VERSION "HNNBNNNYNNNNNNNNNNNNNNNNNNNNNNNNNNNNNNNNNN/4/%%%/4/'%**4NNN///"

NS_ :

BS_:

BU_: AAG BCM1 BCM2 ELV Gateway HDSG IEZS MFG MSBBR SAD SAD2 Schwerpanzer_Zusatz SitzMem_BFS SitzMem_FS SitzMem_HBFS SitzMem_HFS SitzMem_SR3 SpoilerSG TSG_BFS TSG_FS VSG VTS DK_Dummy

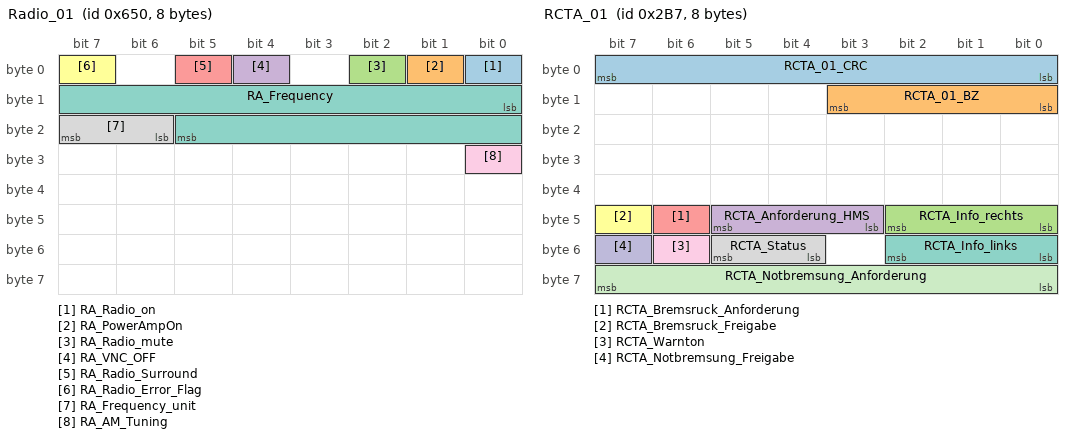
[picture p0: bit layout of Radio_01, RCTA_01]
BO_ 1616 Radio_01: 8 Gateway
 SG_ RA_Radio_on : 0|1@1+ (1,0) [0|1] ""  TSG_BFS,TSG_FS
 SG_ RA_PowerAmpOn : 1|1@1+ (1,0) [0|1] "" Vector__XXX
 SG_ RA_Radio_mute : 2|1@1+ (1,0) [0|1] "" Vector__XXX
 SG_ RA_VNC_OFF : 4|1@1+ (1,0) [0|1] "" Vector__XXX
 SG_ RA_Radio_Surround : 5|1@1+ (1,0) [0|1] "" Vector__XXX
 SG_ RA_Radio_Error_Flag : 7|1@1+ (1,0) [0|1] "" Vector__XXX
 SG_ RA_Frequency : 8|14@1+ (1,0) [0|16383] ""  HDSG,SAD,SAD2,SitzMem_BFS,SitzMem_FS,SitzMem_HBFS,SitzMem_HFS,TSG_BFS,TSG_FS
 SG_ RA_Frequency_unit : 22|2@1+ (1,0) [0|3] ""  HDSG,SAD,SAD2,SitzMem_BFS,SitzMem_FS,SitzMem_HBFS,SitzMem_HFS,TSG_BFS,TSG_FS
 SG_ RA_AM_Tuning : 24|1@1+ (1,0) [0|1] ""  HDSG,SAD,SAD2,SitzMem_BFS,SitzMem_FS,SitzMem_HBFS,SitzMem_HFS,TSG_BFS,TSG_FS

BO_ 695 RCTA_01: 8 Gateway
 SG_ RCTA_01_CRC : 0|8@1+ (1,0) [0|255] "" Vector__XXX
 SG_ RCTA_01_BZ : 8|4@1+ (1,0) [0|15] "" Vector__XXX
 SG_ RCTA_Info_rechts : 40|3@1+ (1,0) [0|7] ""  BCM1
 SG_ RCTA_Anforderung_HMS : 43|3@1+ (1,0) [0|7] "" Vector__XXX
 SG_ RCTA_Bremsruck_Anforderung : 46|1@1+ (1,0) [0|1] "" Vector__XXX
 SG_ RCTA_Bremsruck_Freigabe : 47|1@1+ (1,0) [0|1] "" Vector__XXX
 SG_ RCTA_Info_links : 48|3@1+ (1,0) [0|7] ""  BCM1
 SG_ RCTA_Status : 52|2@1+ (1,0) [0|3] ""  BCM1
 SG_ RCTA_Warnton : 54|1@1+ (1,0) [0|1] ""  BCM1
 SG_ RCTA_Notbremsung_Freigabe : 55|1@1+ (1,0) [0|1] "" Vector__XXX
 SG_ RCTA_Notbremsung_Anforderung : 56|8@1+ (0.078,-19.812) [-19.734|0] "Unit_MeterPerSeconSquar" Vector__XXX

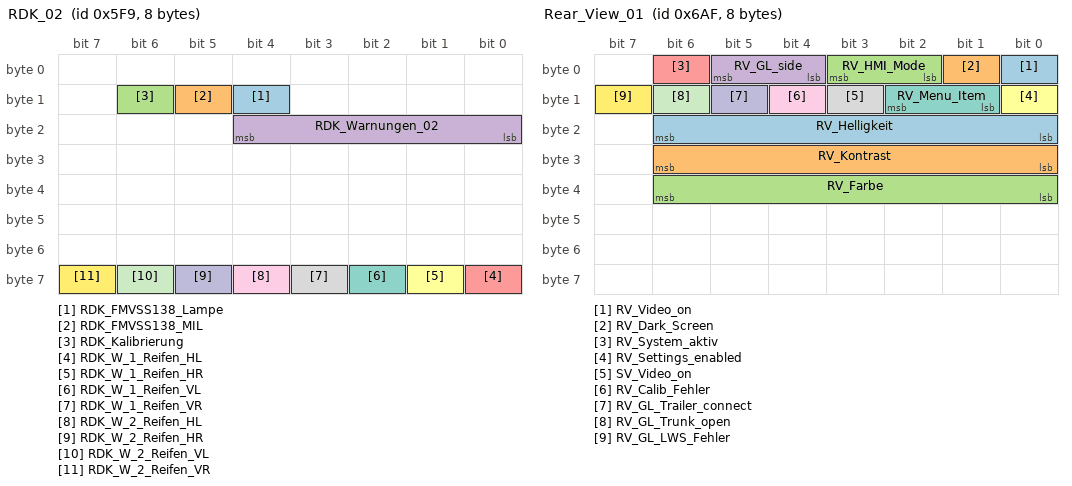
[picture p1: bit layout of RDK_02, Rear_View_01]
BO_ 1529 RDK_02: 8 Gateway
 SG_ RDK_FMVSS138_Lampe : 12|1@1+ (1,0) [0|1] "" Vector__XXX
 SG_ RDK_FMVSS138_MIL : 13|1@1+ (1,0) [0|1] "" Vector__XXX
 SG_ RDK_Kalibrierung : 14|1@1+ (1,0) [0|1] "" Vector__XXX
 SG_ RDK_Warnungen_02 : 16|5@1+ (1,0) [0|31] ""  VTS
 SG_ RDK_W_1_Reifen_HL : 56|1@1+ (1,0) [0|1] "" Vector__XXX
 SG_ RDK_W_1_Reifen_HR : 57|1@1+ (1,0) [0|1] "" Vector__XXX
 SG_ RDK_W_1_Reifen_VL : 58|1@1+ (1,0) [0|1] "" Vector__XXX
 SG_ RDK_W_1_Reifen_VR : 59|1@1+ (1,0) [0|1] "" Vector__XXX
 SG_ RDK_W_2_Reifen_HL : 60|1@1+ (1,0) [0|1] "" Vector__XXX
 SG_ RDK_W_2_Reifen_HR : 61|1@1+ (1,0) [0|1] "" Vector__XXX
 SG_ RDK_W_2_Reifen_VL : 62|1@1+ (1,0) [0|1] "" Vector__XXX
 SG_ RDK_W_2_Reifen_VR : 63|1@1+ (1,0) [0|1] "" Vector__XXX

BO_ 1711 Rear_View_01: 8 Gateway
 SG_ RV_Video_on : 0|1@1+ (1,0) [0|1] ""  BCM1
 SG_ RV_Dark_Screen : 1|1@1+ (1,0) [0|1] "" Vector__XXX
 SG_ RV_HMI_Mode : 2|2@1+ (1,0) [0|3] "" Vector__XXX
 SG_ RV_GL_side : 4|2@1+ (1,0) [0|3] "" Vector__XXX
 SG_ RV_System_aktiv : 6|1@1+ (1,0) [0|1] ""  BCM1
 SG_ RV_Settings_enabled : 8|1@1+ (1,0) [0|1] "" Vector__XXX
 SG_ RV_Menu_Item : 9|2@1+ (1,0) [0|3] "" Vector__XXX
 SG_ SV_Video_on : 11|1@1+ (1,0) [0|1] "" Vector__XXX
 SG_ RV_Calib_Fehler : 12|1@1+ (1,0) [0|1] "" Vector__XXX
 SG_ RV_GL_Trailer_connect : 13|1@1+ (1,0) [0|1] "" Vector__XXX
 SG_ RV_GL_Trunk_open : 14|1@1+ (1,0) [0|1] ""  BCM1
 SG_ RV_GL_LWS_Fehler : 15|1@1+ (1,0) [0|1] "" Vector__XXX
 SG_ RV_Helligkeit : 16|7@1+ (1,0) [0|100] "Unit_PerCent" Vector__XXX
 SG_ RV_Kontrast : 24|7@1+ (1,0) [0|100] "Unit_PerCent" Vector__XXX
 SG_ RV_Farbe : 32|7@1+ (1,0) [0|100] "Unit_PerCent" Vector__XXX

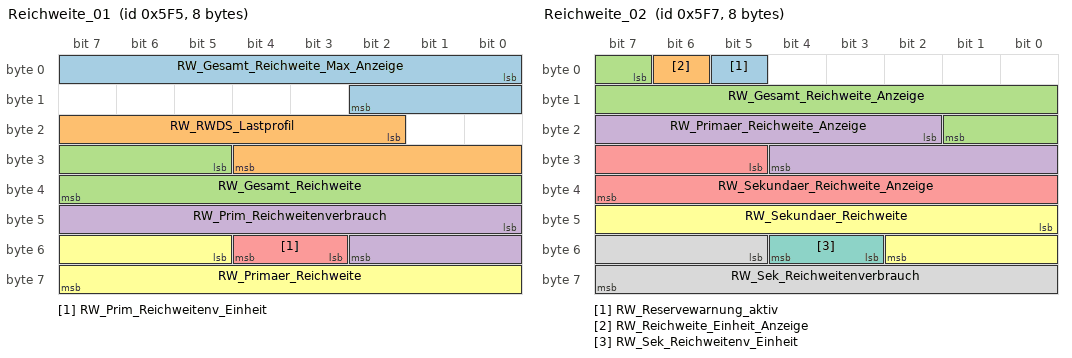
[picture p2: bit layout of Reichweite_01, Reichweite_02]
BO_ 1525 Reichweite_01: 8 Gateway
 SG_ RW_Gesamt_Reichweite_Max_Anzeige : 0|11@1+ (1,0) [0|2047] "" Vector__XXX
 SG_ RW_RWDS_Lastprofil : 18|11@1+ (1,0) [0|2045] "Unit_Amper" Vector__XXX
 SG_ RW_Gesamt_Reichweite : 29|11@1+ (1,0) [0|2044] "Unit_KiloMeter"  VTS
 SG_ RW_Prim_Reichweitenverbrauch : 40|11@1+ (0.1,0) [0|204.4] "Unit_None"  VTS
 SG_ RW_Prim_Reichweitenv_Einheit : 51|2@1+ (1,0) [0|3] ""  VTS
 SG_ RW_Primaer_Reichweite : 53|11@1+ (1,0) [0|2044] "Unit_KiloMeter"  VTS

BO_ 1527 Reichweite_02: 8 Gateway
 SG_ RW_Reservewarnung_aktiv : 5|1@1+ (1,0) [0|1] "" Vector__XXX
 SG_ RW_Reichweite_Einheit_Anzeige : 6|1@1+ (1,0) [0|1] ""  VTS
 SG_ RW_Gesamt_Reichweite_Anzeige : 7|11@1+ (1,0) [0|2044] ""  VTS
 SG_ RW_Primaer_Reichweite_Anzeige : 18|11@1+ (1,0) [0|2044] ""  VTS
 SG_ RW_Sekundaer_Reichweite_Anzeige : 29|11@1+ (1,0) [0|2044] ""  VTS
 SG_ RW_Sekundaer_Reichweite : 40|11@1+ (1,0) [0|2044] "Unit_KiloMeter"  VTS
 SG_ RW_Sek_Reichweitenv_Einheit : 51|2@1+ (1,0) [0|3] ""  VTS
 SG_ RW_Sek_Reichweitenverbrauch : 53|11@1+ (0.1,0) [0|204.4] "Unit_None"  VTS

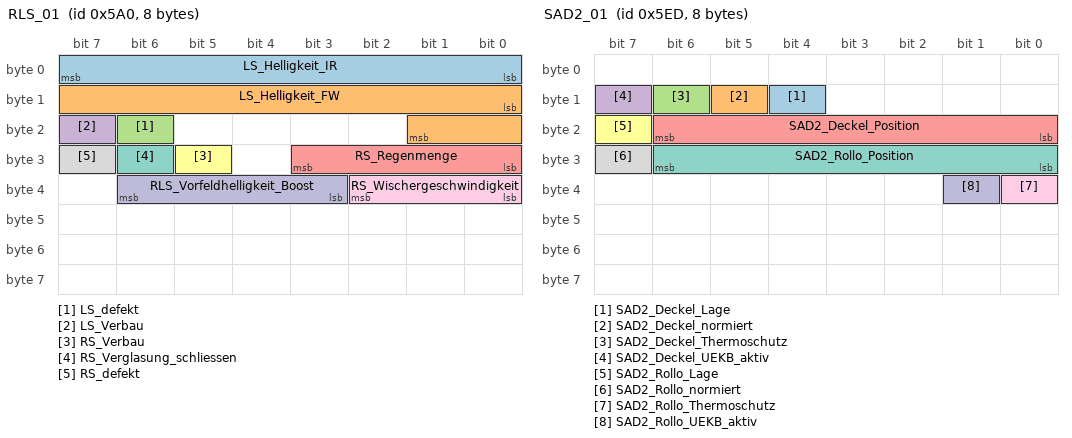
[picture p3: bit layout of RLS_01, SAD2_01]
BO_ 1440 RLS_01: 8 BCM1
 SG_ LS_Helligkeit_IR : 0|8@1+ (400,0) [0|101200] "Unit_Lux"  Gateway,MSBBR
 SG_ LS_Helligkeit_FW : 8|10@1+ (6,0) [0|6126] "Unit_Lux"  Gateway,MSBBR
 SG_ LS_defekt : 22|1@1+ (1,0) [0|1] ""  Gateway,MSBBR
 SG_ LS_Verbau : 23|1@1+ (1,0) [0|1] ""  Gateway
 SG_ RS_Regenmenge : 24|4@1+ (10,0) [0|100] "Unit_PerCent"  Gateway,MSBBR
 SG_ RS_Verbau : 29|1@1+ (1,0) [0|1] ""  Gateway
 SG_ RS_Verglasung_schliessen : 30|1@1+ (1,0) [0|1] ""  Gateway,SAD,SAD2,TSG_BFS,TSG_FS
 SG_ RS_defekt : 31|1@1+ (1,0) [0|1] ""  Gateway,MSBBR,SAD,SAD2,TSG_BFS,TSG_FS
 SG_ RS_Wischergeschwindigkeit : 32|3@1+ (1,0) [0|7] ""  Gateway,MSBBR
 SG_ RLS_Vorfeldhelligkeit_Boost : 35|4@1+ (1,0) [0|15] ""  Gateway,MSBBR

BO_ 1517 SAD2_01: 8 SAD2
 SG_ SAD2_Deckel_Lage : 12|1@1+ (1,0) [0|1] ""  Gateway,SAD
 SG_ SAD2_Deckel_normiert : 13|1@1+ (1,0) [0|1] ""  BCM2,Gateway,SAD
 SG_ SAD2_Deckel_Thermoschutz : 14|1@1+ (1,0) [0|1] ""  BCM2,Gateway,SAD
 SG_ SAD2_Deckel_UEKB_aktiv : 15|1@1+ (1,0) [0|1] ""  BCM2,Gateway,SAD
 SG_ SAD2_Deckel_Position : 16|7@1+ (1,0) [0|100] "Unit_PerCent"  BCM2,Gateway,SAD
 SG_ SAD2_Rollo_Lage : 23|1@1+ (1,0) [0|1] ""  Gateway,SAD
 SG_ SAD2_Rollo_Position : 24|7@1+ (1,0) [0|100] "Unit_PerCent"  Gateway,SAD
 SG_ SAD2_Rollo_normiert : 31|1@1+ (1,0) [0|1] ""  BCM2,Gateway,SAD
 SG_ SAD2_Rollo_Thermoschutz : 32|1@1+ (1,0) [0|1] ""  BCM2,Gateway,SAD
 SG_ SAD2_Rollo_UEKB_aktiv : 33|1@1+ (1,0) [0|1] ""  BCM2,Gateway,SAD

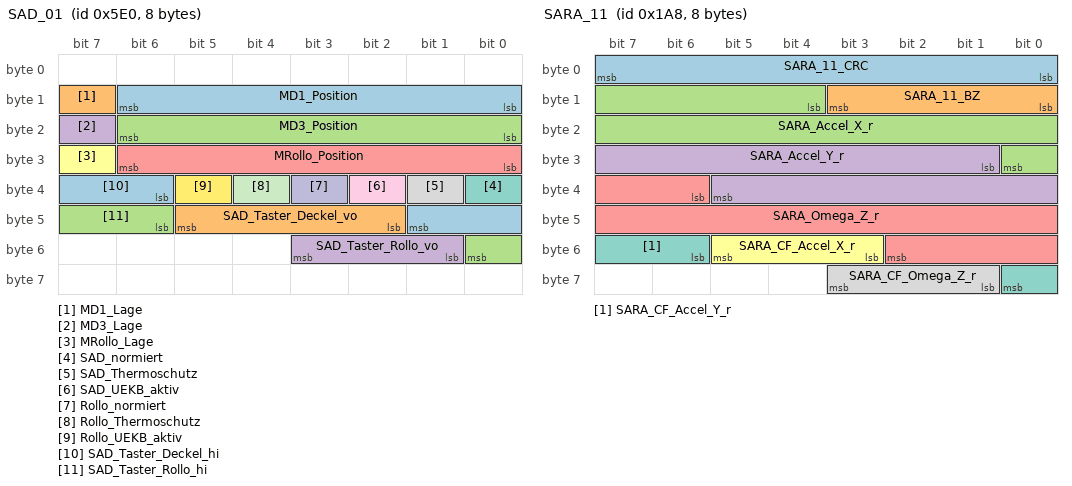
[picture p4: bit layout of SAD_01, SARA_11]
BO_ 1504 SAD_01: 8 SAD
 SG_ MD1_Position : 8|7@1+ (1,0) [0|100] "Unit_PerCent"  BCM2,Gateway,SAD2,SpoilerSG,VTS
 SG_ MD1_Lage : 15|1@1+ (1,0) [0|1] ""  BCM1,Gateway,SAD2,SpoilerSG,VTS
 SG_ MD3_Position : 16|7@1+ (1,0) [0|100] "Unit_PerCent"  BCM2,Gateway,SAD2,SpoilerSG,VTS
 SG_ MD3_Lage : 23|1@1+ (1,0) [0|1] ""  Gateway,SAD2,SpoilerSG,VTS
 SG_ MRollo_Position : 24|7@1+ (1,0) [0|100] "Unit_PerCent"  Gateway,SAD2,VTS
 SG_ MRollo_Lage : 31|1@1+ (1,0) [0|1] ""  Gateway,SAD2,VTS
 SG_ SAD_normiert : 32|1@1+ (1,0) [0|1] ""  BCM2,Gateway,SAD2,VTS
 SG_ SAD_Thermoschutz : 33|1@1+ (1,0) [0|1] ""  BCM2,Gateway,SAD2
 SG_ SAD_UEKB_aktiv : 34|1@1+ (1,0) [0|1] ""  BCM2,Gateway,SAD2
 SG_ Rollo_normiert : 35|1@1+ (1,0) [0|1] ""  BCM2,Gateway,SAD2,VTS
 SG_ Rollo_Thermoschutz : 36|1@1+ (1,0) [0|1] ""  BCM2,Gateway,SAD2
 SG_ Rollo_UEKB_aktiv : 37|1@1+ (1,0) [0|1] ""  BCM2,Gateway,SAD2
 SG_ SAD_Taster_Deckel_hi : 38|4@1+ (1,0) [0|15] ""  Gateway,SAD2
 SG_ SAD_Taster_Deckel_vo : 42|4@1+ (1,0) [0|15] ""  Gateway,SAD2
 SG_ SAD_Taster_Rollo_hi : 46|3@1+ (1,0) [0|7] ""  Gateway,SAD2
 SG_ SAD_Taster_Rollo_vo : 49|3@1+ (1,0) [0|7] ""  Gateway,SAD2

BO_ 424 SARA_11: 8 Gateway
 SG_ SARA_11_CRC : 0|8@1+ (1,0) [0|255] ""  BCM1
 SG_ SARA_11_BZ : 8|4@1+ (1,0) [0|15] ""  BCM1
 SG_ SARA_Accel_X_r : 12|13@1+ (0.16,-655.36) [-655.2|655.04] "Unit_MeterPerSeconSquar"  BCM1,HDSG,MFG,MSBBR,SitzMem_BFS,SitzMem_FS,SitzMem_HBFS,SitzMem_HFS
 SG_ SARA_Accel_Y_r : 25|13@1+ (0.16,-655.36) [-655.2|655.04] "Unit_MeterPerSeconSquar"  BCM1,HDSG,SitzMem_BFS,SitzMem_FS,SitzMem_HBFS,SitzMem_HFS
 SG_ SARA_Omega_Z_r : 38|13@1+ (0.08,-327.68) [-327.6|327.52] "Unit_DegreOfArcPerSecon"  BCM1
 SG_ SARA_CF_Accel_X_r : 51|3@1+ (1,0) [0|7] ""  BCM1,HDSG,MFG,MSBBR
 SG_ SARA_CF_Accel_Y_r : 54|3@1+ (1,0) [0|7] ""  BCM1,HDSG
 SG_ SARA_CF_Omega_Z_r : 57|3@1+ (1,0) [0|7] ""  BCM1

BO_ 1522 Sensorik_Dimmung_01: 2 Gateway
 SG_ KBI_Phototransistor : 0|8@1+ (1,0) [0|253] ""  BCM1
 SG_ KBI_Dimmpoti : 8|7@1+ (1,0) [0|100] "Unit_PerCent"  BCM1

BO_ 1363 Sitzmemo_SR3_01: 8 SitzMem_SR3
 SG_ SR3_Status_Lehne_Links : 12|1@1+ (1,0) [0|1] ""  Gateway
 SG_ SR3_Status_Lehne_Rechts : 13|1@1+ (1,0) [0|1] ""  Gateway

BO_ 980 SMLS_01: 8 Gateway
 SG_ SMLS_01_CRC : 0|8@1+ (1,0) [0|255] ""  BCM1,BCM2
 SG_ SMLS_01_BZ : 8|4@1+ (1,0) [0|15] ""  BCM1,BCM2
 SG_ BH_Blinker_li : 12|1@1+ (1,0) [0|1] ""  BCM1,BCM2
 SG_ BH_Blinker_re : 13|1@1+ (1,0) [0|1] ""  BCM1,BCM2
 SG_ BH_Lichthupe : 14|1@1+ (1,0) [0|1] ""  BCM1
 SG_ BH_Fernlicht : 15|1@1+ (1,0) [0|1] ""  BCM1
 SG_ WH_Tipwischen : 16|1@1+ (1,0) [0|1] ""  BCM1
 SG_ WH_Intervall : 17|1@1+ (1,0) [0|1] ""  BCM1
 SG_ WH_WischerStufe1 : 18|1@1+ (1,0) [0|1] ""  BCM1
 SG_ WH_WischerStufe2 : 19|1@1+ (1,0) [0|1] ""  BCM1
 SG_ WH_Frontwaschen : 20|1@1+ (1,0) [0|1] ""  BCM1
 SG_ WH_Heckintervall : 21|1@1+ (1,0) [0|1] ""  BCM1
 SG_ WH_Heckwaschen : 22|1@1+ (1,0) [0|1] ""  BCM1
 SG_ WH_Intervallstufen : 23|4@1+ (1,0) [0|15] ""  BCM1
 SG_ FAS_Taster : 27|1@1+ (1,0) [0|1] "" Vector__XXX
 SG_ FAS_Taster_Fehler : 28|1@1+ (1,0) [0|1] "" Vector__XXX
 SG_ SMLS_Hupe : 29|1@1+ (1,0) [0|1] ""  BCM1,MFG
 SG_ LRH_on_off : 30|2@1+ (1,0) [0|3] "" Vector__XXX
 SG_ LRH_aktiv : 40|1@1+ (1,0) [0|1] "" Vector__XXX
 SG_ SMLS_P_verriegelt_plausibel : 43|1@1+ (1,0) [0|1] "" Vector__XXX
 SG_ WH_SRA : 44|1@1+ (1,0) [0|1] ""  BCM1
 SG_ WH_Wischer_Fehler : 45|1@1+ (1,0) [0|1] ""  BCM1
 SG_ BH_Blinker_Fehler : 46|1@1+ (1,0) [0|1] ""  BCM2

BO_ 1467 SoSe_01: 8 BCM1
 SG_ SoSe_SunInt_2D_Li : 0|8@1+ (5,0) [0|1200] "Unit_WattPerMeterSquar"  Gateway
 SG_ SoSe_SunInt_2D_Re : 8|8@1+ (5,0) [0|1200] "Unit_WattPerMeterSquar"  Gateway

BO_ 1710 Spiegel_01: 8 TSG_FS
 SG_ SP_FT_oben : 0|1@1+ (1,0) [0|1] ""  Gateway,MFG,TSG_BFS
 SG_ SP_FT_unten : 1|1@1+ (1,0) [0|1] ""  Gateway,MFG,TSG_BFS
 SG_ SP_FT_links : 2|1@1+ (1,0) [0|1] ""  Gateway,MFG,TSG_BFS
 SG_ SP_FT_rechts : 3|1@1+ (1,0) [0|1] ""  Gateway,MFG,TSG_BFS
 SG_ SP_BT_oben : 4|1@1+ (1,0) [0|1] ""  Gateway,MFG,TSG_BFS
 SG_ SP_BT_unten : 5|1@1+ (1,0) [0|1] ""  Gateway,MFG,TSG_BFS
 SG_ SP_BT_links : 6|1@1+ (1,0) [0|1] ""  Gateway,MFG,TSG_BFS
 SG_ SP_BT_rechts : 7|1@1+ (1,0) [0|1] ""  Gateway,MFG,TSG_BFS
 SG_ SP_abklappen : 8|1@1+ (1,0) [0|1] ""  Gateway,MFG,TSG_BFS
 SG_ SP_anklappen : 9|1@1+ (1,0) [0|1] ""  Gateway,MFG,TSG_BFS
 SG_ SP_normieren : 10|1@1+ (1,0) [0|1] ""  Gateway,MFG,TSG_BFS
 SG_ SP_Hzg_Taster : 12|1@1+ (1,0) [0|1] ""  Gateway,MFG,TSG_BFS
 SG_ SP_S_oben : 16|1@1+ (1,0) [0|1] ""  Gateway,TSG_BFS
 SG_ SP_S_unten : 17|1@1+ (1,0) [0|1] ""  Gateway,TSG_BFS
 SG_ SP_S_links : 18|1@1+ (1,0) [0|1] ""  Gateway,TSG_BFS
 SG_ SP_S_rechts : 19|1@1+ (1,0) [0|1] ""  Gateway,TSG_BFS
 SG_ SP_Auswahl_li : 20|1@1+ (1,0) [0|1] ""  Gateway,MFG,TSG_BFS
 SG_ SP_Auswahl_re : 21|1@1+ (1,0) [0|1] ""  Gateway,MFG,TSG_BFS
 SG_ SP_ARA_Status : 22|1@1+ (1,0) [0|1] ""  Gateway
 SG_ SP_S_Klappen : 23|1@1+ (1,0) [0|1] ""  Gateway,MFG,TSG_BFS
 SG_ SP_Verstellschalter_Fehler : 24|1@1+ (1,0) [0|1] ""  BCM1,Gateway

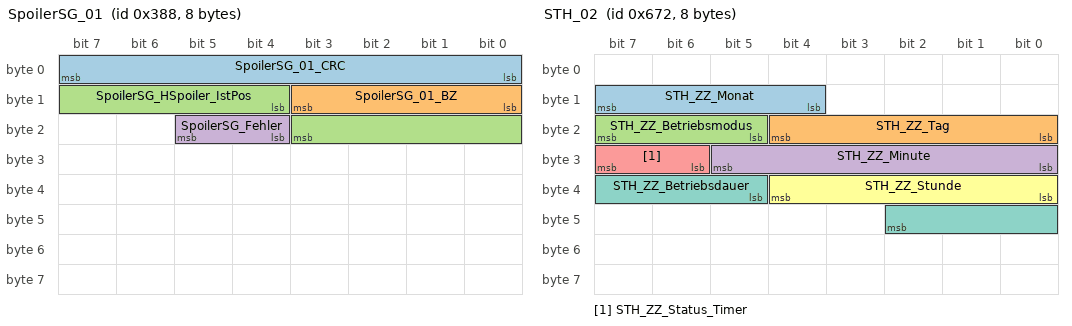
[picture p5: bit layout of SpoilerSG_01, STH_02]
BO_ 904 SpoilerSG_01: 8 SpoilerSG
 SG_ SpoilerSG_01_CRC : 0|8@1+ (1,0) [0|255] ""  Gateway
 SG_ SpoilerSG_01_BZ : 8|4@1+ (1,0) [0|15] ""  Gateway
 SG_ SpoilerSG_HSpoiler_IstPos : 12|8@1+ (4,0) [0|1012] ""  BCM2,Gateway
 SG_ SpoilerSG_Fehler : 20|2@1+ (1,0) [0|3] ""  Gateway

BO_ 1313 STH_01: 8 Gateway
 SG_ STH_Funk_ein : 0|1@1+ (1,0) [0|1] "" Vector__XXX
 SG_ STH_Funk_aus : 1|1@1+ (1,0) [0|1] "" Vector__XXX
 SG_ STH_Zusatzheizung : 2|1@1+ (1,0) [0|1] "" Vector__XXX
 SG_ STH_LED : 3|1@1+ (1,0) [0|1] ""  VTS
 SG_ STH_Pumpe_ein : 4|1@1+ (1,0) [0|1] "" Vector__XXX
 SG_ STH_Geblaese : 5|1@1+ (1,0) [0|1] "" Vector__XXX
 SG_ STH_EKP_Anst : 6|1@1+ (1,0) [0|1] "" Vector__XXX
 SG_ STH_Start_folgt : 7|1@1+ (1,0) [0|1] "" Vector__XXX
 SG_ STH_Ventiloeffnungszeit : 8|6@1+ (1,0) [0|63] "Unit_Minut" Vector__XXX
 SG_ STH_Ventil_Status : 14|1@1+ (1,0) [0|1] "" Vector__XXX
 SG_ STH_Fehler_ElWaPu : 15|1@1+ (1,0) [0|1] "" Vector__XXX
 SG_ STH_Waermeeintrag : 16|6@1+ (1,0) [0|63] "" Vector__XXX
 SG_ STH_Pumpen_Anf_extern : 22|1@1+ (1,0) [0|1] "" Vector__XXX
 SG_ STH_KVS : 24|13@1+ (1,0) [0|8191] "Unit_MilliLiter" Vector__XXX
 SG_ STH_Fehlerstatus : 37|3@1+ (1,0) [0|7] ""  VTS
 SG_ STH_Heizleistung : 40|8@1+ (1,0) [0|255] "" Vector__XXX
 SG_ STH_Wassertemp : 48|8@1+ (0.75,-40) [-40|142.25] "Unit_DegreCelsi" Vector__XXX
 SG_ STH_Texte : 56|3@1+ (1,0) [0|7] "" Vector__XXX
 SG_ STH_Motorvorwaermung : 59|1@1+ (1,0) [0|1] "" Vector__XXX
 SG_ STH_Servicemode : 60|1@1+ (1,0) [0|1] "" Vector__XXX
 SG_ STH_war_aktiv : 61|1@1+ (1,0) [0|1] "" Vector__XXX
 SG_ STH_KVS_Ueberlauf : 62|1@1+ (1,0) [0|1] "" Vector__XXX

BO_ 1650 STH_02: 8 Gateway
 SG_ STH_ZZ_Monat : 12|4@1+ (1,0) [1|12] ""  VTS
 SG_ STH_ZZ_Tag : 16|5@1+ (1,0) [1|31] "Unit_Day"  VTS
 SG_ STH_ZZ_Betriebsmodus : 21|3@1+ (1,0) [0|7] ""  VTS
 SG_ STH_ZZ_Minute : 24|6@1+ (1,0) [0|59] ""  VTS
 SG_ STH_ZZ_Status_Timer : 30|2@1+ (1,0) [0|3] ""  VTS
 SG_ STH_ZZ_Stunde : 32|5@1+ (1,0) [0|23] ""  VTS
 SG_ STH_ZZ_Betriebsdauer : 37|6@1+ (1,0) [0|63] "Unit_Minut"  VTS

BO_ 1172 STS_01: 8 VTS
 SG_ STS_01_CRC : 0|8@1+ (1,0) [0|255] ""  BCM2,Gateway
 SG_ STS_01_BZ : 8|4@1+ (1,0) [0|15] ""  BCM2,Gateway
 SG_ STS_Car_not_under_theft : 12|1@1+ (1,0) [0|1] ""  Gateway
 SG_ STS_Car_under_theft : 13|1@1+ (1,0) [0|1] ""  Gateway
 SG_ STS_Anlassersperre : 15|1@1+ (1,0) [0|1] ""  BCM2,Gateway
 SG_ STS_Typencodierung : 16|5@1+ (1,0) [0|31] ""  Gateway
 SG_ STS_LIN_aktiv : 23|1@1+ (1,0) [0|1] ""  Gateway
 SG_ STS_Standlicht : 24|1@1+ (1,0) [0|1] ""  BCM1,Gateway
 SG_ STS_Fahrlicht : 25|1@1+ (1,0) [0|1] ""  BCM1,Gateway
 SG_ STS_Alarm_still : 26|1@1+ (1,0) [0|1] ""  Gateway
 SG_ STS_Texte : 27|4@1+ (1,0) [0|15] ""  Gateway
 SG_ STS_Laderelais : 38|1@1+ (1,0) [0|1] ""  Gateway
 SG_ STS_Summer : 48|1@1+ (1,0) [0|1] ""  Gateway
 SG_ STS_Alarm_Blinker : 50|1@1+ (1,0) [0|1] ""  BCM2,Gateway
 SG_ STS_Notstart : 51|1@1+ (1,0) [0|1] ""  Gateway
 SG_ STS_Signalhorn : 55|1@1+ (1,0) [0|1] ""  BCM1,Gateway
 SG_ STS_Leerlaufschaltung : 56|1@1+ (1,0) [0|1] ""  Gateway

BO_ 783 SWA_01: 8 Gateway
 SG_ SWA_01_CRC : 0|8@1+ (1,0) [0|255] "" Vector__XXX
 SG_ SWA_01_BZ : 8|4@1+ (1,0) [0|15] "" Vector__XXX
 SG_ SWA_Anzeigen : 12|4@1+ (1,0) [0|15] "" Vector__XXX
 SG_ SWA_Blindheit_erkannt : 16|1@1+ (1,0) [0|1] "" Vector__XXX
 SG_ SWA_rel_Nichtverf : 17|1@1+ (1,0) [0|1] "" Vector__XXX
 SG_ SWA_rel_Fehler : 18|1@1+ (1,0) [0|1] "" Vector__XXX
 SG_ SWA_Sta_aktiv : 19|1@1+ (1,0) [0|1] "" Vector__XXX
 SG_ SWA_Sta_passiv : 20|1@1+ (1,0) [0|1] "" Vector__XXX
 SG_ SWA_FT_RueckLED : 21|1@1+ (1,0) [0|1] ""  BCM1,TSG_FS
 SG_ ASW_Status : 22|2@1+ (1,0) [0|3] ""  TSG_BFS,TSG_FS
 SG_ SWA_Standziele_li : 24|1@1+ (1,0) [0|1] "" Vector__XXX
 SG_ SWA_Kolonne_li : 25|1@1+ (1,0) [0|1] "" Vector__XXX
 SG_ SWA_Infostufe_SWA_li : 26|1@1+ (1,0) [0|1] "" Vector__XXX
 SG_ SWA_Warnung_SWA_li : 27|1@1+ (1,0) [0|1] "" Vector__XXX
 SG_ ASW_Warnung_FS : 28|1@1+ (1,0) [0|1] ""  TSG_BFS,TSG_FS
 SG_ ASW_Warnung_BFS : 29|1@1+ (1,0) [0|1] ""  TSG_BFS,TSG_FS
 SG_ ASW_Kombitexte : 30|3@1+ (1,0) [0|7] "" Vector__XXX
 SG_ SWA_Kolonne_mi : 33|1@1+ (1,0) [0|1] "" Vector__XXX
 SG_ SWA_Standziele_re : 40|1@1+ (1,0) [0|1] "" Vector__XXX
 SG_ SWA_Kolonne_re : 41|1@1+ (1,0) [0|1] "" Vector__XXX
 SG_ SWA_Infostufe_SWA_re : 42|1@1+ (1,0) [0|1] "" Vector__XXX
 SG_ SWA_Warnung_SWA_re : 43|1@1+ (1,0) [0|1] "" Vector__XXX
 SG_ HRE_Anzeigetexte : 44|4@1+ (1,0) [0|15] "" Vector__XXX
 SG_ SWA_Gischtzaehler : 48|7@1+ (1,0) [0|100] "Unit_PerCent"  MSBBR
 SG_ Heckradar_Kombitexte : 56|5@1+ (1,0) [0|31] "" Vector__XXX
 SG_ RCTA_Kombitexte : 61|3@1+ (1,0) [0|7] "" Vector__XXX

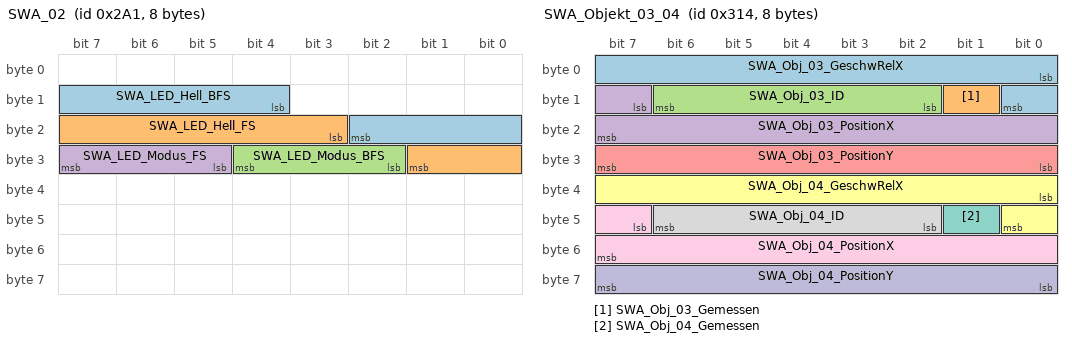
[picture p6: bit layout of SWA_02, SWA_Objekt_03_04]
BO_ 673 SWA_02: 8 Gateway
 SG_ SWA_LED_Hell_BFS : 12|7@1+ (1,0) [0|100] "Unit_PerCent"  TSG_BFS
 SG_ SWA_LED_Hell_FS : 19|7@1+ (1,0) [0|100] "Unit_PerCent"  TSG_FS
 SG_ SWA_LED_Modus_BFS : 26|3@1+ (1,0) [0|7] ""  TSG_BFS
 SG_ SWA_LED_Modus_FS : 29|3@1+ (1,0) [0|7] ""  TSG_FS

BO_ 788 SWA_Objekt_03_04: 8 Gateway
 SG_ SWA_Obj_03_GeschwRelX : 0|9@1+ (0.25,-37.5) [-37.5|90] "Unit_MeterPerSecon" Vector__XXX
 SG_ SWA_Obj_03_Gemessen : 9|1@1+ (1,0) [0|1] "" Vector__XXX
 SG_ SWA_Obj_03_ID : 10|5@1+ (1,0) [1|30] "" Vector__XXX
 SG_ SWA_Obj_03_PositionX : 15|9@1+ (0.25,-102.5) [-102.5|25] "Unit_Meter"  MSBBR
 SG_ SWA_Obj_03_PositionY : 24|8@1+ (0.125,-16) [-16|15.75] "Unit_Meter" Vector__XXX
 SG_ SWA_Obj_04_GeschwRelX : 32|9@1+ (0.25,-37.5) [-37.5|90] "Unit_MeterPerSecon" Vector__XXX
 SG_ SWA_Obj_04_Gemessen : 41|1@1+ (1,0) [0|1] "" Vector__XXX
 SG_ SWA_Obj_04_ID : 42|5@1+ (1,0) [1|30] "" Vector__XXX
 SG_ SWA_Obj_04_PositionX : 47|9@1+ (0.25,-102.5) [-102.5|25] "Unit_Meter"  MSBBR
 SG_ SWA_Obj_04_PositionY : 56|8@1+ (0.125,-16) [-16|15.75] "Unit_Meter" Vector__XXX

BO_ 1413 Systeminfo_01: 8 Gateway
 SG_ SI_Sammel_SG_Fehler : 0|6@1+ (1,0) [0|60] ""  BCM2
 SG_ SI_Diagnose_Aktiv : 7|1@1+ (1,0) [0|1] ""  BCM2
 SG_ SI_QRS_Mode : 8|1@1+ (1,0) [0|1] ""  AAG,BCM1,BCM2,HDSG,IEZS,SAD,SAD2,SitzMem_BFS,SitzMem_FS,SitzMem_HBFS,SitzMem_HFS,SitzMem_SR3,TSG_BFS,TSG_FS
 SG_ SI_T_Mode : 9|1@1+ (1,0) [0|1] ""  BCM1,BCM2,HDSG,IEZS,SAD,SAD2,SitzMem_BFS,SitzMem_FS,SitzMem_HBFS,SitzMem_HFS,SitzMem_SR3,SpoilerSG,TSG_BFS,TSG_FS
 SG_ SI_NWDF : 10|1@1+ (1,0) [0|1] ""  AAG,BCM1,BCM2,ELV,HDSG,IEZS,MFG,SAD,SAD2,SitzMem_BFS,SitzMem_FS,SitzMem_HBFS,SitzMem_HFS,SitzMem_SR3,TSG_BFS,TSG_FS,VSG,VTS
 SG_ SI_NWDF_gueltig : 11|1@1+ (1,0) [0|1] ""  AAG,BCM1,BCM2,ELV,HDSG,IEZS,MFG,SAD,SAD2,SitzMem_BFS,SitzMem_FS,SitzMem_HBFS,SitzMem_HFS,SitzMem_SR3,TSG_BFS,TSG_FS,VSG,VTS
 SG_ SI_Sammelfehler : 12|1@1+ (1,0) [0|1] "" Vector__XXX
 SG_ GW_KD_Fehler : 13|1@1+ (1,0) [0|1] "" Vector__XXX
 SG_ SI_T_Schutz : 14|1@1+ (1,0) [0|1] ""  BCM1,BCM2,SAD,SAD2,TSG_BFS,TSG_FS
 SG_ SI_BUS_01 : 16|1@1+ (1,0) [0|1] ""  BCM2
 SG_ SI_BUS_02 : 17|1@1+ (1,0) [0|1] ""  VTS
 SG_ SI_BUS_03 : 18|1@1+ (1,0) [0|1] "" Vector__XXX
 SG_ SI_BUS_04 : 19|1@1+ (1,0) [0|1] ""  BCM2,HDSG
 SG_ SI_BUS_05 : 20|1@1+ (1,0) [0|1] "" Vector__XXX
 SG_ SI_BUS_06 : 21|1@1+ (1,0) [0|1] ""  BCM2
 SG_ SI_BUS_07 : 22|1@1+ (1,0) [0|1] "" Vector__XXX
 SG_ SI_BUS_08 : 23|1@1+ (1,0) [0|1] "" Vector__XXX
 SG_ SI_BUS_09 : 24|1@1+ (1,0) [0|1] "" Vector__XXX
 SG_ SI_BUS_10 : 25|1@1+ (1,0) [0|1] ""  AAG,BCM2,HDSG
 SG_ SI_BUS_11 : 26|1@1+ (1,0) [0|1] "" Vector__XXX
 SG_ SI_BUS_12 : 27|1@1+ (1,0) [0|1] "" Vector__XXX
 SG_ SI_BUS_13 : 28|1@1+ (1,0) [0|1] "" Vector__XXX
 SG_ SI_BUS_14 : 29|1@1+ (1,0) [0|1] "" Vector__XXX
 SG_ SI_BUS_15 : 30|1@1+ (1,0) [0|1] "" Vector__XXX
 SG_ SI_Bus_Identifikation : 32|8@1+ (1,0) [0|255] "" Vector__XXX
 SG_ SI_CAB : 40|24@1+ (1,0) [0|16777215] "" Vector__XXX

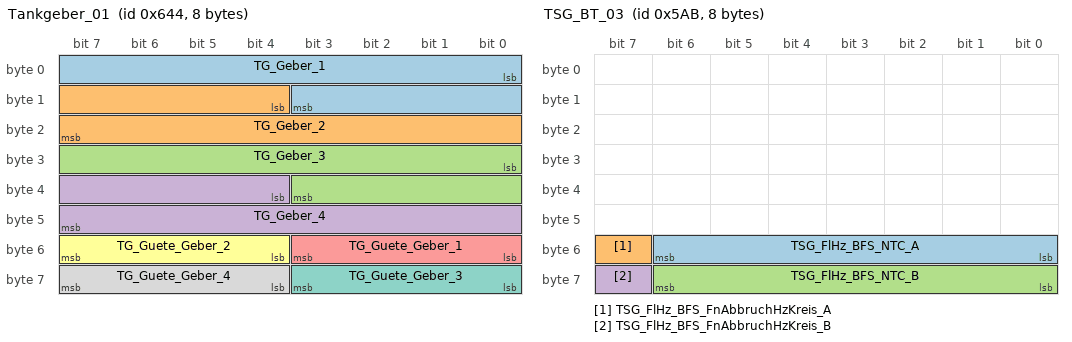
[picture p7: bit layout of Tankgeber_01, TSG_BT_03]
BO_ 1604 Tankgeber_01: 8 BCM2
 SG_ TG_Geber_1 : 0|12@1+ (1,0) [1|4094] "Unit_Ohm"  Gateway
 SG_ TG_Geber_2 : 12|12@1+ (1,0) [1|4094] "Unit_Ohm"  Gateway
 SG_ TG_Geber_3 : 24|12@1+ (1,0) [1|4094] "Unit_Ohm"  Gateway
 SG_ TG_Geber_4 : 36|12@1+ (1,0) [1|4094] "Unit_Ohm"  Gateway
 SG_ TG_Guete_Geber_1 : 48|4@1+ (1,0) [0|15] ""  Gateway
 SG_ TG_Guete_Geber_2 : 52|4@1+ (1,0) [0|15] ""  Gateway
 SG_ TG_Guete_Geber_3 : 56|4@1+ (1,0) [0|15] ""  Gateway
 SG_ TG_Guete_Geber_4 : 60|4@1+ (1,0) [0|15] ""  Gateway

BO_ 977 TSG_BT_01: 8 TSG_BFS
 SG_ BT_Tuer_geoeffnet : 0|1@1+ (1,0) [0|1] ""  BCM2,Gateway,IEZS,MFG,SitzMem_BFS,VTS
 SG_ BT_verriegelt : 1|1@1+ (1,0) [0|1] ""  BCM2,Gateway,MFG,VTS
 SG_ BT_gesafet : 2|1@1+ (1,0) [0|1] ""  BCM2,Gateway,MFG,VTS
 SG_ BT_Schluesselschalter_auf : 3|1@1+ (1,0) [0|1] ""  BCM2,Gateway,MFG
 SG_ BT_Schluesselschalter_zu : 4|1@1+ (1,0) [0|1] ""  BCM2,Gateway,MFG
 SG_ BT_Unlock_Taster : 5|1@1+ (1,0) [0|1] ""  BCM2,Gateway,MFG,TSG_FS
 SG_ BT_Lock_Taster : 6|1@1+ (1,0) [0|1] ""  BCM2,Gateway,MFG,TSG_FS
 SG_ BT_Sperrklinke : 7|1@1+ (1,0) [0|1] ""  BCM2,Gateway,MFG
 SG_ BT_TAG_betaetigt : 8|1@1+ (1,0) [0|1] ""  Gateway,MFG,TSG_FS,VTS
 SG_ BT_TIG_betaetigt : 9|1@1+ (1,0) [0|1] ""  BCM1,BCM2,Gateway,MFG,TSG_FS
 SG_ BT_EC_Spiegel_Helligkeit : 10|5@1+ (3.125,0) [0|96.875] "Unit_PerCent"  Gateway,MFG,TSG_FS
 SG_ BT_Sp_Heizung_Anf : 15|1@1+ (100,0) [0|100] "Unit_PerCent"  Gateway
 SG_ BT_Tuer_Status : 16|2@1+ (1,0) [0|3] ""  Gateway,TSG_FS
 SG_ BT_TSG_hinten_verbaut : 18|1@1+ (1,0) [0|1] ""  Gateway
 SG_ BT_Sp_Blk_def : 19|1@1+ (1,0) [0|1] ""  BCM1,Gateway,MFG
 SG_ BT_FH_S_ManHoch : 20|1@1+ (1,0) [0|1] ""  BCM2,Gateway,MFG
 SG_ BT_FH_S_AutoHoch : 21|1@1+ (1,0) [0|1] ""  BCM2,Gateway,MFG
 SG_ BT_FH_S_ManTief : 22|1@1+ (1,0) [0|1] ""  BCM2,Gateway,MFG
 SG_ BT_FH_S_AutoTief : 23|1@1+ (1,0) [0|1] ""  BCM2,Gateway,MFG
 SG_ BT_FH_Oeffnung : 24|8@1+ (0.5,0) [0|100] "Unit_PerCent"  BCM1,BCM2,Gateway,MFG,SAD,SAD2,VSG,VTS
 SG_ BT_FH_Bew_hoch : 32|1@1+ (1,0) [0|1] ""  Gateway,MFG,TSG_FS,VSG
 SG_ BT_FH_Bew_tief : 33|1@1+ (1,0) [0|1] ""  Gateway,MFG,TSG_FS
 SG_ BT_FH_Fang : 34|1@1+ (1,0) [0|1] ""  Gateway,MFG
 SG_ BT_FH_Block : 35|1@1+ (1,0) [0|1] ""  Gateway,MFG
 SG_ BT_FH_Thermo : 36|1@1+ (1,0) [0|1] ""  BCM2,Gateway,MFG
 SG_ BT_UEKB_aktiviert : 37|1@1+ (1,0) [0|1] ""  BCM2,Gateway,MFG
 SG_ BT_Kisi_Fehler : 38|1@1+ (1,0) [0|1] ""  Gateway,TSG_FS
 SG_ BT_FH_normiert : 39|1@1+ (1,0) [0|1] ""  BCM2,Gateway,MFG,TSG_FS,VSG,VTS
 SG_ BT_Schliesstaster : 40|1@1+ (1,0) [0|1] ""  Gateway
 SG_ BT_Zuziehhilfe_aktiv : 41|1@1+ (1,0) [0|1] ""  Gateway
 SG_ BT_SP_ausgerastet : 42|1@1+ (1,0) [0|1] ""  Gateway,MFG,TSG_FS,VTS
 SG_ BT_SP_lr_aktiv : 43|1@1+ (1,0) [0|1] ""  Gateway,MFG,TSG_FS
 SG_ BT_SP_ht_aktiv : 44|1@1+ (1,0) [0|1] ""  Gateway,MFG,TSG_FS
 SG_ BT_SP_Heizung_aktiv : 45|1@1+ (1,0) [0|1] ""  Gateway
 SG_ BT_Oben_Block_erw : 46|1@1+ (1,0) [0|1] ""  Gateway,MFG,TSG_FS
 SG_ BT_Unten_Block_erw : 47|1@1+ (1,0) [0|1] ""  Gateway,MFG,TSG_FS
 SG_ BT_SP_Heizung_Status : 55|1@1+ (1,0) [0|1] ""  BCM1,Gateway,MFG
 SG_ ASW_Warnung_aktiv_BFS : 56|1@1+ (1,0) [0|1] ""  BCM1,Gateway
 SG_ BT_FH_Pos_oben : 57|1@1+ (1,0) [0|1] ""  Gateway,MFG,VSG
 SG_ BT_Tuerschloss_defekt : 58|1@1+ (1,0) [0|1] ""  BCM2,Gateway
 SG_ BT_Tuerschloss_verrieg_nicht : 59|1@1+ (1,0) [0|1] ""  Gateway
 SG_ BT_Lock_Taster_inv : 60|1@1+ (1,0) [0|1] ""  BCM2,Gateway
 SG_ BT_Schluesselschalter_zu_inv : 61|1@1+ (1,0) [0|1] ""  BCM2,Gateway

BO_ 1451 TSG_BT_03: 8 TSG_BFS
 SG_ TSG_FlHz_BFS_NTC_A : 48|7@1+ (1,-40) [-40|80] "Unit_DegreCelsi"  BCM1
 SG_ TSG_FlHz_BFS_FnAbbruchHzKreis_A : 55|1@1+ (1,0) [0|1] ""  BCM1
 SG_ TSG_FlHz_BFS_NTC_B : 56|7@1+ (1,-40) [-40|80] "Unit_DegreCelsi"  BCM1
 SG_ TSG_FlHz_BFS_FnAbbruchHzKreis_B : 63|1@1+ (1,0) [0|1] ""  BCM1

BO_ 976 TSG_FT_01: 8 TSG_FS
 SG_ FT_Tuer_geoeffnet : 0|1@1+ (1,0) [0|1] ""  BCM1,BCM2,ELV,Gateway,IEZS,MFG,SitzMem_FS,TSG_BFS,VTS
 SG_ FT_verriegelt : 1|1@1+ (1,0) [0|1] ""  BCM2,Gateway,MFG,SitzMem_FS,TSG_BFS,VTS
 SG_ FT_gesafet : 2|1@1+ (1,0) [0|1] ""  BCM2,Gateway,MFG,TSG_BFS,VTS
 SG_ FT_Schluesselschalter_auf : 3|1@1+ (1,0) [0|1] ""  BCM2,Gateway,MFG,TSG_BFS
 SG_ FT_Schluesselschalter_zu : 4|1@1+ (1,0) [0|1] ""  BCM2,Gateway,MFG,TSG_BFS
 SG_ FT_Unlock_Taster : 5|1@1+ (1,0) [0|1] ""  BCM2,Gateway,MFG,TSG_BFS
 SG_ FT_Lock_Taster : 6|1@1+ (1,0) [0|1] ""  BCM2,Gateway,MFG,TSG_BFS
 SG_ FT_Sperrklinke : 7|1@1+ (1,0) [0|1] ""  BCM2,Gateway,MFG
 SG_ FT_TAG_betaetigt : 8|1@1+ (1,0) [0|1] ""  Gateway,MFG
 SG_ FT_TIG_betaetigt : 9|1@1+ (1,0) [0|1] ""  BCM1,BCM2,Gateway,MFG
 SG_ FT_IRUE_Taste : 10|1@1+ (1,0) [0|1] ""  BCM2,Gateway,MFG
 SG_ FT_HD_Taste : 11|1@1+ (1,0) [0|1] ""  AAG,BCM2,Gateway,HDSG,MFG
 SG_ FT_TD_Taste_Fehler : 12|1@1+ (1,0) [0|1] ""  Gateway
 SG_ FT_TD_Taste : 13|1@1+ (1,0) [0|1] ""  BCM2,Gateway,MFG
 SG_ SSR_Temp_Freigabe : 14|1@1+ (1,0) [0|1] ""  Gateway,TSG_BFS
 SG_ FT_Sp_Heizung_Anf : 15|1@1+ (100,0) [0|100] "Unit_PerCent"  Gateway
 SG_ FT_HD_Taste_2 : 16|1@1+ (1,0) [0|1] ""  Gateway,HDSG
 SG_ FT_TSG_hinten_verbaut : 18|1@1+ (1,0) [0|1] ""  Gateway,MFG
 SG_ FT_Sp_Blk_def : 19|1@1+ (1,0) [0|1] ""  BCM1,Gateway,MFG
 SG_ FT_FH_S_ManHoch : 20|1@1+ (1,0) [0|1] ""  BCM2,Gateway,MFG
 SG_ FT_FH_S_AutoHoch : 21|1@1+ (1,0) [0|1] ""  BCM2,Gateway,MFG
 SG_ FT_FH_S_ManTief : 22|1@1+ (1,0) [0|1] ""  BCM2,Gateway,MFG
 SG_ FT_FH_S_AutoTief : 23|1@1+ (1,0) [0|1] ""  BCM2,Gateway,MFG
 SG_ FT_FH_Oeffnung : 24|8@1+ (0.5,0) [0|100] "Unit_PerCent"  BCM1,BCM2,Gateway,MFG,SAD,SAD2,VSG,VTS
 SG_ FT_FH_Bew_hoch : 32|1@1+ (1,0) [0|1] ""  Gateway,MFG,TSG_BFS,VSG
 SG_ FT_FH_Bew_tief : 33|1@1+ (1,0) [0|1] ""  Gateway,MFG,TSG_BFS
 SG_ FT_FH_Fang : 34|1@1+ (1,0) [0|1] ""  Gateway,MFG
 SG_ FT_FH_Block : 35|1@1+ (1,0) [0|1] ""  Gateway,MFG
 SG_ FT_FH_Thermo : 36|1@1+ (1,0) [0|1] ""  BCM2,Gateway,MFG
 SG_ FT_UEKB_aktiviert : 37|1@1+ (1,0) [0|1] ""  BCM2,Gateway,MFG
 SG_ ASW_HMI_defekt : 38|1@1+ (1,0) [0|1] ""  Gateway
 SG_ FT_FH_normiert : 39|1@1+ (1,0) [0|1] ""  BCM2,Gateway,MFG,VSG,VTS
 SG_ FT_Schliesstaster : 40|1@1+ (1,0) [0|1] ""  Gateway,MFG
 SG_ FT_Zuziehhilfe_aktiv : 41|1@1+ (1,0) [0|1] ""  Gateway,MFG
 SG_ FT_SP_ausgerastet : 42|1@1+ (1,0) [0|1] ""  Gateway,MFG,VTS
 SG_ FT_SP_lr_aktiv : 43|1@1+ (1,0) [0|1] ""  Gateway,MFG
 SG_ FT_SP_ht_aktiv : 44|1@1+ (1,0) [0|1] ""  Gateway,MFG
 SG_ ASW_wakeup : 45|1@1+ (1,0) [0|1] ""  AAG,Gateway
 SG_ FT_Oben_Block_erw : 46|1@1+ (1,0) [0|1] ""  Gateway,MFG,TSG_BFS
 SG_ FT_Unten_Block_erw : 47|1@1+ (1,0) [0|1] ""  Gateway,MFG,TSG_BFS
 SG_ FT_Kisi_li_aktiv : 48|1@1+ (1,0) [0|1] ""  BCM1,BCM2,Gateway,MFG,SAD,SAD2,SitzMem_HBFS,SitzMem_HFS,TSG_BFS
 SG_ FT_Kisi_re_aktiv : 49|1@1+ (1,0) [0|1] ""  BCM1,BCM2,Gateway,MFG,SAD,SAD2,SitzMem_HBFS,SitzMem_HFS,TSG_BFS
 SG_ FT_Kisi_Taster_li : 50|1@1+ (1,0) [0|1] ""  Gateway,MFG,TSG_BFS
 SG_ FT_Kisi_Taster_re : 51|1@1+ (1,0) [0|1] ""  Gateway,MFG,TSG_BFS
 SG_ FT_BFS_Fond_Freigabe : 52|1@1+ (1,0) [0|1] ""  Gateway,MFG,SitzMem_BFS,SitzMem_FS,TSG_BFS
 SG_ FT_Kisi_Fehler : 53|1@1+ (1,0) [0|1] ""  Gateway,MFG
 SG_ FT_Daemmglas : 54|1@1+ (1,0) [0|1] ""  Gateway,MFG
 SG_ FT_SP_Heizung_Status : 55|1@1+ (1,0) [0|1] ""  BCM1,Gateway,MFG,TSG_BFS
 SG_ ASW_Warnung_aktiv_FS : 56|1@1+ (1,0) [0|1] ""  BCM1,Gateway
 SG_ FT_FH_Pos_oben : 57|1@1+ (1,0) [0|1] ""  Gateway,MFG,VSG
 SG_ FT_Tuerschloss_defekt : 58|1@1+ (1,0) [0|1] ""  BCM2,Gateway
 SG_ FT_SWA_Taster : 59|1@1+ (1,0) [0|1] ""  AAG,Gateway
 SG_ SWA_HMI_Diagnose : 60|2@1+ (1,0) [0|3] ""  Gateway

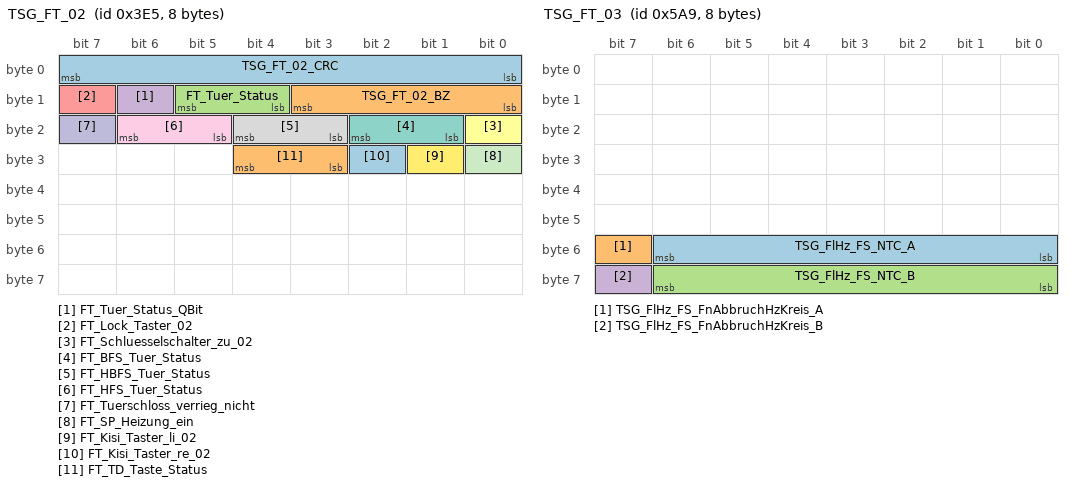
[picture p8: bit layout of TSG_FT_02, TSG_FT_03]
BO_ 997 TSG_FT_02: 8 TSG_FS
 SG_ TSG_FT_02_CRC : 0|8@1+ (1,0) [0|255] ""  BCM2,Gateway
 SG_ TSG_FT_02_BZ : 8|4@1+ (1,0) [0|15] ""  BCM2,Gateway
 SG_ FT_Tuer_Status : 12|2@1+ (1,0) [0|3] ""  BCM2,Gateway
 SG_ FT_Tuer_Status_QBit : 14|1@1+ (1,0) [0|1] ""  BCM2,Gateway
 SG_ FT_Lock_Taster_02 : 15|1@1+ (1,0) [0|1] ""  BCM2,Gateway
 SG_ FT_Schluesselschalter_zu_02 : 16|1@1+ (1,0) [0|1] ""  BCM2,Gateway
 SG_ FT_BFS_Tuer_Status : 17|2@1+ (1,0) [0|3] ""  Gateway
 SG_ FT_HBFS_Tuer_Status : 19|2@1+ (1,0) [0|3] ""  Gateway
 SG_ FT_HFS_Tuer_Status : 21|2@1+ (1,0) [0|3] ""  Gateway
 SG_ FT_Tuerschloss_verrieg_nicht : 23|1@1+ (1,0) [0|1] ""  Gateway
 SG_ FT_SP_Heizung_ein : 24|1@1+ (1,0) [0|1] ""  Gateway,TSG_BFS
 SG_ FT_Kisi_Taster_li_02 : 25|1@1+ (1,0) [0|1] ""  Gateway,MFG,TSG_BFS
 SG_ FT_Kisi_Taster_re_02 : 26|1@1+ (1,0) [0|1] ""  Gateway,MFG,TSG_BFS
 SG_ FT_TD_Taste_Status : 27|2@1+ (1,0) [0|3] ""  Gateway

BO_ 1449 TSG_FT_03: 8 TSG_FS
 SG_ TSG_FlHz_FS_NTC_A : 48|7@1+ (1,-40) [-40|80] "Unit_DegreCelsi"  BCM1
 SG_ TSG_FlHz_FS_FnAbbruchHzKreis_A : 55|1@1+ (1,0) [0|1] ""  BCM1
 SG_ TSG_FlHz_FS_NTC_B : 56|7@1+ (1,-40) [-40|80] "Unit_DegreCelsi"  BCM1
 SG_ TSG_FlHz_FS_FnAbbruchHzKreis_B : 63|1@1+ (1,0) [0|1] ""  BCM1

CM_ SG_ 1616 RA_Radio_on "1 = user perceived On";
CM_ SG_ 1616 RA_PowerAmpOn "1 = Request for Amplifier; 0 = Amplifier mute/off";
CM_ SG_ 1616 RA_Radio_mute "1=Radio is muted for telephone";
CM_ SG_ 1616 RA_VNC_OFF "VNC = Vehicle Noice Cancellation;
1 = VNC OFF; 0 = VNC ON
requests the Amp to switch VNC off";
CM_ SG_ 1616 RA_Radio_Surround "1 = Surround ON; 0 = Surround OFF
requests the Amp to switch Surroundmode";
CM_ SG_ 1616 RA_Radio_Error_Flag "1 = mindestens ein Kundendienstfehlerspeicher Eintrag vorhanden";
CM_ SG_ 1616 RA_Frequency "Übermittlung der gehörten Audiofrequenz (AM)
wird mit RA_Frequency_unit multipliziert.
Auf dem Bus werden nur eingerastete Frequenzen übertragen. Bei aktivem Tuning (RA_AM_Tuning = 1) wird 0 übertragen.";
CM_ SG_ 1616 RA_Frequency_unit "Faktor für RA_Frequency
bei AM: Faktor 0 = 1kHz
sonst   Faktor 1 = 100kHz

";
CM_ SG_ 1616 RA_AM_Tuning "Das Signal kennzeichnet einen aktiven AM Suchlauf. Während des Suchlaufes wird die Frequenz = 0 übertragen.
0 = frequency locked => Störquelle vermeidet die aktuelle Frequenz
1 = AM tuning in progress => Störquelle abschalten";
CM_ SG_ 695 RCTA_01_CRC "Für MLB:
'Berechnung siehe Lastenheft 'Kommunikationsabsicherung für FlexRay und CAN''

Ab MQB und MLBevo:
'Berechnung siehe Lastenheft 'End-to-End Kommunikationsabsicherung''

Endwerte siehe Begleitdokument 'S-PDU Kennungsfolgen'";
CM_ SG_ 695 RCTA_01_BZ "4bit-Botschaftszaehler, wird in jeder Sendebotschaft inkrementiert";
CM_ SG_ 695 RCTA_Info_rechts "Das alte RCTA_Info wird aufgeteilt in RCTA_Info_links und RCTA_Info_rechts. Damit sollen Richtungsblinken oder ähnliches aufgrund der RCTA-Funtkion möglich gemacht werden.

Dieser Parameter ist eine zusätzliche Information zu RCTA. Andere Systeme können";
CM_ SG_ 695 RCTA_Anforderung_HMS "Nach einer Notbremsung durch RCTA muss das Fahrzeug halten. Deshalb ist eine HMS-Anforderung mit der Notbremsung erforderlich.";
CM_ SG_ 695 RCTA_Bremsruck_Anforderung "RCTA_Bremsruck_Anforderung  ist die Anforderung an das Bremssystem einen kurzen Bremsruck auszuführen. Mit dem Signal 'RCTA_Bremsruck_Freigabe' zusammen wird der Ruck ausgeführt. Dadurch soll der Fahrer auf eine mögliche Kollision hingewiesen und zum Brem";
CM_ SG_ 695 RCTA_Bremsruck_Freigabe "RCTA_Bremsruck_Freigabe ist die eigentliche Auforderung (mit dem Signal 'RCTA_Bremsruck_Anforderung') an das Bremssystem einen kurzen Bremsruck auszuführen. Dadurch soll der Fahrer auf eine mögliche Kollision hingewiesen und zum Bremsen animiert werden.";
CM_ SG_ 695 RCTA_Info_links "Das alte RCTA_Info wird aufgeteilt in RCTA_Info_links und RCTA_Info_rechts. Damit sollen Richtungsblinken oder ähnliches aufgrund der RCTA-Funtkion möglich gemacht werden.

Dieser Parameter ist eine zusätzliche Information zu RCTA. Andere Systeme können";
CM_ SG_ 695 RCTA_Status "RCTA_Status ist die Rückmeldung, ob das System überhaupt aktiv ist. Mögliche Zustände sind: Das System ist aus; Das System ist nur passiv (läuft, ist aber ohne Funktionalität); Das System ist aktiv; Das System ist fehlerhaft";
CM_ SG_ 695 RCTA_Warnton "Ansteuerung APS Tongeber für  Warnton von RCTA. (Dauerton)";
CM_ SG_ 695 RCTA_Notbremsung_Freigabe "RCTA_Notbremsung_Freigabe ist die eigentliche Auforderung (mit dem Signal 'Notbremsung_Anforderung_Wert') an das Bremssystem eine Notfallbremsung einzuleiten. Dadurch sollen größere Schäden am Fahrzeug vermieden werden.";
CM_ SG_ 695 RCTA_Notbremsung_Anforderung "RCTA_Notbremsung_Anforderung  ist die Anforderung der Funktion RCTA an das Bremssystem. Mit dem Signal 'Notbremsung_Freigabe' zusammen wird die Bremsung eingeleitet. Dadurch sollen größere Schäden am Fahrzeug verhindert werden.";
CM_ BO_ 1529 "MQB";
CM_ SG_ 1529 RDK_FMVSS138_Lampe "Ansteuerung der RDK-Lampe im Kombi bei Druckwarnung";
CM_ SG_ 1529 RDK_FMVSS138_MIL "Ansteuerung der RDK-Lampe im Kombi bei Systemstörung.
RDK-Lampe muss für 65 Sekunden blinken und anschliessend dauerhaft leuchten bis RDK dieses Bit wieder auf '0' setzt (Wiedergutprüfung).
Hinweis:  Im AU48x blinken für 60 Sekunden";
CM_ SG_ 1529 RDK_Kalibrierung "Art der Vorgabe der Solldrücke
0x0 Vorgabe der Solldrücke erfolgt durch eine Reifenauswahl in der Headunit
0x1 Vorgabe der Solldrücke erfolgt durch Betätigung des SET-Tasters des Kombiinstruments";
CM_ SG_ 1529 RDK_Warnungen_02 "Ausgabe von Texten/Akustik im Kombiinstrument";
CM_ SG_ 1529 RDK_W_1_Reifen_HL "Harte Warnung fuer Reifen hinten links";
CM_ SG_ 1529 RDK_W_1_Reifen_HR "Harte Warnung fuer Reifen hinten rechts";
CM_ SG_ 1529 RDK_W_1_Reifen_VL "Harte Warnung fuer Reifen vorne links";
CM_ SG_ 1529 RDK_W_1_Reifen_VR "Harte Warnung fuer Reifen vorne rechts
";
CM_ SG_ 1529 RDK_W_2_Reifen_HL "Weiche Warnung fuer Reifen hinten links";
CM_ SG_ 1529 RDK_W_2_Reifen_HR "Weiche Warnung fuer Reifen hinten rechts";
CM_ SG_ 1529 RDK_W_2_Reifen_VL "Weiche Warnung fuer Reifen vorne links";
CM_ SG_ 1529 RDK_W_2_Reifen_VR "Weiche Warnung fuer Reifen vorne rechts";
CM_ SG_ 1711 RV_Video_on "Anzeige Kamerabild
";
CM_ SG_ 1711 RV_Dark_Screen "Verdunkelungsanforderung Kamerabild";
CM_ SG_ 1711 RV_HMI_Mode "Aktueller Wert für den HMI-Modus

";
CM_ SG_ 1711 RV_System_aktiv "Systemstatus (Initialisierungsphase)
";
CM_ SG_ 1711 RV_Settings_enabled "Menü 'Einstellungen'
";
CM_ SG_ 1711 RV_Menu_Item "Ausgewähltes Menü-Item
";
CM_ SG_ 1711 SV_Video_on "Aufschaltaufforderung SideView";
CM_ SG_ 1711 RV_Helligkeit "Istwert fuer Helligkeit (in Prozent)";
CM_ SG_ 1711 RV_Kontrast "Istwert fuer Kontrast (in Prozent)";
CM_ SG_ 1711 RV_Farbe "Istwert fuer Farbe (in Prozent)";
CM_ SG_ 1525 RW_Gesamt_Reichweite_Max_Anzeige "Angabe der Maximalen Anzeige der gesamten Reichweite.
Ergänzt das Signal RW_Gesamt_Reichweite_Anzeige";
CM_ SG_ 1525 RW_RWDS_Lastprofil "Lastprofil zur Bestimmung der notwendigen Nachladeenergie (Reichweitendurchschnittstrom)";
CM_ SG_ 1525 RW_Gesamt_Reichweite "Reichweite für primär und sekundär Reichweite (eventuell Gewichtet)";
CM_ SG_ 1525 RW_Prim_Reichweitenverbrauch "Für primäre Reichweitenberechnung zugrunde gelegter Verbrauch";
CM_ SG_ 1525 RW_Prim_Reichweitenv_Einheit "Für primäre  Reichweitenberechnung (KBI_Prim_Reichweitenverbrauch) zugrunde gelegte Einheit";
CM_ SG_ 1525 RW_Primaer_Reichweite "Reichweite der primären Antriebsart";
CM_ SG_ 1527 RW_Reservewarnung_aktiv "Ansteuerung der Reservewarnung im Kombiinstrument (Leuchte und MFA-Warnhinweis). Wird gesetzt bei Erreichen / Unterschreiten eines unteren Reichweitenschwellwerts und zurückgenommen bei Erreichen / Überschreiten eines oberen Reichweitenschwellwerts.";
CM_ SG_ 1527 RW_Reichweite_Einheit_Anzeige "Einheit für Primaer-/Sekundaer-/Gesamt- Reichweite zur Anzeige im Kombi";
CM_ SG_ 1527 RW_Gesamt_Reichweite_Anzeige "Reichweite für primär und sekundär Reichweite (eventuell Gewichtet) zur Anzeige im Kombi";
CM_ SG_ 1527 RW_Primaer_Reichweite_Anzeige "Reichweite der primären Antriebsart zur Anzeige im Kombi";
CM_ SG_ 1527 RW_Sekundaer_Reichweite_Anzeige "Reichweite der sekundaeren Antriebsart zur Anzeige im Kombi";
CM_ SG_ 1527 RW_Sekundaer_Reichweite "Reichweite der sekundaeren Antriebsart";
CM_ SG_ 1527 RW_Sek_Reichweitenv_Einheit "Für sekundäre Reichweitenberechnung (KBI_Sek_Reichweitenverbrauch) zugrunde gelegte Einheit";
CM_ SG_ 1527 RW_Sek_Reichweitenverbrauch "Für sekundäre Reichweitenberechnung zugrunde gelegter Verbrauch";
CM_ BO_ 1440 "8Byte ab MLBevo
LIN-CAN (1:1) Botschaften werden geroutet
-  wenn entsprechender Slave codiert ist
-  wenn fehlerfreie Kommunikation zum Slave besteht
-  bei fehlerhafter Kommunikation zum Slave wird die Botschaft für 4s mit den letzten gültigen Werte";
CM_ SG_ 1440 LS_defekt "Fehlererkennung Lichtsensor
";
CM_ SG_ 1440 LS_Verbau "Verbauinfo Lichtsensor
";
CM_ SG_ 1440 RS_Regenmenge "Regenmenge für intel. Heckleuchte ";
CM_ SG_ 1440 RS_Verbau "Verbauinfo Regensensor";
CM_ SG_ 1440 RS_Verglasung_schliessen "Anforderung: Verglasung schliessen
";
CM_ SG_ 1440 RS_defekt "Fehlererkennung Regensensor";
CM_ SG_ 1440 RS_Wischergeschwindigkeit "Wischergeschwindigkeit (Hübe/min)";
CM_ SG_ 1440 RLS_Vorfeldhelligkeit_Boost "erweiterte Helligkeitssensierung für HUD";
CM_ BO_ 1517 "


";
CM_ SG_ 1517 SAD2_Deckel_Lage "Lage Schiebeausstelldach";
CM_ SG_ 1517 SAD2_Deckel_normiert "Anzeige Normierung des Schiebeausstelldaches 2";
CM_ SG_ 1517 SAD2_Deckel_Thermoschutz "Anzeige aktivierter Thermoschutz des Schiebeausstelldaches 2";
CM_ SG_ 1517 SAD2_Deckel_UEKB_aktiv "Anzeige aktivierter Überschusskraftbegrenzung des Schiebeausstelldaches 2";
CM_ SG_ 1517 SAD2_Deckel_Position "Aktuelle Postion des Schiebeausstelldaches 2";
CM_ SG_ 1517 SAD2_Rollo_Lage "Lage des Rollo 2";
CM_ SG_ 1517 SAD2_Rollo_Position "Aktuelle Postion des Rollo 2";
CM_ SG_ 1517 SAD2_Rollo_normiert "Signal für die Anzeige, dass das Rollo2 korrekt normiert wurde.";
CM_ SG_ 1517 SAD2_Rollo_Thermoschutz "Anzeigen aktivierter Thermoschutz des Dachrollo 2";
CM_ SG_ 1517 SAD2_Rollo_UEKB_aktiv "Anzeigen aktivierter Überschusskraftbegrenzung des Dachrollos 2";
CM_ BO_ 1504 "MLBevo 8Byte
LIN-CAN (1:1) Botschaft wird geroutet:
- wenn entsprechender Slave codiert ist
- wenn fehlerfreie Kommunikation zum Slave besteht
- bei fehlerhafter Kommunikation zum Slave wird die Botschaft für 4s mit den letzten gültigen Werten versend";
CM_ SG_ 1504 MD1_Position "Schiebedachstellung 1 (Signal wird 1:1 vom BCM2 geroutet; ursprünglicher Sender: SAD = LIN-Slave vom BCM2)";
CM_ SG_ 1504 MD1_Lage "Lage Schiebedachstellung 1 (Signal wird 1:1 vom BCM2 geroutet; ursprünglicher Sender: SAD = LIN-Slave vom BCM2)";
CM_ SG_ 1504 MD3_Position "Schiebedachstellung 3 
(Signal wird 1:1 vom BCM2 geroutet; ursprünglicher Sender: SAD = LIN-Slave vom BCM2)
";
CM_ SG_ 1504 MD3_Lage "Lage Schiebedachstellung 3 
(Signal wird 1:1 vom BCM2 geroutet; ursprünglicher Sender: SAD = LIN-Slave vom BCM2) 
";
CM_ SG_ 1504 MRollo_Position "Schiebedachstellung Rollo
(Signal wird 1:1 vom BCM2 geroutet; ursprünglicher Sender: Rollo = LIN-Slave vom BCM2)";
CM_ SG_ 1504 MRollo_Lage "Lage Rollo
(Signal wird 1:1 vom BCM2 geroutet; ursprünglicher Sender: Rollo = LIN-Slave vom BCM2)";
CM_ SG_ 1504 SAD_normiert "Anzeige Normierung des Schiebeausstelldaches";
CM_ SG_ 1504 SAD_Thermoschutz "Anzeige aktivierter Thermoschutz des Schiebeausstelldaches";
CM_ SG_ 1504 SAD_UEKB_aktiv "Anzeige aktivierter Überschusskraftbegrenzung des Schiebeausstelldaches";
CM_ SG_ 1504 Rollo_normiert "Anzeigen Normierung des Dachrollos";
CM_ SG_ 1504 Rollo_Thermoschutz "Anzeigen aktivierter Thermoschutz des Dachrollo";
CM_ SG_ 1504 Rollo_UEKB_aktiv "Anzeigen aktivierter Überschusskraftbegrenzung des Dachrollos";
CM_ SG_ 1504 SAD_Taster_Deckel_hi "Taster für SAD Deckel hinten";
CM_ SG_ 1504 SAD_Taster_Deckel_vo "Taster für SAD Deckel vorne";
CM_ SG_ 1504 SAD_Taster_Rollo_hi "Taster für SAD Rollo hinten";
CM_ SG_ 1504 SAD_Taster_Rollo_vo "Taster für SAD Rollo vorne";
CM_ BO_ 424 "CAN-Botschaft";
CM_ SG_ 424 SARA_11_CRC "Für MLB:
'Berechnung siehe Lastenheft 'Kommunikationsabsicherung für Flexray und CAN''

Ab MQB und MLBevo:
'Berechnung siehe Lastenheft 'End-to-End Kommunikationsabsicherung'

Endwerte siehe Begleitdokument 'S-PDU Kennungsfolge'";
CM_ SG_ 424 SARA_Accel_X_r "Beschleunigung Acceleration-X routable:
- 0x0000= Sensor nicht verbaut, Signal wird nicht berechnet
- genutzter Wertebereich ± 640 m/s²

Filterung: 60 Hz Sensorfilter + 15 Hz uC-Filter (Cheby-II 3.Ordnung)";
CM_ SG_ 424 SARA_Accel_Y_r "Beschleunigung Acceleration-Y routable:
- 0x0000= Sensor nicht verbaut, Signal wird nicht berechnet
- genutzter Wertebereich ± 640 m/s²

Filterung: 60 Hz Sensorfilter + 15 Hz uC-Filter (Cheby-II 3.Ordnung)";
CM_ SG_ 424 SARA_Omega_Z_r "Winkelgeschwindigkeit Omega-Z routable:
- 0x0000 = Sensor nicht verbaut, Signal wird nicht berechnet
- genutzter Wertebereich ± 320 Deg/s

Filterung: 60 Hz Sensorfilter + 15 Hz uC-Filter (Cheby-II 3.Ordnung)";
CM_ SG_ 424 SARA_CF_Accel_X_r "Confidence Faktor Beschleunigung Acceleration-X routable:

0=gültiger Wert
1=nicht belegt
2=nicht belegt
3=Temporärer Fehler {solange möglich werden aktuelle Sensorwerte gesendet, ansonsten 0xFFFF}
4=Init {0x8000 wird gesendet}
5=Sensor nicht verba";
CM_ SG_ 424 SARA_CF_Accel_Y_r "Confidence Faktor Beschleunigung Acceleration-Y routable:

0=gültiger Wert
1=nicht belegt
2=nicht belegt
3=Temporärer Fehler {solange möglich werden aktuelle Sensorwerte gesendet, ansonsten 0xFFFF}
4=Init {0x8000 wird gesendet}
5=Sensor nicht verba";
CM_ SG_ 424 SARA_CF_Omega_Z_r "Confidence Faktor Winkelgeschwindigkeit Omega-Z routable:

0=gültiger Wert
1=nicht belegt
2=nicht belegt
3=Temporärer Fehler {solange möglich werden aktuelle Sensorwerte gesendet, ansonsten 0xFFFF}
4=Init {0x8000 wird gesendet}
5=Sensor nicht verba";
CM_ BO_ 1522 "MQB";
CM_ SG_ 1522 KBI_Phototransistor "Signal wird benötigt für die Dimmung von Such- Funktions- und Displaybeleuchtungen. Der Signalfluss erfolgt vom Steuergerät mit Fotosensor an die jeweiligen Dimmmaster-Steuergeräte.

Für Audi B8/Q5 und D4/C7/VW526 vor PA: 
0xFE Phototransistor nicht ve";
CM_ SG_ 1522 KBI_Dimmpoti "Signal wird benötigt für Dimmung im Audi B8. Der Signalfluss erfolgt vom Kombi an das BCM1.";
CM_ BO_ 1363 "Botschaft vom Steuergerät der dritten Sitzreihe";
CM_ SG_ 1363 SR3_Status_Lehne_Links "Status der Lehnenverriegelung  Links von der 3ten Sitzreihe ";
CM_ SG_ 1363 SR3_Status_Lehne_Rechts "Status der Lehnenverriegelung  Rechts von der 3ten Sitzreihe ";
CM_ BO_ 980 "Ab MQB 7.2";
CM_ SG_ 980 SMLS_01_CRC "Für MLB:
'Berechnung siehe Lastenheft 'Kommunikationsabsicherung für FlexRay und CAN''

Ab MQB und MLBevo:
'Berechnung siehe Lastenheft 'End-to-End Kommunikationsabsicherung''

Endwerte siehe Begleitdokument 'S-PDU Kennungsfolgen'";
CM_ SG_ 980 SMLS_01_BZ "4bit Botschaftszaehler, wird mit jeder Sendebotschaft inkrementiert";
CM_ SG_ 980 BH_Blinker_li "Blinkerhebel Richtung links
";
CM_ SG_ 980 BH_Blinker_re "Blinkerhebel Richtung rechts
";
CM_ SG_ 980 BH_Lichthupe "Betaetigung Lichthupe
";
CM_ SG_ 980 BH_Fernlicht "Betaetigung Fernlicht
";
CM_ SG_ 980 WH_Tipwischen "Wischerhebel: Tippwischen
";
CM_ SG_ 980 WH_Intervall "Wischerhebel: Stellung Intervall
";
CM_ SG_ 980 WH_WischerStufe1 "Wischerhebel: Stufe Wischen 1
";
CM_ SG_ 980 WH_WischerStufe2 "Wischerhebel: Stufe Wischen 2
";
CM_ SG_ 980 WH_Frontwaschen "Wischerhebel: Stellung Wisch Wasch vorne
";
CM_ SG_ 980 WH_Heckintervall "Wischerhebel: Stellung Heckintervall
";
CM_ SG_ 980 WH_Heckwaschen "Wischerhebel: Stellung Wisch Wasch hinten
";
CM_ SG_ 980 WH_Intervallstufen "Wischerhebel: Stellung Intervallstufen";
CM_ SG_ 980 FAS_Taster "Betaetigung FAS Taster
";
CM_ SG_ 980 FAS_Taster_Fehler "Fehlerstatus FAS Taster
";
CM_ SG_ 980 SMLS_Hupe "Betaetigung Hupe
";
CM_ SG_ 980 LRH_on_off "Status Lenkradheizung";
CM_ SG_ 980 LRH_aktiv "Signal gibt an, ob ein Heizstrom durch die Lenkradheizung fließt. Es dient der Auswertung durch das Energiemanagement.";
CM_ SG_ 980 SMLS_P_verriegelt_plausibel "Signal stellt den Plausibilisierungstatus des Signals p_verriegelt auf den Fahrzeugbus zur Verfügung. Eine Plausibilität muss explizit erkannt werden. Initial wird 'unplausibel' gesendet. Ein plausibles Signal wird erkannt, wenn p_verriegelt plausibel geg";
CM_ SG_ 980 WH_SRA "Scheinwerferreinigungsanlage

derzeit nur bei PAG umgesetzt";
CM_ SG_ 980 WH_Wischer_Fehler "Anzeige, ob am Lenkstockschalter ein Fehler anliegt.
Notwendig aufgrund ASIL-Einstufung";
CM_ SG_ 980 BH_Blinker_Fehler "Anzeige, ob am Lenkstockschalter ein Fehler anliegt.
Notwendig aufgrund ASIL-Einstufung";
CM_ SG_ 1467 SoSe_SunInt_2D_Li "Sonnenintensität links (2D Sensor)";
CM_ SG_ 1467 SoSe_SunInt_2D_Re "Sonnenintensität rechts (2D Sensor)";
CM_ BO_ 1710 "MLBevo 8Byte";
CM_ SG_ 1710 SP_FT_oben "Spiegel Fahrertür nach oben";
CM_ SG_ 1710 SP_FT_unten "Spiegel Fahrertür nach unten";
CM_ SG_ 1710 SP_FT_links "Spiegel Fahrertür nach links";
CM_ SG_ 1710 SP_FT_rechts "Spiegel Fahrertür nach rechts";
CM_ SG_ 1710 SP_BT_oben "Spiegel Beifahrertür nach oben";
CM_ SG_ 1710 SP_BT_unten "Spiegel Beifahrertür nach unten";
CM_ SG_ 1710 SP_BT_links "Spiegel Beifahrertür nach links";
CM_ SG_ 1710 SP_BT_rechts "Spiegel Beifahrertür nach rechts";
CM_ SG_ 1710 SP_abklappen "Spiegel abklappen";
CM_ SG_ 1710 SP_anklappen "Spiegel anklappen";
CM_ SG_ 1710 SP_normieren "Spiegel normieren";
CM_ SG_ 1710 SP_Hzg_Taster "Heizungstaster/schalter aktiv";
CM_ SG_ 1710 SP_S_oben "Spiegelschalter in Stellung oben";
CM_ SG_ 1710 SP_S_unten "Spiegelschalter in Stellung unten";
CM_ SG_ 1710 SP_S_links "Spiegelschalter in Stellung links";
CM_ SG_ 1710 SP_S_rechts "Spiegelschalter in Stellung rechts";
CM_ SG_ 1710 SP_Auswahl_li "Spiegelschalter in Stellung Auswahl links";
CM_ SG_ 1710 SP_Auswahl_re "Spiegelschalter in Stellung Auswahl rechts";
CM_ SG_ 1710 SP_ARA_Status "Rückkanal TSG im ARA-Modus";
CM_ SG_ 1710 SP_S_Klappen "Spiegelschalter in Stellung Klappen";
CM_ SG_ 1710 SP_Verstellschalter_Fehler "Erkennung eines hängenden Spiegelverstellschalters";
CM_ SG_ 904 SpoilerSG_01_CRC "Checksumme
End-to-End Kommunikationsabsicherung aufgrund FuSi-relevanter Signale";
CM_ SG_ 904 SpoilerSG_01_BZ "Botschaftszähler";
CM_ SG_ 904 SpoilerSG_HSpoiler_IstPos "Aktuelle Istposition des Heckspoilers.";
CM_ SG_ 904 SpoilerSG_Fehler "Anzeige einer Warnung oder Fehlers.";
CM_ SG_ 1313 STH_LED "Funktionslampe";
CM_ SG_ 1313 STH_EKP_Anst "STH sendet die Anforderung zur Ansteuerung der EKP an den Motor, um Kraftstoffbehälter der STH zu befüllen.";
CM_ SG_ 1313 STH_Start_folgt "Thema Start/Stop: Im Stop-Modus muß das KBT einen Wiederstart anfordern, da ein STH-Start notwendig ist.";
CM_ SG_ 1313 STH_Ventiloeffnungszeit "Die Standheizung sendet an den Motor die Information darüber wie lange das Magnetventil die Wasserkreisläufe von 'klein' aus 'gross' geschaltet hat. ";
CM_ SG_ 1313 STH_Ventil_Status "Statusrückmeldung Ansteuerung 3/2 Wege-Ventil";
CM_ SG_ 1313 STH_Fehler_ElWaPu "Fehler der el. Zusatzwasserpumpe der zur Deaktivierung der Wasserpumpe führt ";
CM_ SG_ 1313 STH_Waermeeintrag "Signal enthält die Brenndauer in 1min-Schritten, über welche die Standheizung gelaufen ist";
CM_ SG_ 1313 STH_Pumpen_Anf_extern "Anforderung der motorseitigen elektr. (externen) Wasserpumpe zur Kreislaufunterstützung im Standheizbetrieb";
CM_ SG_ 1313 STH_KVS "Kraftstoffverbrauch";
CM_ SG_ 1313 STH_Fehlerstatus "Übermittlung der unterschiedlichen Fehlerzustände der Standheizung";
CM_ SG_ 1313 STH_Heizleistung "Heizleistung in %";
CM_ SG_ 1313 STH_Texte "Anforderung der untersch. Anzeigetexte im Mitteldisplay d. Kombi.

0: Keine Anzeige
1: Kein Standheizungs/-llüftungsbetrieb wegen Batteriemanagementeinschränkung
2: Kein Standheizungs-/lüftungsbetrieb wegen Kraftstoffmangels
3: Kein Standheizungs-/lü";
CM_ SG_ 1313 STH_Motorvorwaermung "Info an der Motor, dass der Aufheizvorgang mit Motorvorwärmung erfolgt ist";
CM_ SG_ 1313 STH_war_aktiv "Bit beeinhaltet die Info, dass die Standheizung während der letzten halbe Stunde aktiv war.";
CM_ BO_ 1650 "Zielzeittimeranzeige im Display des MMI";
CM_ SG_ 1650 STH_ZZ_Monat "Zielzeittimeranzeige im Display des MMI (Datum, Monat); Initwert ist der zuletzt gültige Wert";
CM_ SG_ 1650 STH_ZZ_Tag "Zielzeittimeranzeige im Display des MMI (Datum, Tag); Initwert ist der zuletzt gültige Wert";
CM_ SG_ 1650 STH_ZZ_Betriebsmodus "Betriebsdauerberechnung anhand Aussentemperaturauswertung mit Faktor 'ZZ_Betriebsmodus'";
CM_ SG_ 1650 STH_ZZ_Minute "Zielzeittimeranzeige im Display des MMI (Minute); Initwert ist der zuletzt gültige Wert";
CM_ SG_ 1650 STH_ZZ_Status_Timer "Zielzeittimeranzeige im Display des MMI (Timer aktiv/n.aktiv)";
CM_ SG_ 1650 STH_ZZ_Stunde "Zielzeittimeranzeige im Display des MMI (Stunde); Initwert ist der zuletzt gültige Wert";
CM_ SG_ 1650 STH_ZZ_Betriebsdauer "Betriebsdauer der Standheizung, die über die Funkfernbedienung verändert wurde";
CM_ SG_ 1172 STS_01_CRC "Für MLB:
'Berechnung siehe Lastenheft 'Kommunikationsabsicherung für FlexRay und CAN''

Ab MQB und MLBevo:
'Berechnung siehe Lastenheft 'End-to-End Kommunikationsabsicherung''

Endwerte siehe Begleitdokument 'S-PDU Kennungsfolgen'";
CM_ SG_ 1172 STS_01_BZ "4bit Botschaftszähler, wird in jeder Sendebotschaft inkrementiert
";
CM_ SG_ 1172 STS_Anlassersperre "Wiederstartverhinderung (Anlassersperre)";
CM_ SG_ 1172 STS_Typencodierung "Typcodierung Schnittstelle für Tracking Systeme
";
CM_ SG_ 1172 STS_LIN_aktiv "Tracking System über LIN";
CM_ SG_ 1172 STS_Standlicht "statisch oder auch mit Blink_modi für Taxialarm";
CM_ SG_ 1172 STS_Fahrlicht "statisch oder auch mit Blink_modi für interm. Fahrlicht";
CM_ SG_ 1172 STS_Alarm_still "VTS hat einen Alarm erkannt. Alarm ist aber noch nicht bestätigt.";
CM_ SG_ 1172 STS_Texte "Nummer des Textes die im Kombi angezeigt werden soll.

Signalwert ---- Meldungstext Audi ---- Meldungstext PAG:
0x0, kein_Text ---- kein Text ---- kein Text
0x1, Text_01 ---- kein Text ---- Driver Card nicht erkannt
0x2, Text_02 ---- Ortungsassistent";
CM_ SG_ 1172 STS_Laderelais "Signal für die Auswertung zur Anzeige der Batterie-Schwach-Anzeige im Kombi ";
CM_ SG_ 1172 STS_Summer "Warnsummer für Funkhauptschalter und Fahrschulpedal";
CM_ SG_ 1172 STS_Alarm_Blinker "Taxialarmblinken, wie DWA ohne Fanfare";
CM_ SG_ 1172 STS_Notstart "Signal zeigt an, dass ein Notstart erfolgte.";
CM_ SG_ 1172 STS_Signalhorn "Versehrte, Fahrschule oder Taxi (bei Alarm)";
CM_ SG_ 1172 STS_Leerlaufschaltung "Versetzt das Fahrzeug in einen Zustand in dem es nicht mehr auf EGas-Anforderungen reagiert";
CM_ BO_ 783 "ab MQB mit CRC-8";
CM_ SG_ 783 SWA_01_CRC "Für MLB:
'Berechnung siehe Lastenheft 'Kommunikationsabsicherung für FlexRay und CAN''

Ab MQB und MLBevo:
'Berechnung siehe Lastenheft 'End-to-End Kommunikationsabsicherung''

Endwerte siehe Begleitdokument 'S-PDU Kennungsfolgen'";
CM_ SG_ 783 SWA_01_BZ "Fehlende Beschreibung (Import)";
CM_ SG_ 783 SWA_Anzeigen "SWA- Texte und -Akustik zur Anzeige im Kombiinstrument
0x5-0xF = reserviert
";
CM_ SG_ 783 SWA_Blindheit_erkannt "SWA erkennt selbständig eigene Blindheit durch äußere Einflüsse.";
CM_ SG_ 783 SWA_rel_Nichtverf "SWA erkennt eine Nichtverfuegbarkeit, die Objektdetektion betreffend, ohne FSP-Eintrag";
CM_ SG_ 783 SWA_rel_Fehler "SWA erkennt einen Fehler, die Objektdetektion betreffend, mit FSP-Eintrag.";
CM_ SG_ 783 SWA_Sta_aktiv "SWA Status aktiv; Lampenansteuerung im Kombi";
CM_ SG_ 783 SWA_Sta_passiv "SWA Status passiv; Lampenansteuerung im Kombi";
CM_ SG_ 783 SWA_FT_RueckLED "SWA/ASW Rückmelde-LED. Zeigt den Aktivierungszustand der Funktionen SWA/ASW";
CM_ SG_ 783 ASW_Status "Funktionsstatus Ausstiegswarnung (ASW)";
CM_ SG_ 783 SWA_Standziele_li "Abstand zwischen Fahrzeug und Standziele links geringer als ein applizierbarer Wert.";
CM_ SG_ 783 SWA_Kolonne_li "Info, dass auf der entspr. Spur mehr als zwei Fahrzeuge zu finden sind. ";
CM_ SG_ 783 SWA_Infostufe_SWA_li "Aktion der SWA-Funktion auf der entsprechenden Fahrzeugseite";
CM_ SG_ 783 SWA_Warnung_SWA_li "Aktion der SWA-Funktion auf der entsprechenden Fahrzeugseite";
CM_ SG_ 783 ASW_Warnung_FS "Modus Beifahrerseite der Funktion Ausstiegswarnung (ASW)";
CM_ SG_ 783 ASW_Warnung_BFS "Modus Beifahrerseite der Funktion Ausstiegswarnung (ASW)";
CM_ SG_ 783 ASW_Kombitexte "ASW_Kombitexte bestimmt welcher Text im Kombi angezeigt wird. Darüber hinaus werden auch Kombi-Akkustik durch dieses Signal ausgelöst.

Dieses Signal ersetzt SWA_Anzeigen für den ASW-Anteil. Der SWA-Anteil des alten Signals findet sich in SWA-Kombitexte";
CM_ SG_ 783 SWA_Kolonne_mi "Info, dass auf der entspr. Spur mehr als zwei Fahrzeuge zu finden sind. ";
CM_ SG_ 783 SWA_Standziele_re "Abstand zwischen Fahrzeug und Standziele links geringer als ein applizierbarer Wert.";
CM_ SG_ 783 SWA_Kolonne_re "Info, dass auf der entspr. Spur mehr als zwei Fahrzeuge zu finden sind. ";
CM_ SG_ 783 SWA_Infostufe_SWA_re "Aktion der SWA-Funktion auf der entsprechenden Fahrzeugseite";
CM_ SG_ 783 SWA_Warnung_SWA_re "Aktion der SWA-Funktion auf der entsprechenden Fahrzeugseite";
CM_ SG_ 783 HRE_Anzeigetexte "HRE-Texte und -Akustik zur Anzeige im Kombiinstrument

0x9  - 0xF = reserviert";
CM_ SG_ 783 SWA_Gischtzaehler "Zähler, der die eigene Gischt bei nasser Fahrbahn misst (Kennwert)";
CM_ SG_ 783 Heckradar_Kombitexte "Heckradar_Kombitexte bestimmt welcher Text im Kombi angezeigt wird. Darüber hinaus werden auch Kombi-Akkustik durch dieses Signal ausgelöst.

Dieses Signal ersetzt SWA_Anzeigen und deckt alle Kombinationsmöglichkeiten der Heckradarfunktionen ab. Die Fun";
CM_ SG_ 783 RCTA_Kombitexte "RCTA_Kombitexte bestimmt welcher Text im Kombi angezeigt wird. Darüber hinaus werden auch Kombi-Akkustik durch dieses Signal ausgelöst.

0x7 =  reserviert";
CM_ SG_ 673 SWA_LED_Hell_BFS "Helligkeitswert SWA LED Beifahrerseite";
CM_ SG_ 673 SWA_LED_Hell_FS "Helligkeitswert SWA LED Fahrerseite";
CM_ SG_ 673 SWA_LED_Modus_BFS "Ansteuerung SWA LED Beifahrerseite";
CM_ SG_ 673 SWA_LED_Modus_FS "Ansteuerung SWA LED Fahrerseite";
CM_ SG_ 788 SWA_Obj_03_GeschwRelX "Relative Geschwindigkeit in x (m/s)
Geschwindigkeiten beziehen sich immer auf den Objektmittelpunkt
Messung in Radialrichtung";
CM_ SG_ 788 SWA_Obj_03_Gemessen "Status Objekt gemessen/getrackt";
CM_ SG_ 788 SWA_Obj_03_ID "ID des Objektes";
CM_ SG_ 788 SWA_Obj_03_PositionX "Position des Objektes in x-Richtung (Referenzpunkt der 3D-Objektbox)";
CM_ SG_ 788 SWA_Obj_03_PositionY "Position des Objektes in y-Richtung (Referenzpunkt der 3D-Objektbox)";
CM_ SG_ 788 SWA_Obj_04_GeschwRelX "Relative Geschwindigkeit in x (m/s)
Geschwindigkeiten beziehen sich immer auf den Objektmittelpunkt
Messung in Radialrichtung";
CM_ SG_ 788 SWA_Obj_04_Gemessen "Status Objekt gemessen/getrackt";
CM_ SG_ 788 SWA_Obj_04_ID "ID des Objektes";
CM_ SG_ 788 SWA_Obj_04_PositionX "Position des Objektes in x-Richtung (Referenzpunkt der 3D-Objektbox)";
CM_ SG_ 788 SWA_Obj_04_PositionY "Position des Objektes in y-Richtung (Referenzpunkt der 3D-Objektbox)";
CM_ BO_ 1413 "MQB, MLBevo";
CM_ SG_ 1413 SI_Sammel_SG_Fehler "Anzahl der gesetzten KD-Fehler direkt angeschlossener Steuergeräte der DK3 und DK4 gemäß 80127.
Hinweis: Ein Subbusmaster stellt nur die gesammelte Information der an ihn angeschlossenen Steuergeräte der DK3 und DK4 zur Verfügung.

Für ServiceKey Auswe";
CM_ SG_ 1413 SI_Diagnose_Aktiv "Gibt an ob Diagnose-Botschaften empfangen werden und somit eine Diagnose aktiv ist";
CM_ SG_ 1413 SI_T_Mode "0x0: Transportmodus nicht aktiv
0x1: Transportmodus aktiv";
CM_ SG_ 1413 SI_NWDF "Netzwerk-Diagnose Freigebe zur zentralen Aktivierung der Netzwerkdiagnose";
CM_ SG_ 1413 SI_NWDF_gueltig "Gültigkeitsbit zu SI_NWDF gemäß Lastenheft: Zentrale Aktivierung Netzwerkdiagnose";
CM_ SG_ 1413 SI_Sammelfehler "Sammelfehlermeldung zur Anzeige im Kombi - siehe Spez. Sammelfehlermeldung
Hinweis: Einzelne Steuergeräte können zur Anpassung an den Produktionsprozess im Gateway auskodiert werden!";
CM_ SG_ 1413 GW_KD_Fehler "Kundendienstfehlerbit Gateway zur Anzeige eines im Gateway abgelegten Fehlerspeichereintrages.";
CM_ SG_ 1413 SI_T_Schutz "Transportschutz-Signal, das bei Transportmodus und Motorlauf aktiv bleibt
0x0: Transportschutz nicht aktiv
0x1: Transportschutz aktiv";
CM_ SG_ 1413 SI_BUS_01 "MQB/PQ26: ACAN
MLBevo: HCAN";
CM_ SG_ 1413 SI_BUS_02 "MQB: FCAN
MLBevo: Frei";
CM_ SG_ 1413 SI_BUS_03 "MQB/PQ26: KCAN
MLBevo: KCAN";
CM_ SG_ 1413 SI_BUS_04 "MQB: ICAN
MLBevo: ICAN";
CM_ SG_ 1413 SI_BUS_05 "MQB/PQ26: DiagCAN
MLBevo: DiagCAN";
CM_ SG_ 1413 SI_BUS_06 "MQB/PQ26: ECAN
MLBevo: ECAN";
CM_ SG_ 1413 SI_BUS_07 "MQB: LIN1 (Energie)
MLBevo: LIN1 (Energie)";
CM_ SG_ 1413 SI_BUS_08 "MQB: LIN2 (MFL)
MLBevo: LIN2 (MFL)";
CM_ SG_ 1413 SI_BUS_09 "MQB: LIN3 (unbelegt)
MLBevo: LIN3 (Energie2)";
CM_ SG_ 1413 SI_BUS_10 "MLBevo: Flexray";
CM_ SG_ 1413 SI_BUS_11 "MLBevo: Ethernet";
CM_ SG_ 1413 SI_Bus_Identifikation "Das Signal identifiziert den Bus eindeutig. Das Signal ist konstant auf jedem Bus.
Der Signalwert entspricht dem Wert 'Busnummer' aus der VW80127 Gateway_component_list_databus_identification (0x2A2D) 'Bus-Identifier'.";
CM_ SG_ 1413 SI_CAB "CAB = Clusteraktivbits 
(Verwendung nur für Empfänger die nicht den AutoSar-SSW Stack implementiert haben)";
CM_ BO_ 1604 "Tankgeberwerte für Algorithmus im Kombi";
CM_ SG_ 1604 TG_Geber_1 "Rohwert der Tankgeber";
CM_ SG_ 1604 TG_Geber_2 "Rohwert der Tankgeber";
CM_ SG_ 1604 TG_Geber_3 "Rohwert der Tankgeber";
CM_ SG_ 1604 TG_Geber_4 "Rohwert der Tankgeber";
CM_ SG_ 1604 TG_Guete_Geber_1 "Güte-Information der Rohwerte der Tankgeber";
CM_ SG_ 1604 TG_Guete_Geber_2 "Güte-Information der Rohwerte der Tankgeber";
CM_ SG_ 1604 TG_Guete_Geber_3 "Güte-Information der Rohwerte der Tankgeber";
CM_ SG_ 1604 TG_Guete_Geber_4 "Güte-Information der Rohwerte der Tankgeber";
CM_ BO_ 977 "ab MQB 7.05";
CM_ SG_ 977 BT_Tuer_geoeffnet "
";
CM_ SG_ 977 BT_gesafet "Im Zustand Safe wird auch das Signal BT_verriegelt = 1 gesendet";
CM_ SG_ 977 BT_Sperrklinke "Vorraste für Schloß

zwischen Vor- und Hauptraste Signal kurz auf 1, danach wieder auf 0 wenn Tür in Hauptraste (Tür ist sicher zu wenn Sperrklinke und Türkontakt auf 0 sind)";
CM_ SG_ 977 BT_TAG_betaetigt "Türaussengriff";
CM_ SG_ 977 BT_TIG_betaetigt "Türinnengriff";
CM_ SG_ 977 BT_EC_Spiegel_Helligkeit "Dimmung für den Aussenspiegel in %";
CM_ SG_ 977 BT_Sp_Heizung_Anf "Kundenanforderung der Außenspiegelheizung Beifahrertür";
CM_ SG_ 977 BT_Tuer_Status "Türstatus mit Fehler und Initwert";
CM_ SG_ 977 BT_FH_Oeffnung "Gibt den Fensteröffnungswert in % an.";
CM_ SG_ 977 BT_FH_Fang "Fangbereich ist 4mm von oberer Lippendichtung";
CM_ SG_ 977 BT_FH_Block "Fensterscheibe befindet sich im mechanischen Block (oben oder unten)";
CM_ SG_ 977 BT_FH_Thermo "gibt an ob Fensterheber im Thermoschutz ist";
CM_ SG_ 977 BT_UEKB_aktiviert "Überschutzbegrenzungskraft bei Reversieren";
CM_ SG_ 977 BT_Kisi_Fehler "Fehlerstatus Kindersicherungsfunktion";
CM_ SG_ 977 BT_SP_Heizung_Status "Status der Spiegelheizung
";
CM_ SG_ 977 ASW_Warnung_aktiv_BFS "Abschaltung der Ambientefunktion Beifahrertür bei aktiver ASW Warnung an der Fahrertür";
CM_ SG_ 977 BT_Tuerschloss_defekt "Das Beifahrertürschloss ist nicht mehr funktionsfähig.";
CM_ SG_ 977 BT_Tuerschloss_verrieg_nicht "Das Türschloss kann nicht verriegelt werden";
CM_ SG_ 977 BT_Lock_Taster_inv "Lock Taster nicht betätigt";
CM_ SG_ 977 BT_Schluesselschalter_zu_inv "Schluesselschalter zu nicht betaetigt";
CM_ SG_ 1451 TSG_FlHz_BFS_NTC_A "Flächenheizung: Temperatur und Fehlerwert des Heizaktors";
CM_ SG_ 1451 TSG_FlHz_BFS_FnAbbruchHzKreis_A "Flächenheizung: Status";
CM_ SG_ 1451 TSG_FlHz_BFS_NTC_B "Flächenheizung: Temperatur und Fehlerwert des Heizaktors";
CM_ SG_ 1451 TSG_FlHz_BFS_FnAbbruchHzKreis_B "Flächenheizung: Status";
CM_ BO_ 976 "ab MQB 7.05";
CM_ SG_ 976 FT_gesafet "Im Zustand Safe wird auch das Signal FT_verriegelt = 1 gesendet";
CM_ SG_ 976 FT_Sperrklinke "Vorraste für Schloß

zwischen Vor- und Hauptraste Signal kurz auf 1, danach wieder auf 0 wenn Tür in Hauptraste (Tür ist sicher zu wenn Sperrklinke und Türkontakt auf 0 sind)";
CM_ SG_ 976 FT_TAG_betaetigt "Türaussengriff

wird nicht im MLB-B8 verwendet";
CM_ SG_ 976 FT_TIG_betaetigt "Türinnengriff

wird nicht im MLB-B8 verwendet";
CM_ SG_ 976 FT_IRUE_Taste "Betätigung IRUE-Taster (Innenraumüberwachung)
MQB: Bei Verbau eines einzelnen Taster zur Deaktivierung von IRUE und NGS wird dieses Signal als Deaktivierungsanforderung beider DWA-Alarmquellen gesendet.";
CM_ SG_ 976 FT_TD_Taste_Fehler "Fehlerstatus des Tankdeckelentriegelungstasters. Wird bei Drucktankkonzepten vom MSG zusammen mit dem Signal FT_TD_Taste ausgewertet, um Tankbereitschaft herzustellen.
Der Fehler beschreibt einen hängenden TD_Taster. Ein Kurzschluss oder Leitungsunterbre";
CM_ SG_ 976 SSR_Temp_Freigabe "Freigabe des Seitenscheibenrollos. Bit wird  für die Deaktivierung des SSR bei Innenraumtemperaturen kleiner -10 Grad verwendet.";
CM_ SG_ 976 FT_Sp_Heizung_Anf "Kundenanforderung der Außenspiegelheizung Fahrertür";
CM_ SG_ 976 FT_HD_Taste_2 "2. HD-Taste im Bedienfeld 
Funktion: Heckdeckel schließen";
CM_ SG_ 976 FT_FH_Oeffnung "Gibt den Fensteröffnungswert in % an.";
CM_ SG_ 976 FT_FH_Fang "Fangbereich ist 4mm von oberer Lippendichtung";
CM_ SG_ 976 FT_FH_Block "Fensterscheibe befindet sich im mechanischen Block (oben oder unten)";
CM_ SG_ 976 FT_FH_Thermo "gibt an ob Fensterheber im Thermoschutz ist";
CM_ SG_ 976 FT_UEKB_aktiviert "Überschutzbegrenzungskraft bei Reversieren";
CM_ SG_ 976 ASW_HMI_defekt "HMI Status der Funktion AusstiegsWarnung (ASW). HMI wird durch das TSG angesteuert.";
CM_ SG_ 976 FT_Schliesstaster "Vorhalt";
CM_ SG_ 976 ASW_wakeup "Trigger Start Nachlaufzeit t_1 für die Funktion Ausstieswarnung (ASW)";
CM_ SG_ 976 FT_Kisi_li_aktiv "Aktivierungsstatus der Kindersicherung links";
CM_ SG_ 976 FT_Kisi_re_aktiv "Aktivierungsstatus der Kindersicherung rechts";
CM_ SG_ 976 FT_Kisi_Taster_li "Linker Kisi Taster betaetigt";
CM_ SG_ 976 FT_Kisi_Taster_re "Rechter Kisi Taster betaetigt";
CM_ SG_ 976 FT_Kisi_Fehler "Fehlerstatus Kindersicherungsfunktion";
CM_ SG_ 976 FT_SP_Heizung_Status "Status der Spiegelheizung";
CM_ SG_ 976 ASW_Warnung_aktiv_FS "Abschaltung der Ambientefunktion Fahrertür bei aktiver ASW Warnung an der Fahrertür";
CM_ SG_ 976 FT_Tuerschloss_defekt "Das Fahrertürschloss ist nicht mehr funktionsfähig.";
CM_ SG_ 976 FT_SWA_Taster "SWA/ASW Taster Fahrertür";
CM_ SG_ 976 SWA_HMI_Diagnose "SWA HMI Diagnose beim TSG";
CM_ SG_ 997 TSG_FT_02_CRC "Für MLB:
'Berechnung siehe Lastenheft 'Kommunikationsabsicherung für FlexRay und CAN''

Ab MQB und MLBevo:
'Berechnung siehe Lastenheft 'End-to-End Kommunikationsabsicherung''

Endwerte siehe Begleitdokument 'S-PDU Kennungsfolgen'";
CM_ SG_ 997 TSG_FT_02_BZ "4bit Botschaftszaehler, wird mit jeder Sendebotschaft inkrementiert";
CM_ SG_ 997 FT_Tuer_Status "Tür geöffnet oder Tür geschlossen";
CM_ SG_ 997 FT_Tuer_Status_QBit "Dieses Bit gibt die Zuverlässigkeit des Türkontakts an.";
CM_ SG_ 997 FT_Lock_Taster_02 "Lock-Taster betätigt";
CM_ SG_ 997 FT_Schluesselschalter_zu_02 "Schlüsselschalter für Schließen betätigt";
CM_ SG_ 997 FT_BFS_Tuer_Status "Gesammelte Türstatusbotschaft";
CM_ SG_ 997 FT_HBFS_Tuer_Status "Türstatus mit Fehler und Initwert";
CM_ SG_ 997 FT_HFS_Tuer_Status "Türstatus mit Fehler und Initwert";
CM_ SG_ 997 FT_Tuerschloss_verrieg_nicht "Die Fahrertür kann nicht verriegelt werden.";
CM_ SG_ 997 FT_SP_Heizung_ein "Dieses Signal zeigt die tatsächliche Ansteuerung der  Spiegelheizung incl. PWM an. 
Zudem wird aufgrund des Teilnetzbetriebs das Signal zur Ansteuerung der Beifahrer-Spiegelheizung benutzt.

";
CM_ SG_ 997 FT_Kisi_Taster_li_02 "Der Kindersicherungstaster hinten links aktiv.";
CM_ SG_ 997 FT_Kisi_Taster_re_02 "Der Kindersicherungstaster hinten rechts aktiv.";
CM_ SG_ 997 FT_TD_Taste_Status "Status Taste für Tankdeckel";
CM_ SG_ 1449 TSG_FlHz_FS_NTC_A "Flächenheizung: Temperatur und Fehlerwert des Heizaktors";
CM_ SG_ 1449 TSG_FlHz_FS_FnAbbruchHzKreis_A "Flächenheizung: Status";
CM_ SG_ 1449 TSG_FlHz_FS_NTC_B "Flächenheizung: Temperatur und Fehlerwert des Heizaktors";
CM_ SG_ 1449 TSG_FlHz_FS_FnAbbruchHzKreis_B "Flächenheizung: Status";
BA_DEF_ BO_  "DiagRequest" ENUM  "No","Yes";
BA_DEF_ BO_  "DiagResponse" ENUM  "No","Yes";
BA_DEF_ BO_  "DiagState" ENUM  "No","Yes";
BA_DEF_ BO_  "GenMsgChkConstant" HEX 0 4095;
BA_DEF_ BO_  "GenMsgCycleTime" INT 0 65535;
BA_DEF_ BO_  "GenMsgCycleTimeFast" INT 0 65535;
BA_DEF_ BO_  "GenMsgDelayTime" INT 0 100000;
BA_DEF_ BO_  "GenMsgILSupport" ENUM  "No","Yes";
BA_DEF_ BO_  "GenMsgNrOfRepetition" INT 0 100;
BA_DEF_ BO_  "GenMsgPDUConstants" STRING ;
BA_DEF_ BO_  "GenMsgSendType" ENUM  "Cyclic","not_used","not_used","not_used","not_used","not_used","not_used","IfActive","NoMsgSendType";
BA_DEF_ BO_  "GenMsgStartDelayTime" INT 0 100000;
BA_DEF_ BO_  "NmMessage" ENUM  "No","Yes";
BA_DEF_ BO_  "NmhMessage" ENUM  "No","Yes";
BA_DEF_ BO_  "MsgType" ENUM  "Application","NM ","NMH","TP2.0","ISO-TP ","BAP","EID";
BA_DEF_ BO_  "VAGTP20_API" HEX 0 255;
BA_DEF_ BO_  "VAGTP20_DynConnection" ENUM  "No","Yes";
BA_DEF_ BO_  "VAGTP20_DynSetup" ENUM  "No","Yes";
BA_DEF_ BO_  "VAGTP20_StatConnection" ENUM  "No","Yes";
BA_DEF_ SG_  "GenSigActiveRepetitions" INT -2147483648 2147483647;
BA_DEF_ SG_  "GenSigInactiveValue" INT -2147483648 2147483647;
BA_DEF_ SG_  "GenSigSendType" ENUM  "Cyclic","OnWrite","OnWriteWithRepetition","OnChange","OnChangeWithRepetition","IfActive","IfActiveWithRepetition","NoSigSendType","OnChangeAndIfActive","OnChangeAndIfActiveWithRepetition";
BA_DEF_ SG_  "GenSigStartValue" INT -2147483648 2147483647;
BA_DEF_ SG_  "NWM-WakeupAllowed" ENUM  "No","Yes";
BA_DEF_ SG_  "GenSigFuncType" ENUM  "NoFunction","MsgCounter","CRC-8","XOR","XOR-2","DatedBit","SW-Kl15","CHK","Constant","Protocol","CRC-8-SAE_J1850";
BA_DEF_ SG_  "GenSigSwitchedByIgnition" ENUM  "No","Yes";
BA_DEF_ SG_  "Fehlerwert" HEX 0 2147483647;
BA_DEF_ SG_  "GenSigMissingSourceValue" HEX 0 2147483647;
BA_DEF_REL_ BU_SG_REL_  "GenSigTimeoutTime" INT 0 65535;
BA_DEF_DEF_  "DiagRequest" "No";
BA_DEF_DEF_  "DiagResponse" "No";
BA_DEF_DEF_  "DiagState" "No";
BA_DEF_DEF_  "GenMsgChkConstant" 0;
BA_DEF_DEF_  "GenMsgCycleTime" 0;
BA_DEF_DEF_  "GenMsgCycleTimeFast" 0;
BA_DEF_DEF_  "GenMsgDelayTime" 0;
BA_DEF_DEF_  "GenMsgILSupport" "No";
BA_DEF_DEF_  "GenMsgNrOfRepetition" 0;
BA_DEF_DEF_  "GenMsgPDUConstants" "";
BA_DEF_DEF_  "GenMsgSendType" "NoMsgSendType";
BA_DEF_DEF_  "GenMsgStartDelayTime" 0;
BA_DEF_DEF_  "NmMessage" "No";
BA_DEF_DEF_  "NmhMessage" "No";
BA_DEF_DEF_  "MsgType" "Application";
BA_DEF_DEF_  "VAGTP20_API" 0;
BA_DEF_DEF_  "VAGTP20_DynConnection" "No";
BA_DEF_DEF_  "VAGTP20_DynSetup" "No";
BA_DEF_DEF_  "VAGTP20_StatConnection" "No";
BA_DEF_DEF_  "GenSigActiveRepetitions" 0;
BA_DEF_DEF_  "GenSigInactiveValue" 0;
BA_DEF_DEF_  "GenSigSendType" "NoSigSendType";
BA_DEF_DEF_  "GenSigStartValue" 0;
BA_DEF_DEF_  "NWM-WakeupAllowed" "No";
BA_DEF_DEF_  "GenSigFuncType" "NoFunction";
BA_DEF_DEF_  "GenSigSwitchedByIgnition" "Yes";
BA_DEF_DEF_  "Fehlerwert" 0;
BA_DEF_DEF_  "GenSigMissingSourceValue" 0;
BA_DEF_DEF_REL_ "GenSigTimeoutTime" 0;
BA_ "GenMsgSendType" BO_ 1616 0;
BA_ "GenMsgILSupport" BO_ 1616 1;
BA_ "GenMsgDelayTime" BO_ 1616 50;
BA_ "GenMsgCycleTime" BO_ 1616 1000;
BA_ "GenMsgSendType" BO_ 695 0;
BA_ "GenMsgPDUConstants" BO_ 695 "0x5e,0xc7,0x04,0x11,0x4d,0x27,0x0d,0x31,0x91,0xb8,0x62,0x76,0x64,0x09,0xeb,0xec";
BA_ "GenMsgILSupport" BO_ 695 1;
BA_ "GenMsgCycleTime" BO_ 695 50;
BA_ "GenMsgSendType" BO_ 1529 0;
BA_ "GenMsgILSupport" BO_ 1529 1;
BA_ "GenMsgCycleTime" BO_ 1529 1000;
BA_ "GenMsgSendType" BO_ 1711 0;
BA_ "GenMsgILSupport" BO_ 1711 1;
BA_ "GenMsgDelayTime" BO_ 1711 100;
BA_ "GenMsgCycleTime" BO_ 1711 1000;
BA_ "GenMsgSendType" BO_ 1525 0;
BA_ "GenMsgILSupport" BO_ 1525 1;
BA_ "GenMsgCycleTime" BO_ 1525 1000;
BA_ "GenMsgSendType" BO_ 1527 0;
BA_ "GenMsgILSupport" BO_ 1527 1;
BA_ "GenMsgCycleTime" BO_ 1527 1000;
BA_ "GenMsgSendType" BO_ 1440 0;
BA_ "GenMsgILSupport" BO_ 1440 1;
BA_ "GenMsgCycleTime" BO_ 1440 200;
BA_ "GenMsgSendType" BO_ 1517 0;
BA_ "GenMsgILSupport" BO_ 1517 1;
BA_ "GenMsgDelayTime" BO_ 1517 100;
BA_ "GenMsgCycleTime" BO_ 1517 500;
BA_ "GenMsgSendType" BO_ 1504 0;
BA_ "GenMsgNrOfRepetition" BO_ 1504 5;
BA_ "GenMsgILSupport" BO_ 1504 1;
BA_ "GenMsgDelayTime" BO_ 1504 50;
BA_ "GenMsgCycleTimeFast" BO_ 1504 100;
BA_ "GenMsgCycleTime" BO_ 1504 500;
BA_ "GenMsgSendType" BO_ 424 0;
BA_ "GenMsgPDUConstants" BO_ 424 "0x11,0x17,0xbb,0xaa,0xd0,0x83,0xe1,0x8e,0xa3,0x4d,0xef,0x50,0x88,0xa5,0x22,0xf6";
BA_ "GenMsgILSupport" BO_ 424 1;
BA_ "GenMsgCycleTime" BO_ 424 20;
BA_ "GenMsgSendType" BO_ 1522 0;
BA_ "GenMsgILSupport" BO_ 1522 1;
BA_ "GenMsgDelayTime" BO_ 1522 50;
BA_ "GenMsgCycleTime" BO_ 1522 200;
BA_ "GenMsgSendType" BO_ 1363 0;
BA_ "GenMsgILSupport" BO_ 1363 1;
BA_ "GenMsgCycleTime" BO_ 1363 100;
BA_ "GenMsgSendType" BO_ 980 0;
BA_ "GenMsgPDUConstants" BO_ 980 "0xc3,0x79,0xbf,0xdb,0xe9,0x11,0x46,0x86,0x69,0xb6,0x9b,0x29,0x15,0x9c,0x45,0x0d";
BA_ "GenMsgNrOfRepetition" BO_ 980 5;
BA_ "GenMsgILSupport" BO_ 980 1;
BA_ "GenMsgDelayTime" BO_ 980 40;
BA_ "GenMsgCycleTimeFast" BO_ 980 80;
BA_ "GenMsgCycleTime" BO_ 980 200;
BA_ "GenMsgSendType" BO_ 1467 0;
BA_ "GenMsgILSupport" BO_ 1467 1;
BA_ "GenMsgCycleTime" BO_ 1467 500;
BA_ "GenMsgSendType" BO_ 1710 0;
BA_ "GenMsgILSupport" BO_ 1710 1;
BA_ "GenMsgDelayTime" BO_ 1710 50;
BA_ "GenMsgCycleTime" BO_ 1710 1000;
BA_ "GenMsgSendType" BO_ 904 0;
BA_ "GenMsgPDUConstants" BO_ 904 "0x1d,0x3c,0xee,0x54,0xe4,0xcf,0xad,0xa3,0x6b,0x81,0xb6,0x93,0xc8,0x0b,0x44,0xc7";
BA_ "GenMsgILSupport" BO_ 904 1;
BA_ "GenMsgCycleTime" BO_ 904 100;
BA_ "GenMsgSendType" BO_ 1313 0;
BA_ "GenMsgILSupport" BO_ 1313 1;
BA_ "GenMsgCycleTime" BO_ 1313 1000;
BA_ "GenMsgSendType" BO_ 1650 0;
BA_ "GenMsgILSupport" BO_ 1650 1;
BA_ "GenMsgCycleTime" BO_ 1650 500;
BA_ "GenMsgSendType" BO_ 1172 0;
BA_ "GenMsgPDUConstants" BO_ 1172 "0x90,0x90,0x90,0x90,0x90,0x90,0x90,0x90,0x90,0x90,0x90,0x90,0x90,0x90,0x90,0x90";
BA_ "GenMsgILSupport" BO_ 1172 1;
BA_ "GenMsgDelayTime" BO_ 1172 20;
BA_ "GenMsgCycleTime" BO_ 1172 200;
BA_ "GenMsgChkConstant" BO_ 1172 144;
BA_ "GenMsgSendType" BO_ 783 0;
BA_ "GenMsgPDUConstants" BO_ 783 "0x0c,0x0c,0x0c,0x0c,0x0c,0x0c,0x0c,0x0c,0x0c,0x0c,0x0c,0x0c,0x0c,0x0c,0x0c,0x0c";
BA_ "GenMsgILSupport" BO_ 783 1;
BA_ "GenMsgDelayTime" BO_ 783 50;
BA_ "GenMsgCycleTime" BO_ 783 200;
BA_ "GenMsgChkConstant" BO_ 783 12;
BA_ "GenMsgSendType" BO_ 673 0;
BA_ "GenMsgILSupport" BO_ 673 1;
BA_ "GenMsgDelayTime" BO_ 673 40;
BA_ "GenMsgCycleTime" BO_ 673 200;
BA_ "GenMsgSendType" BO_ 788 0;
BA_ "GenMsgILSupport" BO_ 788 1;
BA_ "GenMsgCycleTime" BO_ 788 40;
BA_ "GenMsgSendType" BO_ 1413 0;
BA_ "GenMsgILSupport" BO_ 1413 1;
BA_ "GenMsgDelayTime" BO_ 1413 10;
BA_ "GenMsgCycleTime" BO_ 1413 1000;
BA_ "GenMsgSendType" BO_ 1604 0;
BA_ "GenMsgILSupport" BO_ 1604 1;
BA_ "GenMsgCycleTime" BO_ 1604 500;
BA_ "GenMsgSendType" BO_ 977 0;
BA_ "GenMsgILSupport" BO_ 977 1;
BA_ "GenMsgDelayTime" BO_ 977 20;
BA_ "GenMsgCycleTime" BO_ 977 100;
BA_ "GenMsgSendType" BO_ 1451 0;
BA_ "GenMsgILSupport" BO_ 1451 1;
BA_ "GenMsgDelayTime" BO_ 1451 100;
BA_ "GenMsgCycleTime" BO_ 1451 1000;
BA_ "GenMsgSendType" BO_ 976 0;
BA_ "GenMsgILSupport" BO_ 976 1;
BA_ "GenMsgDelayTime" BO_ 976 20;
BA_ "GenMsgCycleTime" BO_ 976 100;
BA_ "GenMsgSendType" BO_ 997 0;
BA_ "GenMsgPDUConstants" BO_ 997 "0xc4,0x6a,0x69,0x30,0xcf,0x61,0x58,0x51,0x1b,0x86,0x99,0xd3,0xf6,0x1d,0x9a,0x37";
BA_ "GenMsgILSupport" BO_ 997 1;
BA_ "GenMsgDelayTime" BO_ 997 20;
BA_ "GenMsgCycleTime" BO_ 997 100;
BA_ "GenMsgSendType" BO_ 1449 0;
BA_ "GenMsgILSupport" BO_ 1449 1;
BA_ "GenMsgDelayTime" BO_ 1449 100;
BA_ "GenMsgCycleTime" BO_ 1449 1000;
BA_ "GenSigSwitchedByIgnition" SG_ 1616 RA_Radio_on 0;
BA_ "GenSigSendType" SG_ 1616 RA_Radio_on 3;
BA_ "GenSigSwitchedByIgnition" SG_ 1616 RA_PowerAmpOn 0;
BA_ "GenSigSendType" SG_ 1616 RA_PowerAmpOn 3;
BA_ "GenSigSwitchedByIgnition" SG_ 1616 RA_Radio_mute 0;
BA_ "GenSigSendType" SG_ 1616 RA_Radio_mute 3;
BA_ "GenSigSwitchedByIgnition" SG_ 1616 RA_VNC_OFF 0;
BA_ "GenSigSendType" SG_ 1616 RA_VNC_OFF 3;
BA_ "GenSigSwitchedByIgnition" SG_ 1616 RA_Radio_Surround 0;
BA_ "GenSigSendType" SG_ 1616 RA_Radio_Surround 3;
BA_ "GenSigSwitchedByIgnition" SG_ 1616 RA_Radio_Error_Flag 0;
BA_ "GenSigSendType" SG_ 1616 RA_Radio_Error_Flag 3;
BA_ "GenSigSwitchedByIgnition" SG_ 1616 RA_Frequency 0;
BA_ "GenSigSendType" SG_ 1616 RA_Frequency 3;
BA_ "GenSigSwitchedByIgnition" SG_ 1616 RA_Frequency_unit 0;
BA_ "GenSigSendType" SG_ 1616 RA_Frequency_unit 3;
BA_ "GenSigSwitchedByIgnition" SG_ 1616 RA_AM_Tuning 0;
BA_ "GenSigSendType" SG_ 1616 RA_AM_Tuning 3;
BA_ "GenSigFuncType" SG_ 695 RCTA_01_CRC 2;
BA_ "GenSigSendType" SG_ 695 RCTA_01_CRC 0;
BA_ "GenSigFuncType" SG_ 695 RCTA_01_BZ 1;
BA_ "GenSigSendType" SG_ 695 RCTA_01_BZ 0;
BA_ "GenSigSendType" SG_ 695 RCTA_Info_rechts 0;
BA_ "GenSigSendType" SG_ 695 RCTA_Anforderung_HMS 0;
BA_ "GenSigSendType" SG_ 695 RCTA_Bremsruck_Anforderung 0;
BA_ "GenSigSendType" SG_ 695 RCTA_Bremsruck_Freigabe 0;
BA_ "GenSigSendType" SG_ 695 RCTA_Info_links 0;
BA_ "Fehlerwert" SG_ 695 RCTA_Status 3;
BA_ "GenSigSendType" SG_ 695 RCTA_Status 0;
BA_ "GenSigSendType" SG_ 695 RCTA_Warnton 0;
BA_ "GenSigSendType" SG_ 695 RCTA_Notbremsung_Freigabe 0;
BA_ "Fehlerwert" SG_ 695 RCTA_Notbremsung_Anforderung 255;
BA_ "GenSigSendType" SG_ 695 RCTA_Notbremsung_Anforderung 0;
BA_ "GenSigSwitchedByIgnition" SG_ 1529 RDK_FMVSS138_Lampe 0;
BA_ "GenSigSendType" SG_ 1529 RDK_FMVSS138_Lampe 0;
BA_ "GenSigSwitchedByIgnition" SG_ 1529 RDK_FMVSS138_MIL 0;
BA_ "GenSigSendType" SG_ 1529 RDK_FMVSS138_MIL 0;
BA_ "GenSigSwitchedByIgnition" SG_ 1529 RDK_Kalibrierung 0;
BA_ "GenSigSendType" SG_ 1529 RDK_Kalibrierung 0;
BA_ "GenSigSwitchedByIgnition" SG_ 1529 RDK_Warnungen_02 0;
BA_ "GenSigSendType" SG_ 1529 RDK_Warnungen_02 0;
BA_ "GenSigSwitchedByIgnition" SG_ 1529 RDK_W_1_Reifen_HL 0;
BA_ "GenSigSendType" SG_ 1529 RDK_W_1_Reifen_HL 0;
BA_ "GenSigSwitchedByIgnition" SG_ 1529 RDK_W_1_Reifen_HR 0;
BA_ "GenSigSendType" SG_ 1529 RDK_W_1_Reifen_HR 0;
BA_ "GenSigSwitchedByIgnition" SG_ 1529 RDK_W_1_Reifen_VL 0;
BA_ "GenSigSendType" SG_ 1529 RDK_W_1_Reifen_VL 0;
BA_ "GenSigSwitchedByIgnition" SG_ 1529 RDK_W_1_Reifen_VR 0;
BA_ "GenSigSendType" SG_ 1529 RDK_W_1_Reifen_VR 0;
BA_ "GenSigSwitchedByIgnition" SG_ 1529 RDK_W_2_Reifen_HL 0;
BA_ "GenSigSendType" SG_ 1529 RDK_W_2_Reifen_HL 0;
BA_ "GenSigSwitchedByIgnition" SG_ 1529 RDK_W_2_Reifen_HR 0;
BA_ "GenSigSendType" SG_ 1529 RDK_W_2_Reifen_HR 0;
BA_ "GenSigSwitchedByIgnition" SG_ 1529 RDK_W_2_Reifen_VL 0;
BA_ "GenSigSendType" SG_ 1529 RDK_W_2_Reifen_VL 0;
BA_ "GenSigSwitchedByIgnition" SG_ 1529 RDK_W_2_Reifen_VR 0;
BA_ "GenSigSendType" SG_ 1529 RDK_W_2_Reifen_VR 0;
BA_ "GenSigSwitchedByIgnition" SG_ 1711 RV_Video_on 0;
BA_ "GenSigSendType" SG_ 1711 RV_Video_on 3;
BA_ "GenSigSwitchedByIgnition" SG_ 1711 RV_Dark_Screen 0;
BA_ "GenSigSendType" SG_ 1711 RV_Dark_Screen 3;
BA_ "GenSigSwitchedByIgnition" SG_ 1711 RV_HMI_Mode 0;
BA_ "GenSigSendType" SG_ 1711 RV_HMI_Mode 3;
BA_ "GenSigSendType" SG_ 1711 RV_GL_side 3;
BA_ "GenSigSwitchedByIgnition" SG_ 1711 RV_System_aktiv 0;
BA_ "GenSigSendType" SG_ 1711 RV_System_aktiv 3;
BA_ "GenSigSwitchedByIgnition" SG_ 1711 RV_Settings_enabled 0;
BA_ "GenSigSendType" SG_ 1711 RV_Settings_enabled 3;
BA_ "GenSigSwitchedByIgnition" SG_ 1711 RV_Menu_Item 0;
BA_ "GenSigSendType" SG_ 1711 RV_Menu_Item 3;
BA_ "GenSigSendType" SG_ 1711 SV_Video_on 3;
BA_ "GenSigSwitchedByIgnition" SG_ 1711 RV_Calib_Fehler 0;
BA_ "GenSigSendType" SG_ 1711 RV_Calib_Fehler 3;
BA_ "GenSigSwitchedByIgnition" SG_ 1711 RV_GL_Trailer_connect 0;
BA_ "GenSigSendType" SG_ 1711 RV_GL_Trailer_connect 3;
BA_ "GenSigSwitchedByIgnition" SG_ 1711 RV_GL_Trunk_open 0;
BA_ "GenSigSendType" SG_ 1711 RV_GL_Trunk_open 3;
BA_ "GenSigSwitchedByIgnition" SG_ 1711 RV_GL_LWS_Fehler 0;
BA_ "GenSigSendType" SG_ 1711 RV_GL_LWS_Fehler 3;
BA_ "GenSigSwitchedByIgnition" SG_ 1711 RV_Helligkeit 0;
BA_ "GenSigSendType" SG_ 1711 RV_Helligkeit 3;
BA_ "GenSigSwitchedByIgnition" SG_ 1711 RV_Kontrast 0;
BA_ "GenSigSendType" SG_ 1711 RV_Kontrast 3;
BA_ "GenSigSwitchedByIgnition" SG_ 1711 RV_Farbe 0;
BA_ "GenSigSendType" SG_ 1711 RV_Farbe 3;
BA_ "Fehlerwert" SG_ 1525 RW_Gesamt_Reichweite_Max_Anzeige 2047;
BA_ "GenSigSwitchedByIgnition" SG_ 1525 RW_Gesamt_Reichweite_Max_Anzeige 0;
BA_ "GenSigStartValue" SG_ 1525 RW_Gesamt_Reichweite_Max_Anzeige 2046;
BA_ "GenSigSendType" SG_ 1525 RW_Gesamt_Reichweite_Max_Anzeige 0;
BA_ "Fehlerwert" SG_ 1525 RW_RWDS_Lastprofil 2047;
BA_ "GenSigSwitchedByIgnition" SG_ 1525 RW_RWDS_Lastprofil 0;
BA_ "GenSigStartValue" SG_ 1525 RW_RWDS_Lastprofil 2046;
BA_ "GenSigSendType" SG_ 1525 RW_RWDS_Lastprofil 0;
BA_ "Fehlerwert" SG_ 1525 RW_Gesamt_Reichweite 2047;
BA_ "GenSigSwitchedByIgnition" SG_ 1525 RW_Gesamt_Reichweite 0;
BA_ "GenSigStartValue" SG_ 1525 RW_Gesamt_Reichweite 2046;
BA_ "GenSigSendType" SG_ 1525 RW_Gesamt_Reichweite 0;
BA_ "GenSigSwitchedByIgnition" SG_ 1525 RW_Prim_Reichweitenverbrauch 0;
BA_ "GenSigStartValue" SG_ 1525 RW_Prim_Reichweitenverbrauch 2047;
BA_ "GenSigSendType" SG_ 1525 RW_Prim_Reichweitenverbrauch 0;
BA_ "GenSigSwitchedByIgnition" SG_ 1525 RW_Prim_Reichweitenv_Einheit 0;
BA_ "GenSigStartValue" SG_ 1525 RW_Prim_Reichweitenv_Einheit 3;
BA_ "GenSigSendType" SG_ 1525 RW_Prim_Reichweitenv_Einheit 0;
BA_ "Fehlerwert" SG_ 1525 RW_Primaer_Reichweite 2047;
BA_ "GenSigSwitchedByIgnition" SG_ 1525 RW_Primaer_Reichweite 0;
BA_ "GenSigStartValue" SG_ 1525 RW_Primaer_Reichweite 2046;
BA_ "GenSigSendType" SG_ 1525 RW_Primaer_Reichweite 0;
BA_ "GenSigSwitchedByIgnition" SG_ 1527 RW_Reservewarnung_aktiv 0;
BA_ "GenSigSendType" SG_ 1527 RW_Reservewarnung_aktiv 0;
BA_ "GenSigSwitchedByIgnition" SG_ 1527 RW_Reichweite_Einheit_Anzeige 0;
BA_ "GenSigSendType" SG_ 1527 RW_Reichweite_Einheit_Anzeige 0;
BA_ "Fehlerwert" SG_ 1527 RW_Gesamt_Reichweite_Anzeige 2047;
BA_ "GenSigSwitchedByIgnition" SG_ 1527 RW_Gesamt_Reichweite_Anzeige 0;
BA_ "GenSigStartValue" SG_ 1527 RW_Gesamt_Reichweite_Anzeige 2046;
BA_ "GenSigSendType" SG_ 1527 RW_Gesamt_Reichweite_Anzeige 0;
BA_ "Fehlerwert" SG_ 1527 RW_Primaer_Reichweite_Anzeige 2047;
BA_ "GenSigSwitchedByIgnition" SG_ 1527 RW_Primaer_Reichweite_Anzeige 0;
BA_ "GenSigStartValue" SG_ 1527 RW_Primaer_Reichweite_Anzeige 2046;
BA_ "GenSigSendType" SG_ 1527 RW_Primaer_Reichweite_Anzeige 0;
BA_ "Fehlerwert" SG_ 1527 RW_Sekundaer_Reichweite_Anzeige 2047;
BA_ "GenSigSwitchedByIgnition" SG_ 1527 RW_Sekundaer_Reichweite_Anzeige 0;
BA_ "GenSigStartValue" SG_ 1527 RW_Sekundaer_Reichweite_Anzeige 2046;
BA_ "GenSigSendType" SG_ 1527 RW_Sekundaer_Reichweite_Anzeige 0;
BA_ "Fehlerwert" SG_ 1527 RW_Sekundaer_Reichweite 2047;
BA_ "GenSigSwitchedByIgnition" SG_ 1527 RW_Sekundaer_Reichweite 0;
BA_ "GenSigStartValue" SG_ 1527 RW_Sekundaer_Reichweite 2046;
BA_ "GenSigSendType" SG_ 1527 RW_Sekundaer_Reichweite 0;
BA_ "GenSigSwitchedByIgnition" SG_ 1527 RW_Sek_Reichweitenv_Einheit 0;
BA_ "GenSigStartValue" SG_ 1527 RW_Sek_Reichweitenv_Einheit 3;
BA_ "GenSigSendType" SG_ 1527 RW_Sek_Reichweitenv_Einheit 0;
BA_ "GenSigSwitchedByIgnition" SG_ 1527 RW_Sek_Reichweitenverbrauch 0;
BA_ "GenSigStartValue" SG_ 1527 RW_Sek_Reichweitenverbrauch 2047;
BA_ "GenSigSendType" SG_ 1527 RW_Sek_Reichweitenverbrauch 0;
BA_ "GenSigMissingSourceValue" SG_ 1440 LS_Helligkeit_IR 255;
BA_ "Fehlerwert" SG_ 1440 LS_Helligkeit_IR 255;
BA_ "GenSigSwitchedByIgnition" SG_ 1440 LS_Helligkeit_IR 0;
BA_ "GenSigStartValue" SG_ 1440 LS_Helligkeit_IR 254;
BA_ "GenSigSendType" SG_ 1440 LS_Helligkeit_IR 0;
BA_ "GenSigMissingSourceValue" SG_ 1440 LS_Helligkeit_FW 1023;
BA_ "Fehlerwert" SG_ 1440 LS_Helligkeit_FW 1023;
BA_ "GenSigSwitchedByIgnition" SG_ 1440 LS_Helligkeit_FW 0;
BA_ "GenSigStartValue" SG_ 1440 LS_Helligkeit_FW 1022;
BA_ "GenSigSendType" SG_ 1440 LS_Helligkeit_FW 0;
BA_ "GenSigSwitchedByIgnition" SG_ 1440 LS_defekt 0;
BA_ "GenSigSendType" SG_ 1440 LS_defekt 0;
BA_ "GenSigSwitchedByIgnition" SG_ 1440 LS_Verbau 0;
BA_ "GenSigSendType" SG_ 1440 LS_Verbau 0;
BA_ "GenSigMissingSourceValue" SG_ 1440 RS_Regenmenge 15;
BA_ "Fehlerwert" SG_ 1440 RS_Regenmenge 15;
BA_ "GenSigSwitchedByIgnition" SG_ 1440 RS_Regenmenge 0;
BA_ "GenSigStartValue" SG_ 1440 RS_Regenmenge 14;
BA_ "GenSigSendType" SG_ 1440 RS_Regenmenge 0;
BA_ "GenSigSwitchedByIgnition" SG_ 1440 RS_Verbau 0;
BA_ "GenSigSendType" SG_ 1440 RS_Verbau 0;
BA_ "GenSigSwitchedByIgnition" SG_ 1440 RS_Verglasung_schliessen 0;
BA_ "GenSigSendType" SG_ 1440 RS_Verglasung_schliessen 0;
BA_ "GenSigSwitchedByIgnition" SG_ 1440 RS_defekt 0;
BA_ "GenSigSendType" SG_ 1440 RS_defekt 0;
BA_ "GenSigSwitchedByIgnition" SG_ 1440 RS_Wischergeschwindigkeit 0;
BA_ "GenSigSendType" SG_ 1440 RS_Wischergeschwindigkeit 0;
BA_ "GenSigStartValue" SG_ 1440 RLS_Vorfeldhelligkeit_Boost 15;
BA_ "GenSigSendType" SG_ 1440 RLS_Vorfeldhelligkeit_Boost 0;
BA_ "GenSigSwitchedByIgnition" SG_ 1517 SAD2_Deckel_Lage 0;
BA_ "GenSigSendType" SG_ 1517 SAD2_Deckel_Lage 0;
BA_ "GenSigSwitchedByIgnition" SG_ 1517 SAD2_Deckel_normiert 0;
BA_ "GenSigSendType" SG_ 1517 SAD2_Deckel_normiert 3;
BA_ "GenSigSwitchedByIgnition" SG_ 1517 SAD2_Deckel_Thermoschutz 0;
BA_ "GenSigSendType" SG_ 1517 SAD2_Deckel_Thermoschutz 3;
BA_ "GenSigSwitchedByIgnition" SG_ 1517 SAD2_Deckel_UEKB_aktiv 0;
BA_ "GenSigSendType" SG_ 1517 SAD2_Deckel_UEKB_aktiv 3;
BA_ "GenSigSwitchedByIgnition" SG_ 1517 SAD2_Deckel_Position 0;
BA_ "GenSigSendType" SG_ 1517 SAD2_Deckel_Position 3;
BA_ "GenSigSwitchedByIgnition" SG_ 1517 SAD2_Rollo_Lage 0;
BA_ "GenSigSendType" SG_ 1517 SAD2_Rollo_Lage 0;
BA_ "GenSigSwitchedByIgnition" SG_ 1517 SAD2_Rollo_Position 0;
BA_ "GenSigSendType" SG_ 1517 SAD2_Rollo_Position 0;
BA_ "GenSigSwitchedByIgnition" SG_ 1517 SAD2_Rollo_normiert 0;
BA_ "GenSigSendType" SG_ 1517 SAD2_Rollo_normiert 3;
BA_ "GenSigSwitchedByIgnition" SG_ 1517 SAD2_Rollo_Thermoschutz 0;
BA_ "GenSigSendType" SG_ 1517 SAD2_Rollo_Thermoschutz 3;
BA_ "GenSigSwitchedByIgnition" SG_ 1517 SAD2_Rollo_UEKB_aktiv 0;
BA_ "GenSigSendType" SG_ 1517 SAD2_Rollo_UEKB_aktiv 3;
BA_ "GenSigSwitchedByIgnition" SG_ 1504 MD1_Position 0;
BA_ "GenSigSendType" SG_ 1504 MD1_Position 3;
BA_ "GenSigSwitchedByIgnition" SG_ 1504 MD1_Lage 0;
BA_ "GenSigSendType" SG_ 1504 MD1_Lage 0;
BA_ "GenSigSwitchedByIgnition" SG_ 1504 MD3_Position 0;
BA_ "GenSigSendType" SG_ 1504 MD3_Position 0;
BA_ "GenSigSwitchedByIgnition" SG_ 1504 MD3_Lage 0;
BA_ "GenSigSendType" SG_ 1504 MD3_Lage 0;
BA_ "GenSigSwitchedByIgnition" SG_ 1504 MRollo_Position 0;
BA_ "GenSigSendType" SG_ 1504 MRollo_Position 0;
BA_ "GenSigSwitchedByIgnition" SG_ 1504 MRollo_Lage 0;
BA_ "GenSigSendType" SG_ 1504 MRollo_Lage 0;
BA_ "GenSigSwitchedByIgnition" SG_ 1504 SAD_normiert 0;
BA_ "GenSigSendType" SG_ 1504 SAD_normiert 3;
BA_ "GenSigSwitchedByIgnition" SG_ 1504 SAD_Thermoschutz 0;
BA_ "GenSigSendType" SG_ 1504 SAD_Thermoschutz 3;
BA_ "GenSigSwitchedByIgnition" SG_ 1504 SAD_UEKB_aktiv 0;
BA_ "GenSigSendType" SG_ 1504 SAD_UEKB_aktiv 3;
BA_ "GenSigSwitchedByIgnition" SG_ 1504 Rollo_normiert 0;
BA_ "GenSigSendType" SG_ 1504 Rollo_normiert 3;
BA_ "GenSigSwitchedByIgnition" SG_ 1504 Rollo_Thermoschutz 0;
BA_ "GenSigSendType" SG_ 1504 Rollo_Thermoschutz 3;
BA_ "GenSigSwitchedByIgnition" SG_ 1504 Rollo_UEKB_aktiv 0;
BA_ "GenSigSendType" SG_ 1504 Rollo_UEKB_aktiv 3;
BA_ "GenSigSwitchedByIgnition" SG_ 1504 SAD_Taster_Deckel_hi 0;
BA_ "GenSigSendType" SG_ 1504 SAD_Taster_Deckel_hi 4;
BA_ "GenSigActiveRepetitions" SG_ 1504 SAD_Taster_Deckel_hi 5;
BA_ "GenSigSwitchedByIgnition" SG_ 1504 SAD_Taster_Deckel_vo 0;
BA_ "GenSigSendType" SG_ 1504 SAD_Taster_Deckel_vo 4;
BA_ "GenSigActiveRepetitions" SG_ 1504 SAD_Taster_Deckel_vo 5;
BA_ "GenSigSwitchedByIgnition" SG_ 1504 SAD_Taster_Rollo_hi 0;
BA_ "GenSigSendType" SG_ 1504 SAD_Taster_Rollo_hi 4;
BA_ "GenSigActiveRepetitions" SG_ 1504 SAD_Taster_Rollo_hi 5;
BA_ "GenSigSwitchedByIgnition" SG_ 1504 SAD_Taster_Rollo_vo 0;
BA_ "GenSigSendType" SG_ 1504 SAD_Taster_Rollo_vo 4;
BA_ "GenSigActiveRepetitions" SG_ 1504 SAD_Taster_Rollo_vo 5;
BA_ "GenSigSwitchedByIgnition" SG_ 424 SARA_11_CRC 0;
BA_ "GenSigFuncType" SG_ 424 SARA_11_CRC 2;
BA_ "GenSigSendType" SG_ 424 SARA_11_CRC 0;
BA_ "GenSigSwitchedByIgnition" SG_ 424 SARA_11_BZ 0;
BA_ "GenSigFuncType" SG_ 424 SARA_11_BZ 1;
BA_ "GenSigSendType" SG_ 424 SARA_11_BZ 0;
BA_ "Fehlerwert" SG_ 424 SARA_Accel_X_r 8191;
BA_ "GenSigSwitchedByIgnition" SG_ 424 SARA_Accel_X_r 0;
BA_ "GenSigStartValue" SG_ 424 SARA_Accel_X_r 4096;
BA_ "GenSigSendType" SG_ 424 SARA_Accel_X_r 0;
BA_ "Fehlerwert" SG_ 424 SARA_Accel_Y_r 8191;
BA_ "GenSigSwitchedByIgnition" SG_ 424 SARA_Accel_Y_r 0;
BA_ "GenSigStartValue" SG_ 424 SARA_Accel_Y_r 4096;
BA_ "GenSigSendType" SG_ 424 SARA_Accel_Y_r 0;
BA_ "Fehlerwert" SG_ 424 SARA_Omega_Z_r 8191;
BA_ "GenSigSwitchedByIgnition" SG_ 424 SARA_Omega_Z_r 0;
BA_ "GenSigStartValue" SG_ 424 SARA_Omega_Z_r 4096;
BA_ "GenSigSendType" SG_ 424 SARA_Omega_Z_r 0;
BA_ "GenSigSwitchedByIgnition" SG_ 424 SARA_CF_Accel_X_r 0;
BA_ "GenSigStartValue" SG_ 424 SARA_CF_Accel_X_r 4;
BA_ "GenSigSendType" SG_ 424 SARA_CF_Accel_X_r 0;
BA_ "GenSigSwitchedByIgnition" SG_ 424 SARA_CF_Accel_Y_r 0;
BA_ "GenSigStartValue" SG_ 424 SARA_CF_Accel_Y_r 4;
BA_ "GenSigSendType" SG_ 424 SARA_CF_Accel_Y_r 0;
BA_ "GenSigSwitchedByIgnition" SG_ 424 SARA_CF_Omega_Z_r 0;
BA_ "GenSigStartValue" SG_ 424 SARA_CF_Omega_Z_r 4;
BA_ "GenSigSendType" SG_ 424 SARA_CF_Omega_Z_r 0;
BA_ "Fehlerwert" SG_ 1522 KBI_Phototransistor 255;
BA_ "GenSigSwitchedByIgnition" SG_ 1522 KBI_Phototransistor 0;
BA_ "GenSigStartValue" SG_ 1522 KBI_Phototransistor 254;
BA_ "GenSigSendType" SG_ 1522 KBI_Phototransistor 3;
BA_ "Fehlerwert" SG_ 1522 KBI_Dimmpoti 127;
BA_ "GenSigSwitchedByIgnition" SG_ 1522 KBI_Dimmpoti 0;
BA_ "GenSigSendType" SG_ 1522 KBI_Dimmpoti 0;
BA_ "GenSigSwitchedByIgnition" SG_ 1363 SR3_Status_Lehne_Links 0;
BA_ "GenSigSendType" SG_ 1363 SR3_Status_Lehne_Links 0;
BA_ "GenSigSwitchedByIgnition" SG_ 1363 SR3_Status_Lehne_Rechts 0;
BA_ "GenSigSendType" SG_ 1363 SR3_Status_Lehne_Rechts 0;
BA_ "GenSigSwitchedByIgnition" SG_ 980 SMLS_01_CRC 0;
BA_ "GenSigFuncType" SG_ 980 SMLS_01_CRC 2;
BA_ "GenSigSendType" SG_ 980 SMLS_01_CRC 0;
BA_ "GenSigSwitchedByIgnition" SG_ 980 SMLS_01_BZ 0;
BA_ "GenSigFuncType" SG_ 980 SMLS_01_BZ 1;
BA_ "GenSigSendType" SG_ 980 SMLS_01_BZ 0;
BA_ "GenSigSwitchedByIgnition" SG_ 980 BH_Blinker_li 0;
BA_ "GenSigSendType" SG_ 980 BH_Blinker_li 4;
BA_ "GenSigActiveRepetitions" SG_ 980 BH_Blinker_li 5;
BA_ "GenSigSwitchedByIgnition" SG_ 980 BH_Blinker_re 0;
BA_ "GenSigSendType" SG_ 980 BH_Blinker_re 4;
BA_ "GenSigActiveRepetitions" SG_ 980 BH_Blinker_re 5;
BA_ "GenSigSwitchedByIgnition" SG_ 980 BH_Lichthupe 0;
BA_ "GenSigSendType" SG_ 980 BH_Lichthupe 4;
BA_ "GenSigActiveRepetitions" SG_ 980 BH_Lichthupe 5;
BA_ "GenSigSwitchedByIgnition" SG_ 980 BH_Fernlicht 0;
BA_ "GenSigSendType" SG_ 980 BH_Fernlicht 3;
BA_ "GenSigSwitchedByIgnition" SG_ 980 WH_Tipwischen 0;
BA_ "GenSigSendType" SG_ 980 WH_Tipwischen 4;
BA_ "GenSigSwitchedByIgnition" SG_ 980 WH_Intervall 0;
BA_ "GenSigSendType" SG_ 980 WH_Intervall 3;
BA_ "GenSigSwitchedByIgnition" SG_ 980 WH_WischerStufe1 0;
BA_ "GenSigSendType" SG_ 980 WH_WischerStufe1 3;
BA_ "GenSigSwitchedByIgnition" SG_ 980 WH_WischerStufe2 0;
BA_ "GenSigSendType" SG_ 980 WH_WischerStufe2 3;
BA_ "GenSigSwitchedByIgnition" SG_ 980 WH_Frontwaschen 0;
BA_ "GenSigSendType" SG_ 980 WH_Frontwaschen 3;
BA_ "GenSigSwitchedByIgnition" SG_ 980 WH_Heckintervall 0;
BA_ "GenSigSendType" SG_ 980 WH_Heckintervall 3;
BA_ "GenSigSwitchedByIgnition" SG_ 980 WH_Heckwaschen 0;
BA_ "GenSigSendType" SG_ 980 WH_Heckwaschen 3;
BA_ "GenSigMissingSourceValue" SG_ 980 WH_Intervallstufen 15;
BA_ "Fehlerwert" SG_ 980 WH_Intervallstufen 15;
BA_ "GenSigSwitchedByIgnition" SG_ 980 WH_Intervallstufen 0;
BA_ "GenSigSendType" SG_ 980 WH_Intervallstufen 3;
BA_ "GenSigSwitchedByIgnition" SG_ 980 FAS_Taster 0;
BA_ "GenSigSendType" SG_ 980 FAS_Taster 3;
BA_ "Fehlerwert" SG_ 980 FAS_Taster_Fehler 1;
BA_ "GenSigSwitchedByIgnition" SG_ 980 FAS_Taster_Fehler 0;
BA_ "GenSigSendType" SG_ 980 FAS_Taster_Fehler 3;
BA_ "GenSigSwitchedByIgnition" SG_ 980 SMLS_Hupe 0;
BA_ "GenSigSendType" SG_ 980 SMLS_Hupe 4;
BA_ "GenSigActiveRepetitions" SG_ 980 SMLS_Hupe 5;
BA_ "Fehlerwert" SG_ 980 LRH_on_off 3;
BA_ "GenSigSwitchedByIgnition" SG_ 980 LRH_on_off 0;
BA_ "GenSigSendType" SG_ 980 LRH_on_off 3;
BA_ "GenSigSwitchedByIgnition" SG_ 980 LRH_aktiv 0;
BA_ "GenSigSendType" SG_ 980 LRH_aktiv 3;
BA_ "GenSigSwitchedByIgnition" SG_ 980 SMLS_P_verriegelt_plausibel 0;
BA_ "GenSigSendType" SG_ 980 SMLS_P_verriegelt_plausibel 3;
BA_ "GenSigSwitchedByIgnition" SG_ 980 WH_SRA 0;
BA_ "GenSigSendType" SG_ 980 WH_SRA 3;
BA_ "Fehlerwert" SG_ 980 WH_Wischer_Fehler 1;
BA_ "GenSigSwitchedByIgnition" SG_ 980 WH_Wischer_Fehler 0;
BA_ "GenSigSendType" SG_ 980 WH_Wischer_Fehler 3;
BA_ "Fehlerwert" SG_ 980 BH_Blinker_Fehler 1;
BA_ "GenSigSwitchedByIgnition" SG_ 980 BH_Blinker_Fehler 0;
BA_ "GenSigSendType" SG_ 980 BH_Blinker_Fehler 3;
BA_ "Fehlerwert" SG_ 1467 SoSe_SunInt_2D_Li 255;
BA_ "GenSigSwitchedByIgnition" SG_ 1467 SoSe_SunInt_2D_Li 0;
BA_ "GenSigStartValue" SG_ 1467 SoSe_SunInt_2D_Li 254;
BA_ "GenSigSendType" SG_ 1467 SoSe_SunInt_2D_Li 0;
BA_ "Fehlerwert" SG_ 1467 SoSe_SunInt_2D_Re 255;
BA_ "GenSigSwitchedByIgnition" SG_ 1467 SoSe_SunInt_2D_Re 0;
BA_ "GenSigStartValue" SG_ 1467 SoSe_SunInt_2D_Re 254;
BA_ "GenSigSendType" SG_ 1467 SoSe_SunInt_2D_Re 0;
BA_ "GenSigSwitchedByIgnition" SG_ 1710 SP_FT_oben 0;
BA_ "GenSigSendType" SG_ 1710 SP_FT_oben 3;
BA_ "GenSigSwitchedByIgnition" SG_ 1710 SP_FT_unten 0;
BA_ "GenSigSendType" SG_ 1710 SP_FT_unten 3;
BA_ "GenSigSwitchedByIgnition" SG_ 1710 SP_FT_links 0;
BA_ "GenSigSendType" SG_ 1710 SP_FT_links 3;
BA_ "GenSigSwitchedByIgnition" SG_ 1710 SP_FT_rechts 0;
BA_ "GenSigSendType" SG_ 1710 SP_FT_rechts 3;
BA_ "GenSigSwitchedByIgnition" SG_ 1710 SP_BT_oben 0;
BA_ "GenSigSendType" SG_ 1710 SP_BT_oben 3;
BA_ "GenSigSwitchedByIgnition" SG_ 1710 SP_BT_unten 0;
BA_ "GenSigSendType" SG_ 1710 SP_BT_unten 3;
BA_ "GenSigSwitchedByIgnition" SG_ 1710 SP_BT_links 0;
BA_ "GenSigSendType" SG_ 1710 SP_BT_links 3;
BA_ "GenSigSwitchedByIgnition" SG_ 1710 SP_BT_rechts 0;
BA_ "GenSigSendType" SG_ 1710 SP_BT_rechts 3;
BA_ "GenSigSwitchedByIgnition" SG_ 1710 SP_abklappen 0;
BA_ "GenSigSendType" SG_ 1710 SP_abklappen 3;
BA_ "GenSigSwitchedByIgnition" SG_ 1710 SP_anklappen 0;
BA_ "GenSigSendType" SG_ 1710 SP_anklappen 3;
BA_ "GenSigSwitchedByIgnition" SG_ 1710 SP_normieren 0;
BA_ "GenSigSendType" SG_ 1710 SP_normieren 3;
BA_ "GenSigSwitchedByIgnition" SG_ 1710 SP_Hzg_Taster 0;
BA_ "GenSigSendType" SG_ 1710 SP_Hzg_Taster 3;
BA_ "GenSigSwitchedByIgnition" SG_ 1710 SP_S_oben 0;
BA_ "GenSigSendType" SG_ 1710 SP_S_oben 3;
BA_ "GenSigSwitchedByIgnition" SG_ 1710 SP_S_unten 0;
BA_ "GenSigSendType" SG_ 1710 SP_S_unten 3;
BA_ "GenSigSwitchedByIgnition" SG_ 1710 SP_S_links 0;
BA_ "GenSigSendType" SG_ 1710 SP_S_links 3;
BA_ "GenSigSwitchedByIgnition" SG_ 1710 SP_S_rechts 0;
BA_ "GenSigSendType" SG_ 1710 SP_S_rechts 3;
BA_ "GenSigSwitchedByIgnition" SG_ 1710 SP_Auswahl_li 0;
BA_ "GenSigSendType" SG_ 1710 SP_Auswahl_li 3;
BA_ "GenSigSwitchedByIgnition" SG_ 1710 SP_Auswahl_re 0;
BA_ "GenSigSendType" SG_ 1710 SP_Auswahl_re 3;
BA_ "GenSigSendType" SG_ 1710 SP_ARA_Status 0;
BA_ "GenSigSwitchedByIgnition" SG_ 1710 SP_S_Klappen 0;
BA_ "GenSigSendType" SG_ 1710 SP_S_Klappen 3;
BA_ "Fehlerwert" SG_ 1710 SP_Verstellschalter_Fehler 1;
BA_ "GenSigSendType" SG_ 1710 SP_Verstellschalter_Fehler 0;
BA_ "GenSigSwitchedByIgnition" SG_ 904 SpoilerSG_01_CRC 0;
BA_ "GenSigFuncType" SG_ 904 SpoilerSG_01_CRC 2;
BA_ "GenSigSendType" SG_ 904 SpoilerSG_01_CRC 0;
BA_ "GenSigSwitchedByIgnition" SG_ 904 SpoilerSG_01_BZ 0;
BA_ "GenSigFuncType" SG_ 904 SpoilerSG_01_BZ 1;
BA_ "GenSigSendType" SG_ 904 SpoilerSG_01_BZ 0;
BA_ "Fehlerwert" SG_ 904 SpoilerSG_HSpoiler_IstPos 255;
BA_ "GenSigSwitchedByIgnition" SG_ 904 SpoilerSG_HSpoiler_IstPos 0;
BA_ "GenSigStartValue" SG_ 904 SpoilerSG_HSpoiler_IstPos 254;
BA_ "GenSigSendType" SG_ 904 SpoilerSG_HSpoiler_IstPos 0;
BA_ "GenSigSwitchedByIgnition" SG_ 904 SpoilerSG_Fehler 0;
BA_ "GenSigSendType" SG_ 904 SpoilerSG_Fehler 0;
BA_ "GenSigSwitchedByIgnition" SG_ 1313 STH_Funk_ein 0;
BA_ "GenSigSendType" SG_ 1313 STH_Funk_ein 0;
BA_ "GenSigSwitchedByIgnition" SG_ 1313 STH_Funk_aus 0;
BA_ "GenSigSendType" SG_ 1313 STH_Funk_aus 0;
BA_ "GenSigSwitchedByIgnition" SG_ 1313 STH_Zusatzheizung 0;
BA_ "GenSigSendType" SG_ 1313 STH_Zusatzheizung 0;
BA_ "GenSigSwitchedByIgnition" SG_ 1313 STH_LED 0;
BA_ "GenSigSendType" SG_ 1313 STH_LED 0;
BA_ "GenSigSwitchedByIgnition" SG_ 1313 STH_Pumpe_ein 0;
BA_ "GenSigSendType" SG_ 1313 STH_Pumpe_ein 0;
BA_ "GenSigSwitchedByIgnition" SG_ 1313 STH_Geblaese 0;
BA_ "GenSigSendType" SG_ 1313 STH_Geblaese 0;
BA_ "GenSigSwitchedByIgnition" SG_ 1313 STH_EKP_Anst 0;
BA_ "GenSigSendType" SG_ 1313 STH_EKP_Anst 0;
BA_ "GenSigSwitchedByIgnition" SG_ 1313 STH_Start_folgt 0;
BA_ "GenSigSendType" SG_ 1313 STH_Start_folgt 0;
BA_ "GenSigSwitchedByIgnition" SG_ 1313 STH_Ventiloeffnungszeit 0;
BA_ "GenSigSendType" SG_ 1313 STH_Ventiloeffnungszeit 0;
BA_ "GenSigSwitchedByIgnition" SG_ 1313 STH_Ventil_Status 0;
BA_ "GenSigSendType" SG_ 1313 STH_Ventil_Status 0;
BA_ "Fehlerwert" SG_ 1313 STH_Fehler_ElWaPu 1;
BA_ "GenSigSwitchedByIgnition" SG_ 1313 STH_Fehler_ElWaPu 0;
BA_ "GenSigSendType" SG_ 1313 STH_Fehler_ElWaPu 0;
BA_ "GenSigSwitchedByIgnition" SG_ 1313 STH_Waermeeintrag 0;
BA_ "GenSigSendType" SG_ 1313 STH_Waermeeintrag 0;
BA_ "GenSigSwitchedByIgnition" SG_ 1313 STH_Pumpen_Anf_extern 0;
BA_ "GenSigSendType" SG_ 1313 STH_Pumpen_Anf_extern 0;
BA_ "GenSigSwitchedByIgnition" SG_ 1313 STH_KVS 0;
BA_ "GenSigSendType" SG_ 1313 STH_KVS 0;
BA_ "GenSigSwitchedByIgnition" SG_ 1313 STH_Fehlerstatus 0;
BA_ "GenSigSendType" SG_ 1313 STH_Fehlerstatus 0;
BA_ "GenSigSwitchedByIgnition" SG_ 1313 STH_Heizleistung 0;
BA_ "GenSigSendType" SG_ 1313 STH_Heizleistung 0;
BA_ "Fehlerwert" SG_ 1313 STH_Wassertemp 255;
BA_ "GenSigSwitchedByIgnition" SG_ 1313 STH_Wassertemp 0;
BA_ "GenSigStartValue" SG_ 1313 STH_Wassertemp 254;
BA_ "GenSigSendType" SG_ 1313 STH_Wassertemp 0;
BA_ "GenSigSwitchedByIgnition" SG_ 1313 STH_Texte 0;
BA_ "GenSigSendType" SG_ 1313 STH_Texte 0;
BA_ "GenSigSwitchedByIgnition" SG_ 1313 STH_Motorvorwaermung 0;
BA_ "GenSigSendType" SG_ 1313 STH_Motorvorwaermung 0;
BA_ "GenSigSwitchedByIgnition" SG_ 1313 STH_Servicemode 0;
BA_ "GenSigSendType" SG_ 1313 STH_Servicemode 0;
BA_ "GenSigSwitchedByIgnition" SG_ 1313 STH_war_aktiv 0;
BA_ "GenSigSendType" SG_ 1313 STH_war_aktiv 0;
BA_ "GenSigSwitchedByIgnition" SG_ 1313 STH_KVS_Ueberlauf 0;
BA_ "GenSigSendType" SG_ 1313 STH_KVS_Ueberlauf 0;
BA_ "GenSigSwitchedByIgnition" SG_ 1650 STH_ZZ_Monat 0;
BA_ "GenSigSendType" SG_ 1650 STH_ZZ_Monat 0;
BA_ "GenSigSwitchedByIgnition" SG_ 1650 STH_ZZ_Tag 0;
BA_ "GenSigSendType" SG_ 1650 STH_ZZ_Tag 0;
BA_ "GenSigSwitchedByIgnition" SG_ 1650 STH_ZZ_Betriebsmodus 0;
BA_ "GenSigSendType" SG_ 1650 STH_ZZ_Betriebsmodus 0;
BA_ "GenSigSwitchedByIgnition" SG_ 1650 STH_ZZ_Minute 0;
BA_ "GenSigSendType" SG_ 1650 STH_ZZ_Minute 0;
BA_ "GenSigSwitchedByIgnition" SG_ 1650 STH_ZZ_Status_Timer 0;
BA_ "GenSigSendType" SG_ 1650 STH_ZZ_Status_Timer 0;
BA_ "GenSigSwitchedByIgnition" SG_ 1650 STH_ZZ_Stunde 0;
BA_ "GenSigSendType" SG_ 1650 STH_ZZ_Stunde 0;
BA_ "GenSigSwitchedByIgnition" SG_ 1650 STH_ZZ_Betriebsdauer 0;
BA_ "GenSigSendType" SG_ 1650 STH_ZZ_Betriebsdauer 0;
BA_ "GenSigSwitchedByIgnition" SG_ 1172 STS_01_CRC 0;
BA_ "GenSigFuncType" SG_ 1172 STS_01_CRC 2;
BA_ "GenSigSendType" SG_ 1172 STS_01_CRC 0;
BA_ "GenSigSwitchedByIgnition" SG_ 1172 STS_01_BZ 0;
BA_ "GenSigFuncType" SG_ 1172 STS_01_BZ 1;
BA_ "GenSigSendType" SG_ 1172 STS_01_BZ 0;
BA_ "GenSigSwitchedByIgnition" SG_ 1172 STS_Car_not_under_theft 0;
BA_ "GenSigStartValue" SG_ 1172 STS_Car_not_under_theft 1;
BA_ "GenSigSendType" SG_ 1172 STS_Car_not_under_theft 0;
BA_ "GenSigSwitchedByIgnition" SG_ 1172 STS_Car_under_theft 0;
BA_ "GenSigSendType" SG_ 1172 STS_Car_under_theft 0;
BA_ "GenSigSwitchedByIgnition" SG_ 1172 STS_Anlassersperre 0;
BA_ "GenSigSendType" SG_ 1172 STS_Anlassersperre 0;
BA_ "GenSigSwitchedByIgnition" SG_ 1172 STS_Typencodierung 0;
BA_ "GenSigSendType" SG_ 1172 STS_Typencodierung 0;
BA_ "GenSigSwitchedByIgnition" SG_ 1172 STS_LIN_aktiv 0;
BA_ "GenSigSendType" SG_ 1172 STS_LIN_aktiv 0;
BA_ "GenSigSwitchedByIgnition" SG_ 1172 STS_Standlicht 0;
BA_ "GenSigSendType" SG_ 1172 STS_Standlicht 3;
BA_ "GenSigSwitchedByIgnition" SG_ 1172 STS_Fahrlicht 0;
BA_ "GenSigSendType" SG_ 1172 STS_Fahrlicht 3;
BA_ "GenSigSwitchedByIgnition" SG_ 1172 STS_Alarm_still 0;
BA_ "GenSigSendType" SG_ 1172 STS_Alarm_still 0;
BA_ "Fehlerwert" SG_ 1172 STS_Texte 15;
BA_ "GenSigSwitchedByIgnition" SG_ 1172 STS_Texte 0;
BA_ "GenSigStartValue" SG_ 1172 STS_Texte 14;
BA_ "GenSigSendType" SG_ 1172 STS_Texte 0;
BA_ "GenSigSwitchedByIgnition" SG_ 1172 STS_Laderelais 0;
BA_ "GenSigSendType" SG_ 1172 STS_Laderelais 3;
BA_ "GenSigSwitchedByIgnition" SG_ 1172 STS_Summer 0;
BA_ "GenSigSendType" SG_ 1172 STS_Summer 3;
BA_ "GenSigSwitchedByIgnition" SG_ 1172 STS_Alarm_Blinker 0;
BA_ "GenSigSendType" SG_ 1172 STS_Alarm_Blinker 3;
BA_ "GenSigSwitchedByIgnition" SG_ 1172 STS_Notstart 0;
BA_ "GenSigSendType" SG_ 1172 STS_Notstart 3;
BA_ "GenSigSwitchedByIgnition" SG_ 1172 STS_Signalhorn 0;
BA_ "GenSigSendType" SG_ 1172 STS_Signalhorn 3;
BA_ "GenSigSwitchedByIgnition" SG_ 1172 STS_Leerlaufschaltung 0;
BA_ "GenSigSendType" SG_ 1172 STS_Leerlaufschaltung 0;
BA_ "GenSigSwitchedByIgnition" SG_ 783 SWA_01_CRC 0;
BA_ "GenSigFuncType" SG_ 783 SWA_01_CRC 2;
BA_ "GenSigSendType" SG_ 783 SWA_01_CRC 0;
BA_ "GenSigSwitchedByIgnition" SG_ 783 SWA_01_BZ 0;
BA_ "GenSigFuncType" SG_ 783 SWA_01_BZ 1;
BA_ "GenSigSendType" SG_ 783 SWA_01_BZ 0;
BA_ "GenSigSwitchedByIgnition" SG_ 783 SWA_Anzeigen 0;
BA_ "GenSigSendType" SG_ 783 SWA_Anzeigen 3;
BA_ "GenSigSendType" SG_ 783 SWA_Blindheit_erkannt 0;
BA_ "GenSigSendType" SG_ 783 SWA_rel_Nichtverf 0;
BA_ "Fehlerwert" SG_ 783 SWA_rel_Fehler 1;
BA_ "GenSigSendType" SG_ 783 SWA_rel_Fehler 0;
BA_ "GenSigSendType" SG_ 783 SWA_Sta_aktiv 0;
BA_ "GenSigSendType" SG_ 783 SWA_Sta_passiv 0;
BA_ "GenSigSwitchedByIgnition" SG_ 783 SWA_FT_RueckLED 0;
BA_ "GenSigSendType" SG_ 783 SWA_FT_RueckLED 3;
BA_ "Fehlerwert" SG_ 783 ASW_Status 2;
BA_ "GenSigSwitchedByIgnition" SG_ 783 ASW_Status 0;
BA_ "GenSigSendType" SG_ 783 ASW_Status 3;
BA_ "GenSigSendType" SG_ 783 SWA_Standziele_li 0;
BA_ "GenSigSendType" SG_ 783 SWA_Kolonne_li 0;
BA_ "GenSigSendType" SG_ 783 SWA_Infostufe_SWA_li 0;
BA_ "GenSigSendType" SG_ 783 SWA_Warnung_SWA_li 0;
BA_ "GenSigSwitchedByIgnition" SG_ 783 ASW_Warnung_FS 0;
BA_ "GenSigSendType" SG_ 783 ASW_Warnung_FS 3;
BA_ "GenSigSwitchedByIgnition" SG_ 783 ASW_Warnung_BFS 0;
BA_ "GenSigSendType" SG_ 783 ASW_Warnung_BFS 3;
BA_ "GenSigSwitchedByIgnition" SG_ 783 ASW_Kombitexte 0;
BA_ "GenSigSendType" SG_ 783 ASW_Kombitexte 3;
BA_ "GenSigSendType" SG_ 783 SWA_Kolonne_mi 0;
BA_ "GenSigSendType" SG_ 783 SWA_Standziele_re 0;
BA_ "GenSigSendType" SG_ 783 SWA_Kolonne_re 0;
BA_ "GenSigSendType" SG_ 783 SWA_Infostufe_SWA_re 0;
BA_ "GenSigSendType" SG_ 783 SWA_Warnung_SWA_re 0;
BA_ "GenSigSwitchedByIgnition" SG_ 783 HRE_Anzeigetexte 0;
BA_ "GenSigSendType" SG_ 783 HRE_Anzeigetexte 0;
BA_ "GenSigSendType" SG_ 783 SWA_Gischtzaehler 0;
BA_ "GenSigSwitchedByIgnition" SG_ 783 Heckradar_Kombitexte 0;
BA_ "GenSigSendType" SG_ 783 Heckradar_Kombitexte 3;
BA_ "GenSigSwitchedByIgnition" SG_ 783 RCTA_Kombitexte 0;
BA_ "GenSigSendType" SG_ 783 RCTA_Kombitexte 3;
BA_ "Fehlerwert" SG_ 673 SWA_LED_Hell_BFS 127;
BA_ "GenSigStartValue" SG_ 673 SWA_LED_Hell_BFS 126;
BA_ "GenSigSendType" SG_ 673 SWA_LED_Hell_BFS 3;
BA_ "Fehlerwert" SG_ 673 SWA_LED_Hell_FS 127;
BA_ "GenSigStartValue" SG_ 673 SWA_LED_Hell_FS 126;
BA_ "GenSigSendType" SG_ 673 SWA_LED_Hell_FS 3;
BA_ "GenSigSendType" SG_ 673 SWA_LED_Modus_BFS 3;
BA_ "GenSigSendType" SG_ 673 SWA_LED_Modus_FS 3;
BA_ "GenSigStartValue" SG_ 788 SWA_Obj_03_GeschwRelX 511;
BA_ "GenSigSendType" SG_ 788 SWA_Obj_03_GeschwRelX 0;
BA_ "GenSigSendType" SG_ 788 SWA_Obj_03_Gemessen 0;
BA_ "GenSigSwitchedByIgnition" SG_ 788 SWA_Obj_03_ID 0;
BA_ "GenSigStartValue" SG_ 788 SWA_Obj_03_ID 31;
BA_ "GenSigSendType" SG_ 788 SWA_Obj_03_ID 0;
BA_ "GenSigStartValue" SG_ 788 SWA_Obj_03_PositionX 511;
BA_ "GenSigSendType" SG_ 788 SWA_Obj_03_PositionX 0;
BA_ "GenSigStartValue" SG_ 788 SWA_Obj_03_PositionY 255;
BA_ "GenSigSendType" SG_ 788 SWA_Obj_03_PositionY 0;
BA_ "GenSigStartValue" SG_ 788 SWA_Obj_04_GeschwRelX 511;
BA_ "GenSigSendType" SG_ 788 SWA_Obj_04_GeschwRelX 0;
BA_ "GenSigSendType" SG_ 788 SWA_Obj_04_Gemessen 0;
BA_ "GenSigSwitchedByIgnition" SG_ 788 SWA_Obj_04_ID 0;
BA_ "GenSigStartValue" SG_ 788 SWA_Obj_04_ID 31;
BA_ "GenSigSendType" SG_ 788 SWA_Obj_04_ID 0;
BA_ "GenSigStartValue" SG_ 788 SWA_Obj_04_PositionX 511;
BA_ "GenSigSendType" SG_ 788 SWA_Obj_04_PositionX 0;
BA_ "GenSigStartValue" SG_ 788 SWA_Obj_04_PositionY 255;
BA_ "GenSigSendType" SG_ 788 SWA_Obj_04_PositionY 0;
BA_ "GenSigSwitchedByIgnition" SG_ 1413 SI_Sammel_SG_Fehler 0;
BA_ "GenSigStartValue" SG_ 1413 SI_Sammel_SG_Fehler 63;
BA_ "GenSigSendType" SG_ 1413 SI_Sammel_SG_Fehler 0;
BA_ "GenSigSwitchedByIgnition" SG_ 1413 SI_Diagnose_Aktiv 0;
BA_ "GenSigSendType" SG_ 1413 SI_Diagnose_Aktiv 3;
BA_ "GenSigSwitchedByIgnition" SG_ 1413 SI_QRS_Mode 0;
BA_ "GenSigSendType" SG_ 1413 SI_QRS_Mode 3;
BA_ "GenSigSwitchedByIgnition" SG_ 1413 SI_T_Mode 0;
BA_ "GenSigSendType" SG_ 1413 SI_T_Mode 3;
BA_ "GenSigSwitchedByIgnition" SG_ 1413 SI_NWDF 0;
BA_ "GenSigSendType" SG_ 1413 SI_NWDF 3;
BA_ "GenSigSwitchedByIgnition" SG_ 1413 SI_NWDF_gueltig 0;
BA_ "GenSigFuncType" SG_ 1413 SI_NWDF_gueltig 8;
BA_ "GenSigSendType" SG_ 1413 SI_NWDF_gueltig 3;
BA_ "GenSigSwitchedByIgnition" SG_ 1413 SI_Sammelfehler 0;
BA_ "GenSigSendType" SG_ 1413 SI_Sammelfehler 3;
BA_ "GenSigSendType" SG_ 1413 GW_KD_Fehler 3;
BA_ "GenSigSwitchedByIgnition" SG_ 1413 SI_T_Schutz 0;
BA_ "GenSigSendType" SG_ 1413 SI_T_Schutz 3;
BA_ "GenSigSwitchedByIgnition" SG_ 1413 SI_BUS_01 0;
BA_ "GenSigStartValue" SG_ 1413 SI_BUS_01 1;
BA_ "GenSigSendType" SG_ 1413 SI_BUS_01 3;
BA_ "GenSigSwitchedByIgnition" SG_ 1413 SI_BUS_02 0;
BA_ "GenSigStartValue" SG_ 1413 SI_BUS_02 1;
BA_ "GenSigSendType" SG_ 1413 SI_BUS_02 3;
BA_ "GenSigSwitchedByIgnition" SG_ 1413 SI_BUS_03 0;
BA_ "GenSigStartValue" SG_ 1413 SI_BUS_03 1;
BA_ "GenSigSendType" SG_ 1413 SI_BUS_03 3;
BA_ "GenSigSwitchedByIgnition" SG_ 1413 SI_BUS_04 0;
BA_ "GenSigStartValue" SG_ 1413 SI_BUS_04 1;
BA_ "GenSigSendType" SG_ 1413 SI_BUS_04 3;
BA_ "GenSigSwitchedByIgnition" SG_ 1413 SI_BUS_05 0;
BA_ "GenSigStartValue" SG_ 1413 SI_BUS_05 1;
BA_ "GenSigSendType" SG_ 1413 SI_BUS_05 3;
BA_ "GenSigSwitchedByIgnition" SG_ 1413 SI_BUS_06 0;
BA_ "GenSigStartValue" SG_ 1413 SI_BUS_06 1;
BA_ "GenSigSendType" SG_ 1413 SI_BUS_06 3;
BA_ "GenSigSwitchedByIgnition" SG_ 1413 SI_BUS_07 0;
BA_ "GenSigStartValue" SG_ 1413 SI_BUS_07 1;
BA_ "GenSigSendType" SG_ 1413 SI_BUS_07 3;
BA_ "GenSigSwitchedByIgnition" SG_ 1413 SI_BUS_08 0;
BA_ "GenSigStartValue" SG_ 1413 SI_BUS_08 1;
BA_ "GenSigSendType" SG_ 1413 SI_BUS_08 3;
BA_ "GenSigSwitchedByIgnition" SG_ 1413 SI_BUS_09 0;
BA_ "GenSigStartValue" SG_ 1413 SI_BUS_09 1;
BA_ "GenSigSendType" SG_ 1413 SI_BUS_09 3;
BA_ "GenSigSwitchedByIgnition" SG_ 1413 SI_BUS_10 0;
BA_ "GenSigStartValue" SG_ 1413 SI_BUS_10 1;
BA_ "GenSigSendType" SG_ 1413 SI_BUS_10 3;
BA_ "GenSigSwitchedByIgnition" SG_ 1413 SI_BUS_11 0;
BA_ "GenSigStartValue" SG_ 1413 SI_BUS_11 1;
BA_ "GenSigSendType" SG_ 1413 SI_BUS_11 3;
BA_ "GenSigSwitchedByIgnition" SG_ 1413 SI_BUS_12 0;
BA_ "GenSigStartValue" SG_ 1413 SI_BUS_12 1;
BA_ "GenSigSendType" SG_ 1413 SI_BUS_12 3;
BA_ "GenSigSwitchedByIgnition" SG_ 1413 SI_BUS_13 0;
BA_ "GenSigStartValue" SG_ 1413 SI_BUS_13 1;
BA_ "GenSigSendType" SG_ 1413 SI_BUS_13 3;
BA_ "GenSigSwitchedByIgnition" SG_ 1413 SI_BUS_14 0;
BA_ "GenSigStartValue" SG_ 1413 SI_BUS_14 1;
BA_ "GenSigSendType" SG_ 1413 SI_BUS_14 3;
BA_ "GenSigSwitchedByIgnition" SG_ 1413 SI_BUS_15 0;
BA_ "GenSigStartValue" SG_ 1413 SI_BUS_15 1;
BA_ "GenSigSendType" SG_ 1413 SI_BUS_15 3;
BA_ "GenSigSwitchedByIgnition" SG_ 1413 SI_Bus_Identifikation 0;
BA_ "GenSigFuncType" SG_ 1413 SI_Bus_Identifikation 8;
BA_ "GenSigSendType" SG_ 1413 SI_Bus_Identifikation 0;
BA_ "GenSigSwitchedByIgnition" SG_ 1413 SI_CAB 0;
BA_ "GenSigSendType" SG_ 1413 SI_CAB 3;
BA_ "Fehlerwert" SG_ 1604 TG_Geber_1 4095;
BA_ "GenSigSwitchedByIgnition" SG_ 1604 TG_Geber_1 0;
BA_ "GenSigSendType" SG_ 1604 TG_Geber_1 0;
BA_ "Fehlerwert" SG_ 1604 TG_Geber_2 4095;
BA_ "GenSigSwitchedByIgnition" SG_ 1604 TG_Geber_2 0;
BA_ "GenSigSendType" SG_ 1604 TG_Geber_2 0;
BA_ "Fehlerwert" SG_ 1604 TG_Geber_3 4095;
BA_ "GenSigSwitchedByIgnition" SG_ 1604 TG_Geber_3 0;
BA_ "GenSigSendType" SG_ 1604 TG_Geber_3 0;
BA_ "Fehlerwert" SG_ 1604 TG_Geber_4 4095;
BA_ "GenSigSwitchedByIgnition" SG_ 1604 TG_Geber_4 0;
BA_ "GenSigSendType" SG_ 1604 TG_Geber_4 0;
BA_ "Fehlerwert" SG_ 1604 TG_Guete_Geber_1 15;
BA_ "GenSigSwitchedByIgnition" SG_ 1604 TG_Guete_Geber_1 0;
BA_ "GenSigStartValue" SG_ 1604 TG_Guete_Geber_1 14;
BA_ "GenSigSendType" SG_ 1604 TG_Guete_Geber_1 0;
BA_ "Fehlerwert" SG_ 1604 TG_Guete_Geber_2 15;
BA_ "GenSigSwitchedByIgnition" SG_ 1604 TG_Guete_Geber_2 0;
BA_ "GenSigStartValue" SG_ 1604 TG_Guete_Geber_2 14;
BA_ "GenSigSendType" SG_ 1604 TG_Guete_Geber_2 0;
BA_ "Fehlerwert" SG_ 1604 TG_Guete_Geber_3 15;
BA_ "GenSigSwitchedByIgnition" SG_ 1604 TG_Guete_Geber_3 0;
BA_ "GenSigStartValue" SG_ 1604 TG_Guete_Geber_3 14;
BA_ "GenSigSendType" SG_ 1604 TG_Guete_Geber_3 0;
BA_ "Fehlerwert" SG_ 1604 TG_Guete_Geber_4 15;
BA_ "GenSigSwitchedByIgnition" SG_ 1604 TG_Guete_Geber_4 0;
BA_ "GenSigStartValue" SG_ 1604 TG_Guete_Geber_4 14;
BA_ "GenSigSendType" SG_ 1604 TG_Guete_Geber_4 0;
BA_ "GenSigSwitchedByIgnition" SG_ 977 BT_Tuer_geoeffnet 0;
BA_ "GenSigSendType" SG_ 977 BT_Tuer_geoeffnet 3;
BA_ "GenSigSwitchedByIgnition" SG_ 977 BT_verriegelt 0;
BA_ "GenSigSendType" SG_ 977 BT_verriegelt 3;
BA_ "GenSigSwitchedByIgnition" SG_ 977 BT_gesafet 0;
BA_ "GenSigSendType" SG_ 977 BT_gesafet 3;
BA_ "GenSigSwitchedByIgnition" SG_ 977 BT_Schluesselschalter_auf 0;
BA_ "GenSigSendType" SG_ 977 BT_Schluesselschalter_auf 3;
BA_ "GenSigSwitchedByIgnition" SG_ 977 BT_Schluesselschalter_zu 0;
BA_ "GenSigSendType" SG_ 977 BT_Schluesselschalter_zu 3;
BA_ "GenSigSwitchedByIgnition" SG_ 977 BT_Unlock_Taster 0;
BA_ "GenSigSendType" SG_ 977 BT_Unlock_Taster 3;
BA_ "GenSigSwitchedByIgnition" SG_ 977 BT_Lock_Taster 0;
BA_ "GenSigSendType" SG_ 977 BT_Lock_Taster 3;
BA_ "GenSigSwitchedByIgnition" SG_ 977 BT_Sperrklinke 0;
BA_ "GenSigSendType" SG_ 977 BT_Sperrklinke 3;
BA_ "GenSigSwitchedByIgnition" SG_ 977 BT_TAG_betaetigt 0;
BA_ "GenSigSendType" SG_ 977 BT_TAG_betaetigt 3;
BA_ "GenSigSwitchedByIgnition" SG_ 977 BT_TIG_betaetigt 0;
BA_ "GenSigSendType" SG_ 977 BT_TIG_betaetigt 3;
BA_ "GenSigSwitchedByIgnition" SG_ 977 BT_EC_Spiegel_Helligkeit 0;
BA_ "GenSigSendType" SG_ 977 BT_EC_Spiegel_Helligkeit 3;
BA_ "GenSigSwitchedByIgnition" SG_ 977 BT_Sp_Heizung_Anf 0;
BA_ "GenSigSendType" SG_ 977 BT_Sp_Heizung_Anf 0;
BA_ "Fehlerwert" SG_ 977 BT_Tuer_Status 3;
BA_ "GenSigSwitchedByIgnition" SG_ 977 BT_Tuer_Status 0;
BA_ "GenSigSendType" SG_ 977 BT_Tuer_Status 3;
BA_ "GenSigSwitchedByIgnition" SG_ 977 BT_TSG_hinten_verbaut 0;
BA_ "GenSigSendType" SG_ 977 BT_TSG_hinten_verbaut 3;
BA_ "GenSigSwitchedByIgnition" SG_ 977 BT_Sp_Blk_def 0;
BA_ "GenSigSendType" SG_ 977 BT_Sp_Blk_def 3;
BA_ "GenSigSwitchedByIgnition" SG_ 977 BT_FH_S_ManHoch 0;
BA_ "GenSigSendType" SG_ 977 BT_FH_S_ManHoch 3;
BA_ "GenSigSwitchedByIgnition" SG_ 977 BT_FH_S_AutoHoch 0;
BA_ "GenSigSendType" SG_ 977 BT_FH_S_AutoHoch 3;
BA_ "GenSigSwitchedByIgnition" SG_ 977 BT_FH_S_ManTief 0;
BA_ "GenSigSendType" SG_ 977 BT_FH_S_ManTief 3;
BA_ "GenSigSwitchedByIgnition" SG_ 977 BT_FH_S_AutoTief 0;
BA_ "GenSigSendType" SG_ 977 BT_FH_S_AutoTief 3;
BA_ "GenSigSwitchedByIgnition" SG_ 977 BT_FH_Oeffnung 0;
BA_ "GenSigSendType" SG_ 977 BT_FH_Oeffnung 3;
BA_ "GenSigSwitchedByIgnition" SG_ 977 BT_FH_Bew_hoch 0;
BA_ "GenSigSendType" SG_ 977 BT_FH_Bew_hoch 3;
BA_ "GenSigSwitchedByIgnition" SG_ 977 BT_FH_Bew_tief 0;
BA_ "GenSigSendType" SG_ 977 BT_FH_Bew_tief 3;
BA_ "GenSigSwitchedByIgnition" SG_ 977 BT_FH_Fang 0;
BA_ "GenSigSendType" SG_ 977 BT_FH_Fang 3;
BA_ "GenSigSwitchedByIgnition" SG_ 977 BT_FH_Block 0;
BA_ "GenSigSendType" SG_ 977 BT_FH_Block 3;
BA_ "GenSigSwitchedByIgnition" SG_ 977 BT_FH_Thermo 0;
BA_ "GenSigSendType" SG_ 977 BT_FH_Thermo 3;
BA_ "GenSigSwitchedByIgnition" SG_ 977 BT_UEKB_aktiviert 0;
BA_ "GenSigSendType" SG_ 977 BT_UEKB_aktiviert 3;
BA_ "Fehlerwert" SG_ 977 BT_Kisi_Fehler 1;
BA_ "GenSigSwitchedByIgnition" SG_ 977 BT_Kisi_Fehler 0;
BA_ "GenSigSendType" SG_ 977 BT_Kisi_Fehler 3;
BA_ "GenSigSwitchedByIgnition" SG_ 977 BT_FH_normiert 0;
BA_ "GenSigSendType" SG_ 977 BT_FH_normiert 3;
BA_ "GenSigSwitchedByIgnition" SG_ 977 BT_Schliesstaster 0;
BA_ "GenSigSendType" SG_ 977 BT_Schliesstaster 3;
BA_ "GenSigSwitchedByIgnition" SG_ 977 BT_Zuziehhilfe_aktiv 0;
BA_ "GenSigSendType" SG_ 977 BT_Zuziehhilfe_aktiv 3;
BA_ "GenSigSwitchedByIgnition" SG_ 977 BT_SP_ausgerastet 0;
BA_ "GenSigSendType" SG_ 977 BT_SP_ausgerastet 3;
BA_ "GenSigSwitchedByIgnition" SG_ 977 BT_SP_lr_aktiv 0;
BA_ "GenSigSendType" SG_ 977 BT_SP_lr_aktiv 3;
BA_ "GenSigSwitchedByIgnition" SG_ 977 BT_SP_ht_aktiv 0;
BA_ "GenSigSendType" SG_ 977 BT_SP_ht_aktiv 3;
BA_ "GenSigSwitchedByIgnition" SG_ 977 BT_SP_Heizung_aktiv 0;
BA_ "GenSigSendType" SG_ 977 BT_SP_Heizung_aktiv 3;
BA_ "GenSigSwitchedByIgnition" SG_ 977 BT_Oben_Block_erw 0;
BA_ "GenSigSendType" SG_ 977 BT_Oben_Block_erw 3;
BA_ "GenSigSwitchedByIgnition" SG_ 977 BT_Unten_Block_erw 0;
BA_ "GenSigSendType" SG_ 977 BT_Unten_Block_erw 3;
BA_ "GenSigSwitchedByIgnition" SG_ 977 BT_SP_Heizung_Status 0;
BA_ "GenSigSendType" SG_ 977 BT_SP_Heizung_Status 3;
BA_ "GenSigSwitchedByIgnition" SG_ 977 ASW_Warnung_aktiv_BFS 0;
BA_ "GenSigSendType" SG_ 977 ASW_Warnung_aktiv_BFS 3;
BA_ "GenSigSwitchedByIgnition" SG_ 977 BT_FH_Pos_oben 0;
BA_ "GenSigSendType" SG_ 977 BT_FH_Pos_oben 3;
BA_ "GenSigSwitchedByIgnition" SG_ 977 BT_Tuerschloss_defekt 0;
BA_ "GenSigSendType" SG_ 977 BT_Tuerschloss_defekt 0;
BA_ "GenSigSwitchedByIgnition" SG_ 977 BT_Tuerschloss_verrieg_nicht 0;
BA_ "GenSigSendType" SG_ 977 BT_Tuerschloss_verrieg_nicht 0;
BA_ "GenSigSwitchedByIgnition" SG_ 977 BT_Lock_Taster_inv 0;
BA_ "GenSigSendType" SG_ 977 BT_Lock_Taster_inv 3;
BA_ "GenSigSwitchedByIgnition" SG_ 977 BT_Schluesselschalter_zu_inv 0;
BA_ "GenSigSendType" SG_ 977 BT_Schluesselschalter_zu_inv 3;
BA_ "GenSigSwitchedByIgnition" SG_ 1451 TSG_FlHz_BFS_NTC_A 0;
BA_ "GenSigStartValue" SG_ 1451 TSG_FlHz_BFS_NTC_A 127;
BA_ "GenSigSendType" SG_ 1451 TSG_FlHz_BFS_NTC_A 3;
BA_ "GenSigSwitchedByIgnition" SG_ 1451 TSG_FlHz_BFS_FnAbbruchHzKreis_A 0;
BA_ "GenSigSendType" SG_ 1451 TSG_FlHz_BFS_FnAbbruchHzKreis_A 3;
BA_ "GenSigSwitchedByIgnition" SG_ 1451 TSG_FlHz_BFS_NTC_B 0;
BA_ "GenSigStartValue" SG_ 1451 TSG_FlHz_BFS_NTC_B 127;
BA_ "GenSigSendType" SG_ 1451 TSG_FlHz_BFS_NTC_B 3;
BA_ "GenSigSwitchedByIgnition" SG_ 1451 TSG_FlHz_BFS_FnAbbruchHzKreis_B 0;
BA_ "GenSigSendType" SG_ 1451 TSG_FlHz_BFS_FnAbbruchHzKreis_B 3;
BA_ "GenSigSwitchedByIgnition" SG_ 976 FT_Tuer_geoeffnet 0;
BA_ "GenSigSendType" SG_ 976 FT_Tuer_geoeffnet 3;
BA_ "GenSigSwitchedByIgnition" SG_ 976 FT_verriegelt 0;
BA_ "GenSigSendType" SG_ 976 FT_verriegelt 3;
BA_ "GenSigSwitchedByIgnition" SG_ 976 FT_gesafet 0;
BA_ "GenSigSendType" SG_ 976 FT_gesafet 3;
BA_ "GenSigSwitchedByIgnition" SG_ 976 FT_Schluesselschalter_auf 0;
BA_ "GenSigSendType" SG_ 976 FT_Schluesselschalter_auf 3;
BA_ "GenSigSwitchedByIgnition" SG_ 976 FT_Schluesselschalter_zu 0;
BA_ "GenSigSendType" SG_ 976 FT_Schluesselschalter_zu 3;
BA_ "GenSigSwitchedByIgnition" SG_ 976 FT_Unlock_Taster 0;
BA_ "GenSigSendType" SG_ 976 FT_Unlock_Taster 3;
BA_ "GenSigSwitchedByIgnition" SG_ 976 FT_Lock_Taster 0;
BA_ "GenSigSendType" SG_ 976 FT_Lock_Taster 3;
BA_ "GenSigSwitchedByIgnition" SG_ 976 FT_Sperrklinke 0;
BA_ "GenSigSendType" SG_ 976 FT_Sperrklinke 3;
BA_ "GenSigSwitchedByIgnition" SG_ 976 FT_TAG_betaetigt 0;
BA_ "GenSigSendType" SG_ 976 FT_TAG_betaetigt 3;
BA_ "GenSigSwitchedByIgnition" SG_ 976 FT_TIG_betaetigt 0;
BA_ "GenSigSendType" SG_ 976 FT_TIG_betaetigt 3;
BA_ "GenSigSwitchedByIgnition" SG_ 976 FT_IRUE_Taste 0;
BA_ "GenSigSendType" SG_ 976 FT_IRUE_Taste 3;
BA_ "GenSigSwitchedByIgnition" SG_ 976 FT_HD_Taste 0;
BA_ "GenSigSendType" SG_ 976 FT_HD_Taste 3;
BA_ "GenSigSwitchedByIgnition" SG_ 976 FT_TD_Taste_Fehler 0;
BA_ "GenSigSendType" SG_ 976 FT_TD_Taste_Fehler 0;
BA_ "GenSigSwitchedByIgnition" SG_ 976 FT_TD_Taste 0;
BA_ "GenSigSendType" SG_ 976 FT_TD_Taste 3;
BA_ "GenSigSwitchedByIgnition" SG_ 976 SSR_Temp_Freigabe 0;
BA_ "GenSigSendType" SG_ 976 SSR_Temp_Freigabe 0;
BA_ "GenSigSwitchedByIgnition" SG_ 976 FT_Sp_Heizung_Anf 0;
BA_ "GenSigSendType" SG_ 976 FT_Sp_Heizung_Anf 0;
BA_ "GenSigSwitchedByIgnition" SG_ 976 FT_HD_Taste_2 0;
BA_ "GenSigSendType" SG_ 976 FT_HD_Taste_2 3;
BA_ "GenSigSwitchedByIgnition" SG_ 976 FT_TSG_hinten_verbaut 0;
BA_ "GenSigSendType" SG_ 976 FT_TSG_hinten_verbaut 3;
BA_ "GenSigSwitchedByIgnition" SG_ 976 FT_Sp_Blk_def 0;
BA_ "GenSigSendType" SG_ 976 FT_Sp_Blk_def 3;
BA_ "GenSigSwitchedByIgnition" SG_ 976 FT_FH_S_ManHoch 0;
BA_ "GenSigSendType" SG_ 976 FT_FH_S_ManHoch 3;
BA_ "GenSigSwitchedByIgnition" SG_ 976 FT_FH_S_AutoHoch 0;
BA_ "GenSigSendType" SG_ 976 FT_FH_S_AutoHoch 3;
BA_ "GenSigSwitchedByIgnition" SG_ 976 FT_FH_S_ManTief 0;
BA_ "GenSigSendType" SG_ 976 FT_FH_S_ManTief 3;
BA_ "GenSigSwitchedByIgnition" SG_ 976 FT_FH_S_AutoTief 0;
BA_ "GenSigSendType" SG_ 976 FT_FH_S_AutoTief 3;
BA_ "GenSigSwitchedByIgnition" SG_ 976 FT_FH_Oeffnung 0;
BA_ "GenSigSendType" SG_ 976 FT_FH_Oeffnung 3;
BA_ "GenSigSwitchedByIgnition" SG_ 976 FT_FH_Bew_hoch 0;
BA_ "GenSigSendType" SG_ 976 FT_FH_Bew_hoch 3;
BA_ "GenSigSwitchedByIgnition" SG_ 976 FT_FH_Bew_tief 0;
BA_ "GenSigSendType" SG_ 976 FT_FH_Bew_tief 3;
BA_ "GenSigSwitchedByIgnition" SG_ 976 FT_FH_Fang 0;
BA_ "GenSigSendType" SG_ 976 FT_FH_Fang 3;
BA_ "GenSigSwitchedByIgnition" SG_ 976 FT_FH_Block 0;
BA_ "GenSigSendType" SG_ 976 FT_FH_Block 3;
BA_ "GenSigSwitchedByIgnition" SG_ 976 FT_FH_Thermo 0;
BA_ "GenSigSendType" SG_ 976 FT_FH_Thermo 3;
BA_ "GenSigSwitchedByIgnition" SG_ 976 FT_UEKB_aktiviert 0;
BA_ "GenSigSendType" SG_ 976 FT_UEKB_aktiviert 3;
BA_ "GenSigSendType" SG_ 976 ASW_HMI_defekt 0;
BA_ "GenSigSwitchedByIgnition" SG_ 976 FT_FH_normiert 0;
BA_ "GenSigSendType" SG_ 976 FT_FH_normiert 3;
BA_ "GenSigSwitchedByIgnition" SG_ 976 FT_Schliesstaster 0;
BA_ "GenSigSendType" SG_ 976 FT_Schliesstaster 3;
BA_ "GenSigSwitchedByIgnition" SG_ 976 FT_Zuziehhilfe_aktiv 0;
BA_ "GenSigSendType" SG_ 976 FT_Zuziehhilfe_aktiv 3;
BA_ "GenSigSwitchedByIgnition" SG_ 976 FT_SP_ausgerastet 0;
BA_ "GenSigSendType" SG_ 976 FT_SP_ausgerastet 3;
BA_ "GenSigSwitchedByIgnition" SG_ 976 FT_SP_lr_aktiv 0;
BA_ "GenSigSendType" SG_ 976 FT_SP_lr_aktiv 3;
BA_ "GenSigSwitchedByIgnition" SG_ 976 FT_SP_ht_aktiv 0;
BA_ "GenSigSendType" SG_ 976 FT_SP_ht_aktiv 3;
BA_ "GenSigSwitchedByIgnition" SG_ 976 ASW_wakeup 0;
BA_ "GenSigSendType" SG_ 976 ASW_wakeup 3;
BA_ "GenSigSwitchedByIgnition" SG_ 976 FT_Oben_Block_erw 0;
BA_ "GenSigSendType" SG_ 976 FT_Oben_Block_erw 3;
BA_ "GenSigSwitchedByIgnition" SG_ 976 FT_Unten_Block_erw 0;
BA_ "GenSigSendType" SG_ 976 FT_Unten_Block_erw 3;
BA_ "GenSigSwitchedByIgnition" SG_ 976 FT_Kisi_li_aktiv 0;
BA_ "GenSigSendType" SG_ 976 FT_Kisi_li_aktiv 3;
BA_ "GenSigSwitchedByIgnition" SG_ 976 FT_Kisi_re_aktiv 0;
BA_ "GenSigSendType" SG_ 976 FT_Kisi_re_aktiv 3;
BA_ "GenSigSwitchedByIgnition" SG_ 976 FT_Kisi_Taster_li 0;
BA_ "GenSigSendType" SG_ 976 FT_Kisi_Taster_li 3;
BA_ "GenSigSwitchedByIgnition" SG_ 976 FT_Kisi_Taster_re 0;
BA_ "GenSigSendType" SG_ 976 FT_Kisi_Taster_re 3;
BA_ "GenSigSwitchedByIgnition" SG_ 976 FT_BFS_Fond_Freigabe 0;
BA_ "GenSigSendType" SG_ 976 FT_BFS_Fond_Freigabe 3;
BA_ "Fehlerwert" SG_ 976 FT_Kisi_Fehler 1;
BA_ "GenSigSwitchedByIgnition" SG_ 976 FT_Kisi_Fehler 0;
BA_ "GenSigSendType" SG_ 976 FT_Kisi_Fehler 3;
BA_ "GenSigSwitchedByIgnition" SG_ 976 FT_Daemmglas 0;
BA_ "GenSigSendType" SG_ 976 FT_Daemmglas 3;
BA_ "GenSigSwitchedByIgnition" SG_ 976 FT_SP_Heizung_Status 0;
BA_ "GenSigSendType" SG_ 976 FT_SP_Heizung_Status 3;
BA_ "GenSigSwitchedByIgnition" SG_ 976 ASW_Warnung_aktiv_FS 0;
BA_ "GenSigSendType" SG_ 976 ASW_Warnung_aktiv_FS 3;
BA_ "GenSigSwitchedByIgnition" SG_ 976 FT_FH_Pos_oben 0;
BA_ "GenSigSendType" SG_ 976 FT_FH_Pos_oben 3;
BA_ "GenSigSwitchedByIgnition" SG_ 976 FT_Tuerschloss_defekt 0;
BA_ "GenSigSendType" SG_ 976 FT_Tuerschloss_defekt 0;
BA_ "GenSigSwitchedByIgnition" SG_ 976 FT_SWA_Taster 0;
BA_ "GenSigSendType" SG_ 976 FT_SWA_Taster 3;
BA_ "GenSigSwitchedByIgnition" SG_ 976 SWA_HMI_Diagnose 0;
BA_ "GenSigSendType" SG_ 976 SWA_HMI_Diagnose 0;
BA_ "GenSigSwitchedByIgnition" SG_ 997 TSG_FT_02_CRC 0;
BA_ "GenSigFuncType" SG_ 997 TSG_FT_02_CRC 2;
BA_ "GenSigSendType" SG_ 997 TSG_FT_02_CRC 0;
BA_ "GenSigSwitchedByIgnition" SG_ 997 TSG_FT_02_BZ 0;
BA_ "GenSigFuncType" SG_ 997 TSG_FT_02_BZ 1;
BA_ "GenSigSendType" SG_ 997 TSG_FT_02_BZ 0;
BA_ "Fehlerwert" SG_ 997 FT_Tuer_Status 3;
BA_ "GenSigSwitchedByIgnition" SG_ 997 FT_Tuer_Status 0;
BA_ "GenSigSendType" SG_ 997 FT_Tuer_Status 3;
BA_ "GenSigSwitchedByIgnition" SG_ 997 FT_Tuer_Status_QBit 0;
BA_ "GenSigSendType" SG_ 997 FT_Tuer_Status_QBit 3;
BA_ "GenSigSwitchedByIgnition" SG_ 997 FT_Lock_Taster_02 0;
BA_ "GenSigSendType" SG_ 997 FT_Lock_Taster_02 3;
BA_ "GenSigSwitchedByIgnition" SG_ 997 FT_Schluesselschalter_zu_02 0;
BA_ "GenSigSendType" SG_ 997 FT_Schluesselschalter_zu_02 3;
BA_ "Fehlerwert" SG_ 997 FT_BFS_Tuer_Status 3;
BA_ "GenSigSwitchedByIgnition" SG_ 997 FT_BFS_Tuer_Status 0;
BA_ "GenSigSendType" SG_ 997 FT_BFS_Tuer_Status 3;
BA_ "Fehlerwert" SG_ 997 FT_HBFS_Tuer_Status 3;
BA_ "GenSigSwitchedByIgnition" SG_ 997 FT_HBFS_Tuer_Status 0;
BA_ "GenSigSendType" SG_ 997 FT_HBFS_Tuer_Status 3;
BA_ "Fehlerwert" SG_ 997 FT_HFS_Tuer_Status 3;
BA_ "GenSigSwitchedByIgnition" SG_ 997 FT_HFS_Tuer_Status 0;
BA_ "GenSigSendType" SG_ 997 FT_HFS_Tuer_Status 3;
BA_ "GenSigSwitchedByIgnition" SG_ 997 FT_Tuerschloss_verrieg_nicht 0;
BA_ "GenSigSendType" SG_ 997 FT_Tuerschloss_verrieg_nicht 0;
BA_ "GenSigSwitchedByIgnition" SG_ 997 FT_SP_Heizung_ein 0;
BA_ "GenSigSendType" SG_ 997 FT_SP_Heizung_ein 3;
BA_ "GenSigSwitchedByIgnition" SG_ 997 FT_Kisi_Taster_li_02 0;
BA_ "GenSigSendType" SG_ 997 FT_Kisi_Taster_li_02 3;
BA_ "GenSigSwitchedByIgnition" SG_ 997 FT_Kisi_Taster_re_02 0;
BA_ "GenSigSendType" SG_ 997 FT_Kisi_Taster_re_02 3;
BA_ "GenSigSwitchedByIgnition" SG_ 997 FT_TD_Taste_Status 0;
BA_ "GenSigSendType" SG_ 997 FT_TD_Taste_Status 3;
BA_ "GenSigSwitchedByIgnition" SG_ 1449 TSG_FlHz_FS_NTC_A 0;
BA_ "GenSigStartValue" SG_ 1449 TSG_FlHz_FS_NTC_A 127;
BA_ "GenSigSendType" SG_ 1449 TSG_FlHz_FS_NTC_A 3;
BA_ "GenSigSwitchedByIgnition" SG_ 1449 TSG_FlHz_FS_FnAbbruchHzKreis_A 0;
BA_ "GenSigSendType" SG_ 1449 TSG_FlHz_FS_FnAbbruchHzKreis_A 3;
BA_ "GenSigSwitchedByIgnition" SG_ 1449 TSG_FlHz_FS_NTC_B 0;
BA_ "GenSigStartValue" SG_ 1449 TSG_FlHz_FS_NTC_B 127;
BA_ "GenSigSendType" SG_ 1449 TSG_FlHz_FS_NTC_B 3;
BA_ "GenSigSwitchedByIgnition" SG_ 1449 TSG_FlHz_FS_FnAbbruchHzKreis_B 0;
BA_ "GenSigSendType" SG_ 1449 TSG_FlHz_FS_FnAbbruchHzKreis_B 3;
BA_REL_ "GenSigTimeoutTime" BU_SG_REL_ TSG_BFS SG_ 1616 RA_Radio_on 5000;
BA_REL_ "GenSigTimeoutTime" BU_SG_REL_ TSG_FS SG_ 1616 RA_Radio_on 5000;
BA_REL_ "GenSigTimeoutTime" BU_SG_REL_ HDSG SG_ 1616 RA_Frequency 5000;
BA_REL_ "GenSigTimeoutTime" BU_SG_REL_ SAD SG_ 1616 RA_Frequency 5000;
BA_REL_ "GenSigTimeoutTime" BU_SG_REL_ SAD2 SG_ 1616 RA_Frequency 5000;
BA_REL_ "GenSigTimeoutTime" BU_SG_REL_ SitzMem_BFS SG_ 1616 RA_Frequency 5000;
BA_REL_ "GenSigTimeoutTime" BU_SG_REL_ SitzMem_FS SG_ 1616 RA_Frequency 5000;
BA_REL_ "GenSigTimeoutTime" BU_SG_REL_ SitzMem_HBFS SG_ 1616 RA_Frequency 5000;
BA_REL_ "GenSigTimeoutTime" BU_SG_REL_ SitzMem_HFS SG_ 1616 RA_Frequency 5000;
BA_REL_ "GenSigTimeoutTime" BU_SG_REL_ TSG_BFS SG_ 1616 RA_Frequency 5000;
BA_REL_ "GenSigTimeoutTime" BU_SG_REL_ TSG_FS SG_ 1616 RA_Frequency 5000;
BA_REL_ "GenSigTimeoutTime" BU_SG_REL_ HDSG SG_ 1616 RA_Frequency_unit 5000;
BA_REL_ "GenSigTimeoutTime" BU_SG_REL_ SAD SG_ 1616 RA_Frequency_unit 5000;
BA_REL_ "GenSigTimeoutTime" BU_SG_REL_ SAD2 SG_ 1616 RA_Frequency_unit 5000;
BA_REL_ "GenSigTimeoutTime" BU_SG_REL_ SitzMem_BFS SG_ 1616 RA_Frequency_unit 5000;
BA_REL_ "GenSigTimeoutTime" BU_SG_REL_ SitzMem_FS SG_ 1616 RA_Frequency_unit 5000;
BA_REL_ "GenSigTimeoutTime" BU_SG_REL_ SitzMem_HBFS SG_ 1616 RA_Frequency_unit 5000;
BA_REL_ "GenSigTimeoutTime" BU_SG_REL_ SitzMem_HFS SG_ 1616 RA_Frequency_unit 5000;
BA_REL_ "GenSigTimeoutTime" BU_SG_REL_ TSG_BFS SG_ 1616 RA_Frequency_unit 5000;
BA_REL_ "GenSigTimeoutTime" BU_SG_REL_ TSG_FS SG_ 1616 RA_Frequency_unit 5000;
BA_REL_ "GenSigTimeoutTime" BU_SG_REL_ HDSG SG_ 1616 RA_AM_Tuning 5000;
BA_REL_ "GenSigTimeoutTime" BU_SG_REL_ SAD SG_ 1616 RA_AM_Tuning 5000;
BA_REL_ "GenSigTimeoutTime" BU_SG_REL_ SAD2 SG_ 1616 RA_AM_Tuning 5000;
BA_REL_ "GenSigTimeoutTime" BU_SG_REL_ SitzMem_BFS SG_ 1616 RA_AM_Tuning 5000;
BA_REL_ "GenSigTimeoutTime" BU_SG_REL_ SitzMem_FS SG_ 1616 RA_AM_Tuning 5000;
BA_REL_ "GenSigTimeoutTime" BU_SG_REL_ SitzMem_HBFS SG_ 1616 RA_AM_Tuning 5000;
BA_REL_ "GenSigTimeoutTime" BU_SG_REL_ SitzMem_HFS SG_ 1616 RA_AM_Tuning 5000;
BA_REL_ "GenSigTimeoutTime" BU_SG_REL_ TSG_BFS SG_ 1616 RA_AM_Tuning 5000;
BA_REL_ "GenSigTimeoutTime" BU_SG_REL_ TSG_FS SG_ 1616 RA_AM_Tuning 5000;
BA_REL_ "GenSigTimeoutTime" BU_SG_REL_ BCM1 SG_ 695 RCTA_Info_rechts 500;
BA_REL_ "GenSigTimeoutTime" BU_SG_REL_ BCM1 SG_ 695 RCTA_Info_links 500;
BA_REL_ "GenSigTimeoutTime" BU_SG_REL_ BCM1 SG_ 695 RCTA_Status 500;
BA_REL_ "GenSigTimeoutTime" BU_SG_REL_ BCM1 SG_ 695 RCTA_Warnton 500;
BA_REL_ "GenSigTimeoutTime" BU_SG_REL_ VTS SG_ 1529 RDK_Warnungen_02 5000;
BA_REL_ "GenSigTimeoutTime" BU_SG_REL_ BCM1 SG_ 1711 RV_Video_on 5000;
BA_REL_ "GenSigTimeoutTime" BU_SG_REL_ BCM1 SG_ 1711 RV_System_aktiv 5000;
BA_REL_ "GenSigTimeoutTime" BU_SG_REL_ BCM1 SG_ 1711 RV_GL_Trunk_open 5000;
BA_REL_ "GenSigTimeoutTime" BU_SG_REL_ VTS SG_ 1525 RW_Gesamt_Reichweite 5000;
BA_REL_ "GenSigTimeoutTime" BU_SG_REL_ VTS SG_ 1525 RW_Prim_Reichweitenverbrauch 5000;
BA_REL_ "GenSigTimeoutTime" BU_SG_REL_ VTS SG_ 1525 RW_Prim_Reichweitenv_Einheit 5000;
BA_REL_ "GenSigTimeoutTime" BU_SG_REL_ VTS SG_ 1525 RW_Primaer_Reichweite 5000;
BA_REL_ "GenSigTimeoutTime" BU_SG_REL_ VTS SG_ 1527 RW_Reichweite_Einheit_Anzeige 5000;
BA_REL_ "GenSigTimeoutTime" BU_SG_REL_ VTS SG_ 1527 RW_Gesamt_Reichweite_Anzeige 5000;
BA_REL_ "GenSigTimeoutTime" BU_SG_REL_ VTS SG_ 1527 RW_Primaer_Reichweite_Anzeige 5000;
BA_REL_ "GenSigTimeoutTime" BU_SG_REL_ VTS SG_ 1527 RW_Sekundaer_Reichweite_Anzeige 5000;
BA_REL_ "GenSigTimeoutTime" BU_SG_REL_ VTS SG_ 1527 RW_Sekundaer_Reichweite 5000;
BA_REL_ "GenSigTimeoutTime" BU_SG_REL_ VTS SG_ 1527 RW_Sek_Reichweitenv_Einheit 5000;
BA_REL_ "GenSigTimeoutTime" BU_SG_REL_ VTS SG_ 1527 RW_Sek_Reichweitenverbrauch 5000;
BA_REL_ "GenSigTimeoutTime" BU_SG_REL_ MSBBR SG_ 1440 LS_Helligkeit_IR 2000;
BA_REL_ "GenSigTimeoutTime" BU_SG_REL_ Gateway SG_ 1440 LS_Helligkeit_FW 2000;
BA_REL_ "GenSigTimeoutTime" BU_SG_REL_ MSBBR SG_ 1440 LS_Helligkeit_FW 2000;
BA_REL_ "GenSigTimeoutTime" BU_SG_REL_ MSBBR SG_ 1440 LS_defekt 2000;
BA_REL_ "GenSigTimeoutTime" BU_SG_REL_ Gateway SG_ 1440 RS_Regenmenge 2000;
BA_REL_ "GenSigTimeoutTime" BU_SG_REL_ MSBBR SG_ 1440 RS_Regenmenge 2000;
BA_REL_ "GenSigTimeoutTime" BU_SG_REL_ SAD SG_ 1440 RS_Verglasung_schliessen 2000;
BA_REL_ "GenSigTimeoutTime" BU_SG_REL_ SAD2 SG_ 1440 RS_Verglasung_schliessen 2000;
BA_REL_ "GenSigTimeoutTime" BU_SG_REL_ TSG_BFS SG_ 1440 RS_Verglasung_schliessen 2000;
BA_REL_ "GenSigTimeoutTime" BU_SG_REL_ TSG_FS SG_ 1440 RS_Verglasung_schliessen 2000;
BA_REL_ "GenSigTimeoutTime" BU_SG_REL_ MSBBR SG_ 1440 RS_defekt 2000;
BA_REL_ "GenSigTimeoutTime" BU_SG_REL_ SAD SG_ 1440 RS_defekt 2000;
BA_REL_ "GenSigTimeoutTime" BU_SG_REL_ SAD2 SG_ 1440 RS_defekt 2000;
BA_REL_ "GenSigTimeoutTime" BU_SG_REL_ TSG_BFS SG_ 1440 RS_defekt 2000;
BA_REL_ "GenSigTimeoutTime" BU_SG_REL_ TSG_FS SG_ 1440 RS_defekt 2000;
BA_REL_ "GenSigTimeoutTime" BU_SG_REL_ MSBBR SG_ 1440 RS_Wischergeschwindigkeit 2000;
BA_REL_ "GenSigTimeoutTime" BU_SG_REL_ MSBBR SG_ 1440 RLS_Vorfeldhelligkeit_Boost 2000;
BA_REL_ "GenSigTimeoutTime" BU_SG_REL_ SAD SG_ 1517 SAD2_Deckel_Lage 5000;
BA_REL_ "GenSigTimeoutTime" BU_SG_REL_ BCM2 SG_ 1517 SAD2_Deckel_normiert 5000;
BA_REL_ "GenSigTimeoutTime" BU_SG_REL_ SAD SG_ 1517 SAD2_Deckel_normiert 5000;
BA_REL_ "GenSigTimeoutTime" BU_SG_REL_ BCM2 SG_ 1517 SAD2_Deckel_Thermoschutz 5000;
BA_REL_ "GenSigTimeoutTime" BU_SG_REL_ SAD SG_ 1517 SAD2_Deckel_Thermoschutz 5000;
BA_REL_ "GenSigTimeoutTime" BU_SG_REL_ BCM2 SG_ 1517 SAD2_Deckel_UEKB_aktiv 5000;
BA_REL_ "GenSigTimeoutTime" BU_SG_REL_ SAD SG_ 1517 SAD2_Deckel_UEKB_aktiv 5000;
BA_REL_ "GenSigTimeoutTime" BU_SG_REL_ BCM2 SG_ 1517 SAD2_Deckel_Position 5000;
BA_REL_ "GenSigTimeoutTime" BU_SG_REL_ SAD SG_ 1517 SAD2_Deckel_Position 5000;
BA_REL_ "GenSigTimeoutTime" BU_SG_REL_ SAD SG_ 1517 SAD2_Rollo_Lage 5000;
BA_REL_ "GenSigTimeoutTime" BU_SG_REL_ SAD SG_ 1517 SAD2_Rollo_Position 5000;
BA_REL_ "GenSigTimeoutTime" BU_SG_REL_ BCM2 SG_ 1517 SAD2_Rollo_normiert 5000;
BA_REL_ "GenSigTimeoutTime" BU_SG_REL_ SAD SG_ 1517 SAD2_Rollo_normiert 5000;
BA_REL_ "GenSigTimeoutTime" BU_SG_REL_ BCM2 SG_ 1517 SAD2_Rollo_Thermoschutz 5000;
BA_REL_ "GenSigTimeoutTime" BU_SG_REL_ SAD SG_ 1517 SAD2_Rollo_Thermoschutz 5000;
BA_REL_ "GenSigTimeoutTime" BU_SG_REL_ BCM2 SG_ 1517 SAD2_Rollo_UEKB_aktiv 5000;
BA_REL_ "GenSigTimeoutTime" BU_SG_REL_ SAD SG_ 1517 SAD2_Rollo_UEKB_aktiv 5000;
BA_REL_ "GenSigTimeoutTime" BU_SG_REL_ BCM2 SG_ 1504 MD1_Position 5000;
BA_REL_ "GenSigTimeoutTime" BU_SG_REL_ Gateway SG_ 1504 MD1_Position 5000;
BA_REL_ "GenSigTimeoutTime" BU_SG_REL_ SAD2 SG_ 1504 MD1_Position 5000;
BA_REL_ "GenSigTimeoutTime" BU_SG_REL_ SpoilerSG SG_ 1504 MD1_Position 5000;
BA_REL_ "GenSigTimeoutTime" BU_SG_REL_ VTS SG_ 1504 MD1_Position 5000;
BA_REL_ "GenSigTimeoutTime" BU_SG_REL_ BCM1 SG_ 1504 MD1_Lage 5000;
BA_REL_ "GenSigTimeoutTime" BU_SG_REL_ Gateway SG_ 1504 MD1_Lage 5000;
BA_REL_ "GenSigTimeoutTime" BU_SG_REL_ SAD2 SG_ 1504 MD1_Lage 5000;
BA_REL_ "GenSigTimeoutTime" BU_SG_REL_ SpoilerSG SG_ 1504 MD1_Lage 5000;
BA_REL_ "GenSigTimeoutTime" BU_SG_REL_ VTS SG_ 1504 MD1_Lage 5000;
BA_REL_ "GenSigTimeoutTime" BU_SG_REL_ BCM2 SG_ 1504 MD3_Position 5000;
BA_REL_ "GenSigTimeoutTime" BU_SG_REL_ Gateway SG_ 1504 MD3_Position 5000;
BA_REL_ "GenSigTimeoutTime" BU_SG_REL_ SAD2 SG_ 1504 MD3_Position 5000;
BA_REL_ "GenSigTimeoutTime" BU_SG_REL_ SpoilerSG SG_ 1504 MD3_Position 5000;
BA_REL_ "GenSigTimeoutTime" BU_SG_REL_ VTS SG_ 1504 MD3_Position 5000;
BA_REL_ "GenSigTimeoutTime" BU_SG_REL_ Gateway SG_ 1504 MD3_Lage 5000;
BA_REL_ "GenSigTimeoutTime" BU_SG_REL_ SAD2 SG_ 1504 MD3_Lage 5000;
BA_REL_ "GenSigTimeoutTime" BU_SG_REL_ SpoilerSG SG_ 1504 MD3_Lage 5000;
BA_REL_ "GenSigTimeoutTime" BU_SG_REL_ VTS SG_ 1504 MD3_Lage 5000;
BA_REL_ "GenSigTimeoutTime" BU_SG_REL_ SAD2 SG_ 1504 MRollo_Position 5000;
BA_REL_ "GenSigTimeoutTime" BU_SG_REL_ VTS SG_ 1504 MRollo_Position 5000;
BA_REL_ "GenSigTimeoutTime" BU_SG_REL_ SAD2 SG_ 1504 MRollo_Lage 5000;
BA_REL_ "GenSigTimeoutTime" BU_SG_REL_ VTS SG_ 1504 MRollo_Lage 5000;
BA_REL_ "GenSigTimeoutTime" BU_SG_REL_ BCM2 SG_ 1504 SAD_normiert 5000;
BA_REL_ "GenSigTimeoutTime" BU_SG_REL_ SAD2 SG_ 1504 SAD_normiert 5000;
BA_REL_ "GenSigTimeoutTime" BU_SG_REL_ VTS SG_ 1504 SAD_normiert 5000;
BA_REL_ "GenSigTimeoutTime" BU_SG_REL_ BCM2 SG_ 1504 SAD_Thermoschutz 5000;
BA_REL_ "GenSigTimeoutTime" BU_SG_REL_ SAD2 SG_ 1504 SAD_Thermoschutz 5000;
BA_REL_ "GenSigTimeoutTime" BU_SG_REL_ BCM2 SG_ 1504 SAD_UEKB_aktiv 5000;
BA_REL_ "GenSigTimeoutTime" BU_SG_REL_ SAD2 SG_ 1504 SAD_UEKB_aktiv 5000;
BA_REL_ "GenSigTimeoutTime" BU_SG_REL_ BCM2 SG_ 1504 Rollo_normiert 5000;
BA_REL_ "GenSigTimeoutTime" BU_SG_REL_ SAD2 SG_ 1504 Rollo_normiert 5000;
BA_REL_ "GenSigTimeoutTime" BU_SG_REL_ VTS SG_ 1504 Rollo_normiert 5000;
BA_REL_ "GenSigTimeoutTime" BU_SG_REL_ BCM2 SG_ 1504 Rollo_Thermoschutz 5000;
BA_REL_ "GenSigTimeoutTime" BU_SG_REL_ SAD2 SG_ 1504 Rollo_Thermoschutz 5000;
BA_REL_ "GenSigTimeoutTime" BU_SG_REL_ BCM2 SG_ 1504 Rollo_UEKB_aktiv 5000;
BA_REL_ "GenSigTimeoutTime" BU_SG_REL_ SAD2 SG_ 1504 Rollo_UEKB_aktiv 5000;
BA_REL_ "GenSigTimeoutTime" BU_SG_REL_ SAD2 SG_ 1504 SAD_Taster_Deckel_hi 5000;
BA_REL_ "GenSigTimeoutTime" BU_SG_REL_ SAD2 SG_ 1504 SAD_Taster_Deckel_vo 5000;
BA_REL_ "GenSigTimeoutTime" BU_SG_REL_ SAD2 SG_ 1504 SAD_Taster_Rollo_hi 5000;
BA_REL_ "GenSigTimeoutTime" BU_SG_REL_ SAD2 SG_ 1504 SAD_Taster_Rollo_vo 5000;
BA_REL_ "GenSigTimeoutTime" BU_SG_REL_ BCM1 SG_ 424 SARA_11_CRC 500;
BA_REL_ "GenSigTimeoutTime" BU_SG_REL_ BCM1 SG_ 424 SARA_11_BZ 500;
BA_REL_ "GenSigTimeoutTime" BU_SG_REL_ BCM1 SG_ 424 SARA_Accel_X_r 500;
BA_REL_ "GenSigTimeoutTime" BU_SG_REL_ HDSG SG_ 424 SARA_Accel_X_r 500;
BA_REL_ "GenSigTimeoutTime" BU_SG_REL_ MFG SG_ 424 SARA_Accel_X_r 500;
BA_REL_ "GenSigTimeoutTime" BU_SG_REL_ MSBBR SG_ 424 SARA_Accel_X_r 500;
BA_REL_ "GenSigTimeoutTime" BU_SG_REL_ SitzMem_BFS SG_ 424 SARA_Accel_X_r 500;
BA_REL_ "GenSigTimeoutTime" BU_SG_REL_ SitzMem_FS SG_ 424 SARA_Accel_X_r 500;
BA_REL_ "GenSigTimeoutTime" BU_SG_REL_ SitzMem_HBFS SG_ 424 SARA_Accel_X_r 500;
BA_REL_ "GenSigTimeoutTime" BU_SG_REL_ SitzMem_HFS SG_ 424 SARA_Accel_X_r 500;
BA_REL_ "GenSigTimeoutTime" BU_SG_REL_ BCM1 SG_ 424 SARA_Accel_Y_r 500;
BA_REL_ "GenSigTimeoutTime" BU_SG_REL_ HDSG SG_ 424 SARA_Accel_Y_r 500;
BA_REL_ "GenSigTimeoutTime" BU_SG_REL_ SitzMem_BFS SG_ 424 SARA_Accel_Y_r 500;
BA_REL_ "GenSigTimeoutTime" BU_SG_REL_ SitzMem_FS SG_ 424 SARA_Accel_Y_r 500;
BA_REL_ "GenSigTimeoutTime" BU_SG_REL_ SitzMem_HBFS SG_ 424 SARA_Accel_Y_r 500;
BA_REL_ "GenSigTimeoutTime" BU_SG_REL_ SitzMem_HFS SG_ 424 SARA_Accel_Y_r 500;
BA_REL_ "GenSigTimeoutTime" BU_SG_REL_ BCM1 SG_ 424 SARA_Omega_Z_r 500;
BA_REL_ "GenSigTimeoutTime" BU_SG_REL_ BCM1 SG_ 424 SARA_CF_Accel_X_r 500;
BA_REL_ "GenSigTimeoutTime" BU_SG_REL_ HDSG SG_ 424 SARA_CF_Accel_X_r 500;
BA_REL_ "GenSigTimeoutTime" BU_SG_REL_ MFG SG_ 424 SARA_CF_Accel_X_r 500;
BA_REL_ "GenSigTimeoutTime" BU_SG_REL_ MSBBR SG_ 424 SARA_CF_Accel_X_r 500;
BA_REL_ "GenSigTimeoutTime" BU_SG_REL_ BCM1 SG_ 424 SARA_CF_Accel_Y_r 500;
BA_REL_ "GenSigTimeoutTime" BU_SG_REL_ HDSG SG_ 424 SARA_CF_Accel_Y_r 500;
BA_REL_ "GenSigTimeoutTime" BU_SG_REL_ BCM1 SG_ 424 SARA_CF_Omega_Z_r 500;
BA_REL_ "GenSigTimeoutTime" BU_SG_REL_ BCM1 SG_ 1522 KBI_Phototransistor 2000;
BA_REL_ "GenSigTimeoutTime" BU_SG_REL_ BCM1 SG_ 1522 KBI_Dimmpoti 2000;
BA_REL_ "GenSigTimeoutTime" BU_SG_REL_ BCM1 SG_ 980 SMLS_01_CRC 2000;
BA_REL_ "GenSigTimeoutTime" BU_SG_REL_ BCM2 SG_ 980 SMLS_01_CRC 2000;
BA_REL_ "GenSigTimeoutTime" BU_SG_REL_ BCM1 SG_ 980 SMLS_01_BZ 2000;
BA_REL_ "GenSigTimeoutTime" BU_SG_REL_ BCM2 SG_ 980 SMLS_01_BZ 2000;
BA_REL_ "GenSigTimeoutTime" BU_SG_REL_ BCM1 SG_ 980 BH_Blinker_li 2000;
BA_REL_ "GenSigTimeoutTime" BU_SG_REL_ BCM2 SG_ 980 BH_Blinker_li 2000;
BA_REL_ "GenSigTimeoutTime" BU_SG_REL_ BCM1 SG_ 980 BH_Blinker_re 2000;
BA_REL_ "GenSigTimeoutTime" BU_SG_REL_ BCM2 SG_ 980 BH_Blinker_re 2000;
BA_REL_ "GenSigTimeoutTime" BU_SG_REL_ BCM1 SG_ 980 BH_Lichthupe 2000;
BA_REL_ "GenSigTimeoutTime" BU_SG_REL_ BCM1 SG_ 980 BH_Fernlicht 2000;
BA_REL_ "GenSigTimeoutTime" BU_SG_REL_ BCM1 SG_ 980 WH_Tipwischen 2000;
BA_REL_ "GenSigTimeoutTime" BU_SG_REL_ BCM1 SG_ 980 WH_Intervall 2000;
BA_REL_ "GenSigTimeoutTime" BU_SG_REL_ BCM1 SG_ 980 WH_WischerStufe1 2000;
BA_REL_ "GenSigTimeoutTime" BU_SG_REL_ BCM1 SG_ 980 WH_WischerStufe2 2000;
BA_REL_ "GenSigTimeoutTime" BU_SG_REL_ BCM1 SG_ 980 WH_Frontwaschen 2000;
BA_REL_ "GenSigTimeoutTime" BU_SG_REL_ BCM1 SG_ 980 WH_Heckintervall 2000;
BA_REL_ "GenSigTimeoutTime" BU_SG_REL_ BCM1 SG_ 980 WH_Heckwaschen 2000;
BA_REL_ "GenSigTimeoutTime" BU_SG_REL_ BCM1 SG_ 980 WH_Intervallstufen 2000;
BA_REL_ "GenSigTimeoutTime" BU_SG_REL_ BCM1 SG_ 980 SMLS_Hupe 2000;
BA_REL_ "GenSigTimeoutTime" BU_SG_REL_ MFG SG_ 980 SMLS_Hupe 2000;
BA_REL_ "GenSigTimeoutTime" BU_SG_REL_ BCM1 SG_ 980 WH_SRA 2000;
BA_REL_ "GenSigTimeoutTime" BU_SG_REL_ BCM1 SG_ 980 WH_Wischer_Fehler 2000;
BA_REL_ "GenSigTimeoutTime" BU_SG_REL_ BCM2 SG_ 980 BH_Blinker_Fehler 2000;
BA_REL_ "GenSigTimeoutTime" BU_SG_REL_ Gateway SG_ 1710 SP_FT_oben 5000;
BA_REL_ "GenSigTimeoutTime" BU_SG_REL_ MFG SG_ 1710 SP_FT_oben 5000;
BA_REL_ "GenSigTimeoutTime" BU_SG_REL_ TSG_BFS SG_ 1710 SP_FT_oben 5000;
BA_REL_ "GenSigTimeoutTime" BU_SG_REL_ Gateway SG_ 1710 SP_FT_unten 5000;
BA_REL_ "GenSigTimeoutTime" BU_SG_REL_ MFG SG_ 1710 SP_FT_unten 5000;
BA_REL_ "GenSigTimeoutTime" BU_SG_REL_ TSG_BFS SG_ 1710 SP_FT_unten 5000;
BA_REL_ "GenSigTimeoutTime" BU_SG_REL_ Gateway SG_ 1710 SP_FT_links 5000;
BA_REL_ "GenSigTimeoutTime" BU_SG_REL_ MFG SG_ 1710 SP_FT_links 5000;
BA_REL_ "GenSigTimeoutTime" BU_SG_REL_ TSG_BFS SG_ 1710 SP_FT_links 5000;
BA_REL_ "GenSigTimeoutTime" BU_SG_REL_ Gateway SG_ 1710 SP_FT_rechts 5000;
BA_REL_ "GenSigTimeoutTime" BU_SG_REL_ MFG SG_ 1710 SP_FT_rechts 5000;
BA_REL_ "GenSigTimeoutTime" BU_SG_REL_ TSG_BFS SG_ 1710 SP_FT_rechts 5000;
BA_REL_ "GenSigTimeoutTime" BU_SG_REL_ Gateway SG_ 1710 SP_BT_oben 5000;
BA_REL_ "GenSigTimeoutTime" BU_SG_REL_ MFG SG_ 1710 SP_BT_oben 5000;
BA_REL_ "GenSigTimeoutTime" BU_SG_REL_ TSG_BFS SG_ 1710 SP_BT_oben 5000;
BA_REL_ "GenSigTimeoutTime" BU_SG_REL_ Gateway SG_ 1710 SP_BT_unten 5000;
BA_REL_ "GenSigTimeoutTime" BU_SG_REL_ MFG SG_ 1710 SP_BT_unten 5000;
BA_REL_ "GenSigTimeoutTime" BU_SG_REL_ TSG_BFS SG_ 1710 SP_BT_unten 5000;
BA_REL_ "GenSigTimeoutTime" BU_SG_REL_ Gateway SG_ 1710 SP_BT_links 5000;
BA_REL_ "GenSigTimeoutTime" BU_SG_REL_ MFG SG_ 1710 SP_BT_links 5000;
BA_REL_ "GenSigTimeoutTime" BU_SG_REL_ TSG_BFS SG_ 1710 SP_BT_links 5000;
BA_REL_ "GenSigTimeoutTime" BU_SG_REL_ Gateway SG_ 1710 SP_BT_rechts 5000;
BA_REL_ "GenSigTimeoutTime" BU_SG_REL_ MFG SG_ 1710 SP_BT_rechts 5000;
BA_REL_ "GenSigTimeoutTime" BU_SG_REL_ TSG_BFS SG_ 1710 SP_BT_rechts 5000;
BA_REL_ "GenSigTimeoutTime" BU_SG_REL_ MFG SG_ 1710 SP_abklappen 5000;
BA_REL_ "GenSigTimeoutTime" BU_SG_REL_ TSG_BFS SG_ 1710 SP_abklappen 5000;
BA_REL_ "GenSigTimeoutTime" BU_SG_REL_ MFG SG_ 1710 SP_anklappen 5000;
BA_REL_ "GenSigTimeoutTime" BU_SG_REL_ TSG_BFS SG_ 1710 SP_anklappen 5000;
BA_REL_ "GenSigTimeoutTime" BU_SG_REL_ MFG SG_ 1710 SP_normieren 5000;
BA_REL_ "GenSigTimeoutTime" BU_SG_REL_ TSG_BFS SG_ 1710 SP_normieren 5000;
BA_REL_ "GenSigTimeoutTime" BU_SG_REL_ Gateway SG_ 1710 SP_Hzg_Taster 5000;
BA_REL_ "GenSigTimeoutTime" BU_SG_REL_ MFG SG_ 1710 SP_Hzg_Taster 5000;
BA_REL_ "GenSigTimeoutTime" BU_SG_REL_ TSG_BFS SG_ 1710 SP_Hzg_Taster 5000;
BA_REL_ "GenSigTimeoutTime" BU_SG_REL_ TSG_BFS SG_ 1710 SP_S_oben 5000;
BA_REL_ "GenSigTimeoutTime" BU_SG_REL_ TSG_BFS SG_ 1710 SP_S_unten 5000;
BA_REL_ "GenSigTimeoutTime" BU_SG_REL_ TSG_BFS SG_ 1710 SP_S_links 5000;
BA_REL_ "GenSigTimeoutTime" BU_SG_REL_ TSG_BFS SG_ 1710 SP_S_rechts 5000;
BA_REL_ "GenSigTimeoutTime" BU_SG_REL_ MFG SG_ 1710 SP_Auswahl_li 5000;
BA_REL_ "GenSigTimeoutTime" BU_SG_REL_ TSG_BFS SG_ 1710 SP_Auswahl_li 5000;
BA_REL_ "GenSigTimeoutTime" BU_SG_REL_ MFG SG_ 1710 SP_Auswahl_re 5000;
BA_REL_ "GenSigTimeoutTime" BU_SG_REL_ TSG_BFS SG_ 1710 SP_Auswahl_re 5000;
BA_REL_ "GenSigTimeoutTime" BU_SG_REL_ MFG SG_ 1710 SP_S_Klappen 5000;
BA_REL_ "GenSigTimeoutTime" BU_SG_REL_ TSG_BFS SG_ 1710 SP_S_Klappen 5000;
BA_REL_ "GenSigTimeoutTime" BU_SG_REL_ BCM1 SG_ 1710 SP_Verstellschalter_Fehler 5000;
BA_REL_ "GenSigTimeoutTime" BU_SG_REL_ BCM2 SG_ 904 SpoilerSG_HSpoiler_IstPos 1000;
BA_REL_ "GenSigTimeoutTime" BU_SG_REL_ VTS SG_ 1313 STH_LED 5000;
BA_REL_ "GenSigTimeoutTime" BU_SG_REL_ VTS SG_ 1313 STH_Fehlerstatus 5000;
BA_REL_ "GenSigTimeoutTime" BU_SG_REL_ VTS SG_ 1650 STH_ZZ_Monat 5000;
BA_REL_ "GenSigTimeoutTime" BU_SG_REL_ VTS SG_ 1650 STH_ZZ_Tag 5000;
BA_REL_ "GenSigTimeoutTime" BU_SG_REL_ VTS SG_ 1650 STH_ZZ_Betriebsmodus 5000;
BA_REL_ "GenSigTimeoutTime" BU_SG_REL_ VTS SG_ 1650 STH_ZZ_Minute 5000;
BA_REL_ "GenSigTimeoutTime" BU_SG_REL_ VTS SG_ 1650 STH_ZZ_Status_Timer 5000;
BA_REL_ "GenSigTimeoutTime" BU_SG_REL_ VTS SG_ 1650 STH_ZZ_Stunde 5000;
BA_REL_ "GenSigTimeoutTime" BU_SG_REL_ VTS SG_ 1650 STH_ZZ_Betriebsdauer 5000;
BA_REL_ "GenSigTimeoutTime" BU_SG_REL_ BCM2 SG_ 1172 STS_01_CRC 2000;
BA_REL_ "GenSigTimeoutTime" BU_SG_REL_ BCM2 SG_ 1172 STS_01_BZ 2000;
BA_REL_ "GenSigTimeoutTime" BU_SG_REL_ BCM2 SG_ 1172 STS_Anlassersperre 2000;
BA_REL_ "GenSigTimeoutTime" BU_SG_REL_ BCM1 SG_ 1172 STS_Standlicht 2000;
BA_REL_ "GenSigTimeoutTime" BU_SG_REL_ BCM1 SG_ 1172 STS_Fahrlicht 2000;
BA_REL_ "GenSigTimeoutTime" BU_SG_REL_ BCM2 SG_ 1172 STS_Alarm_Blinker 2000;
BA_REL_ "GenSigTimeoutTime" BU_SG_REL_ BCM1 SG_ 1172 STS_Signalhorn 2000;
BA_REL_ "GenSigTimeoutTime" BU_SG_REL_ BCM1 SG_ 783 SWA_FT_RueckLED 2000;
BA_REL_ "GenSigTimeoutTime" BU_SG_REL_ TSG_FS SG_ 783 SWA_FT_RueckLED 2000;
BA_REL_ "GenSigTimeoutTime" BU_SG_REL_ TSG_BFS SG_ 783 ASW_Status 2000;
BA_REL_ "GenSigTimeoutTime" BU_SG_REL_ TSG_FS SG_ 783 ASW_Status 2000;
BA_REL_ "GenSigTimeoutTime" BU_SG_REL_ TSG_BFS SG_ 783 ASW_Warnung_FS 2000;
BA_REL_ "GenSigTimeoutTime" BU_SG_REL_ TSG_FS SG_ 783 ASW_Warnung_FS 2000;
BA_REL_ "GenSigTimeoutTime" BU_SG_REL_ TSG_BFS SG_ 783 ASW_Warnung_BFS 2000;
BA_REL_ "GenSigTimeoutTime" BU_SG_REL_ TSG_FS SG_ 783 ASW_Warnung_BFS 2000;
BA_REL_ "GenSigTimeoutTime" BU_SG_REL_ MSBBR SG_ 783 SWA_Gischtzaehler 2000;
BA_REL_ "GenSigTimeoutTime" BU_SG_REL_ TSG_BFS SG_ 673 SWA_LED_Hell_BFS 2000;
BA_REL_ "GenSigTimeoutTime" BU_SG_REL_ TSG_FS SG_ 673 SWA_LED_Hell_FS 2000;
BA_REL_ "GenSigTimeoutTime" BU_SG_REL_ TSG_BFS SG_ 673 SWA_LED_Modus_BFS 2000;
BA_REL_ "GenSigTimeoutTime" BU_SG_REL_ TSG_FS SG_ 673 SWA_LED_Modus_FS 2000;
BA_REL_ "GenSigTimeoutTime" BU_SG_REL_ MSBBR SG_ 788 SWA_Obj_03_PositionX 500;
BA_REL_ "GenSigTimeoutTime" BU_SG_REL_ MSBBR SG_ 788 SWA_Obj_04_PositionX 500;
BA_REL_ "GenSigTimeoutTime" BU_SG_REL_ BCM2 SG_ 1413 SI_Sammel_SG_Fehler 5000;
BA_REL_ "GenSigTimeoutTime" BU_SG_REL_ BCM2 SG_ 1413 SI_Diagnose_Aktiv 5000;
BA_REL_ "GenSigTimeoutTime" BU_SG_REL_ AAG SG_ 1413 SI_QRS_Mode 5000;
BA_REL_ "GenSigTimeoutTime" BU_SG_REL_ BCM1 SG_ 1413 SI_QRS_Mode 5000;
BA_REL_ "GenSigTimeoutTime" BU_SG_REL_ BCM2 SG_ 1413 SI_QRS_Mode 5000;
BA_REL_ "GenSigTimeoutTime" BU_SG_REL_ HDSG SG_ 1413 SI_QRS_Mode 5000;
BA_REL_ "GenSigTimeoutTime" BU_SG_REL_ IEZS SG_ 1413 SI_QRS_Mode 5000;
BA_REL_ "GenSigTimeoutTime" BU_SG_REL_ SAD SG_ 1413 SI_QRS_Mode 5000;
BA_REL_ "GenSigTimeoutTime" BU_SG_REL_ SAD2 SG_ 1413 SI_QRS_Mode 5000;
BA_REL_ "GenSigTimeoutTime" BU_SG_REL_ SitzMem_BFS SG_ 1413 SI_QRS_Mode 5000;
BA_REL_ "GenSigTimeoutTime" BU_SG_REL_ SitzMem_FS SG_ 1413 SI_QRS_Mode 5000;
BA_REL_ "GenSigTimeoutTime" BU_SG_REL_ SitzMem_HBFS SG_ 1413 SI_QRS_Mode 5000;
BA_REL_ "GenSigTimeoutTime" BU_SG_REL_ SitzMem_HFS SG_ 1413 SI_QRS_Mode 5000;
BA_REL_ "GenSigTimeoutTime" BU_SG_REL_ SitzMem_SR3 SG_ 1413 SI_QRS_Mode 5000;
BA_REL_ "GenSigTimeoutTime" BU_SG_REL_ TSG_BFS SG_ 1413 SI_QRS_Mode 5000;
BA_REL_ "GenSigTimeoutTime" BU_SG_REL_ TSG_FS SG_ 1413 SI_QRS_Mode 5000;
BA_REL_ "GenSigTimeoutTime" BU_SG_REL_ BCM1 SG_ 1413 SI_T_Mode 5000;
BA_REL_ "GenSigTimeoutTime" BU_SG_REL_ BCM2 SG_ 1413 SI_T_Mode 5000;
BA_REL_ "GenSigTimeoutTime" BU_SG_REL_ HDSG SG_ 1413 SI_T_Mode 5000;
BA_REL_ "GenSigTimeoutTime" BU_SG_REL_ IEZS SG_ 1413 SI_T_Mode 5000;
BA_REL_ "GenSigTimeoutTime" BU_SG_REL_ SAD SG_ 1413 SI_T_Mode 5000;
BA_REL_ "GenSigTimeoutTime" BU_SG_REL_ SAD2 SG_ 1413 SI_T_Mode 5000;
BA_REL_ "GenSigTimeoutTime" BU_SG_REL_ SitzMem_BFS SG_ 1413 SI_T_Mode 5000;
BA_REL_ "GenSigTimeoutTime" BU_SG_REL_ SitzMem_FS SG_ 1413 SI_T_Mode 5000;
BA_REL_ "GenSigTimeoutTime" BU_SG_REL_ SitzMem_HBFS SG_ 1413 SI_T_Mode 5000;
BA_REL_ "GenSigTimeoutTime" BU_SG_REL_ SitzMem_HFS SG_ 1413 SI_T_Mode 5000;
BA_REL_ "GenSigTimeoutTime" BU_SG_REL_ SitzMem_SR3 SG_ 1413 SI_T_Mode 5000;
BA_REL_ "GenSigTimeoutTime" BU_SG_REL_ SpoilerSG SG_ 1413 SI_T_Mode 5000;
BA_REL_ "GenSigTimeoutTime" BU_SG_REL_ TSG_BFS SG_ 1413 SI_T_Mode 5000;
BA_REL_ "GenSigTimeoutTime" BU_SG_REL_ TSG_FS SG_ 1413 SI_T_Mode 5000;
BA_REL_ "GenSigTimeoutTime" BU_SG_REL_ AAG SG_ 1413 SI_NWDF 5000;
BA_REL_ "GenSigTimeoutTime" BU_SG_REL_ BCM1 SG_ 1413 SI_NWDF 5000;
BA_REL_ "GenSigTimeoutTime" BU_SG_REL_ BCM2 SG_ 1413 SI_NWDF 5000;
BA_REL_ "GenSigTimeoutTime" BU_SG_REL_ ELV SG_ 1413 SI_NWDF 5000;
BA_REL_ "GenSigTimeoutTime" BU_SG_REL_ HDSG SG_ 1413 SI_NWDF 5000;
BA_REL_ "GenSigTimeoutTime" BU_SG_REL_ IEZS SG_ 1413 SI_NWDF 5000;
BA_REL_ "GenSigTimeoutTime" BU_SG_REL_ MFG SG_ 1413 SI_NWDF 5000;
BA_REL_ "GenSigTimeoutTime" BU_SG_REL_ SAD SG_ 1413 SI_NWDF 5000;
BA_REL_ "GenSigTimeoutTime" BU_SG_REL_ SAD2 SG_ 1413 SI_NWDF 5000;
BA_REL_ "GenSigTimeoutTime" BU_SG_REL_ SitzMem_BFS SG_ 1413 SI_NWDF 5000;
BA_REL_ "GenSigTimeoutTime" BU_SG_REL_ SitzMem_FS SG_ 1413 SI_NWDF 5000;
BA_REL_ "GenSigTimeoutTime" BU_SG_REL_ SitzMem_HBFS SG_ 1413 SI_NWDF 5000;
BA_REL_ "GenSigTimeoutTime" BU_SG_REL_ SitzMem_HFS SG_ 1413 SI_NWDF 5000;
BA_REL_ "GenSigTimeoutTime" BU_SG_REL_ SitzMem_SR3 SG_ 1413 SI_NWDF 5000;
BA_REL_ "GenSigTimeoutTime" BU_SG_REL_ TSG_BFS SG_ 1413 SI_NWDF 5000;
BA_REL_ "GenSigTimeoutTime" BU_SG_REL_ TSG_FS SG_ 1413 SI_NWDF 5000;
BA_REL_ "GenSigTimeoutTime" BU_SG_REL_ VSG SG_ 1413 SI_NWDF 5000;
BA_REL_ "GenSigTimeoutTime" BU_SG_REL_ VTS SG_ 1413 SI_NWDF 5000;
BA_REL_ "GenSigTimeoutTime" BU_SG_REL_ AAG SG_ 1413 SI_NWDF_gueltig 5000;
BA_REL_ "GenSigTimeoutTime" BU_SG_REL_ BCM1 SG_ 1413 SI_NWDF_gueltig 5000;
BA_REL_ "GenSigTimeoutTime" BU_SG_REL_ BCM2 SG_ 1413 SI_NWDF_gueltig 5000;
BA_REL_ "GenSigTimeoutTime" BU_SG_REL_ ELV SG_ 1413 SI_NWDF_gueltig 5000;
BA_REL_ "GenSigTimeoutTime" BU_SG_REL_ HDSG SG_ 1413 SI_NWDF_gueltig 5000;
BA_REL_ "GenSigTimeoutTime" BU_SG_REL_ IEZS SG_ 1413 SI_NWDF_gueltig 5000;
BA_REL_ "GenSigTimeoutTime" BU_SG_REL_ MFG SG_ 1413 SI_NWDF_gueltig 5000;
BA_REL_ "GenSigTimeoutTime" BU_SG_REL_ SAD SG_ 1413 SI_NWDF_gueltig 5000;
BA_REL_ "GenSigTimeoutTime" BU_SG_REL_ SAD2 SG_ 1413 SI_NWDF_gueltig 5000;
BA_REL_ "GenSigTimeoutTime" BU_SG_REL_ SitzMem_BFS SG_ 1413 SI_NWDF_gueltig 5000;
BA_REL_ "GenSigTimeoutTime" BU_SG_REL_ SitzMem_FS SG_ 1413 SI_NWDF_gueltig 5000;
BA_REL_ "GenSigTimeoutTime" BU_SG_REL_ SitzMem_HBFS SG_ 1413 SI_NWDF_gueltig 5000;
BA_REL_ "GenSigTimeoutTime" BU_SG_REL_ SitzMem_HFS SG_ 1413 SI_NWDF_gueltig 5000;
BA_REL_ "GenSigTimeoutTime" BU_SG_REL_ SitzMem_SR3 SG_ 1413 SI_NWDF_gueltig 5000;
BA_REL_ "GenSigTimeoutTime" BU_SG_REL_ TSG_BFS SG_ 1413 SI_NWDF_gueltig 5000;
BA_REL_ "GenSigTimeoutTime" BU_SG_REL_ TSG_FS SG_ 1413 SI_NWDF_gueltig 5000;
BA_REL_ "GenSigTimeoutTime" BU_SG_REL_ VSG SG_ 1413 SI_NWDF_gueltig 5000;
BA_REL_ "GenSigTimeoutTime" BU_SG_REL_ VTS SG_ 1413 SI_NWDF_gueltig 5000;
BA_REL_ "GenSigTimeoutTime" BU_SG_REL_ BCM1 SG_ 1413 SI_T_Schutz 5000;
BA_REL_ "GenSigTimeoutTime" BU_SG_REL_ BCM2 SG_ 1413 SI_T_Schutz 5000;
BA_REL_ "GenSigTimeoutTime" BU_SG_REL_ SAD SG_ 1413 SI_T_Schutz 5000;
BA_REL_ "GenSigTimeoutTime" BU_SG_REL_ SAD2 SG_ 1413 SI_T_Schutz 5000;
BA_REL_ "GenSigTimeoutTime" BU_SG_REL_ TSG_BFS SG_ 1413 SI_T_Schutz 5000;
BA_REL_ "GenSigTimeoutTime" BU_SG_REL_ TSG_FS SG_ 1413 SI_T_Schutz 5000;
BA_REL_ "GenSigTimeoutTime" BU_SG_REL_ BCM2 SG_ 1413 SI_BUS_01 5000;
BA_REL_ "GenSigTimeoutTime" BU_SG_REL_ VTS SG_ 1413 SI_BUS_02 5000;
BA_REL_ "GenSigTimeoutTime" BU_SG_REL_ BCM2 SG_ 1413 SI_BUS_04 5000;
BA_REL_ "GenSigTimeoutTime" BU_SG_REL_ HDSG SG_ 1413 SI_BUS_04 5000;
BA_REL_ "GenSigTimeoutTime" BU_SG_REL_ BCM2 SG_ 1413 SI_BUS_06 5000;
BA_REL_ "GenSigTimeoutTime" BU_SG_REL_ AAG SG_ 1413 SI_BUS_10 5000;
BA_REL_ "GenSigTimeoutTime" BU_SG_REL_ BCM2 SG_ 1413 SI_BUS_10 5000;
BA_REL_ "GenSigTimeoutTime" BU_SG_REL_ HDSG SG_ 1413 SI_BUS_10 5000;
BA_REL_ "GenSigTimeoutTime" BU_SG_REL_ BCM2 SG_ 977 BT_Tuer_geoeffnet 1000;
BA_REL_ "GenSigTimeoutTime" BU_SG_REL_ Gateway SG_ 977 BT_Tuer_geoeffnet 1000;
BA_REL_ "GenSigTimeoutTime" BU_SG_REL_ IEZS SG_ 977 BT_Tuer_geoeffnet 1000;
BA_REL_ "GenSigTimeoutTime" BU_SG_REL_ MFG SG_ 977 BT_Tuer_geoeffnet 1000;
BA_REL_ "GenSigTimeoutTime" BU_SG_REL_ SitzMem_BFS SG_ 977 BT_Tuer_geoeffnet 1000;
BA_REL_ "GenSigTimeoutTime" BU_SG_REL_ VTS SG_ 977 BT_Tuer_geoeffnet 1000;
BA_REL_ "GenSigTimeoutTime" BU_SG_REL_ BCM2 SG_ 977 BT_verriegelt 1000;
BA_REL_ "GenSigTimeoutTime" BU_SG_REL_ Gateway SG_ 977 BT_verriegelt 1000;
BA_REL_ "GenSigTimeoutTime" BU_SG_REL_ MFG SG_ 977 BT_verriegelt 1000;
BA_REL_ "GenSigTimeoutTime" BU_SG_REL_ VTS SG_ 977 BT_verriegelt 1000;
BA_REL_ "GenSigTimeoutTime" BU_SG_REL_ BCM2 SG_ 977 BT_gesafet 1000;
BA_REL_ "GenSigTimeoutTime" BU_SG_REL_ Gateway SG_ 977 BT_gesafet 1000;
BA_REL_ "GenSigTimeoutTime" BU_SG_REL_ MFG SG_ 977 BT_gesafet 1000;
BA_REL_ "GenSigTimeoutTime" BU_SG_REL_ VTS SG_ 977 BT_gesafet 1000;
BA_REL_ "GenSigTimeoutTime" BU_SG_REL_ BCM2 SG_ 977 BT_Schluesselschalter_auf 1000;
BA_REL_ "GenSigTimeoutTime" BU_SG_REL_ MFG SG_ 977 BT_Schluesselschalter_auf 1000;
BA_REL_ "GenSigTimeoutTime" BU_SG_REL_ BCM2 SG_ 977 BT_Schluesselschalter_zu 1000;
BA_REL_ "GenSigTimeoutTime" BU_SG_REL_ MFG SG_ 977 BT_Schluesselschalter_zu 1000;
BA_REL_ "GenSigTimeoutTime" BU_SG_REL_ BCM2 SG_ 977 BT_Unlock_Taster 1000;
BA_REL_ "GenSigTimeoutTime" BU_SG_REL_ MFG SG_ 977 BT_Unlock_Taster 1000;
BA_REL_ "GenSigTimeoutTime" BU_SG_REL_ TSG_FS SG_ 977 BT_Unlock_Taster 1000;
BA_REL_ "GenSigTimeoutTime" BU_SG_REL_ BCM2 SG_ 977 BT_Lock_Taster 1000;
BA_REL_ "GenSigTimeoutTime" BU_SG_REL_ MFG SG_ 977 BT_Lock_Taster 1000;
BA_REL_ "GenSigTimeoutTime" BU_SG_REL_ TSG_FS SG_ 977 BT_Lock_Taster 1000;
BA_REL_ "GenSigTimeoutTime" BU_SG_REL_ BCM2 SG_ 977 BT_Sperrklinke 1000;
BA_REL_ "GenSigTimeoutTime" BU_SG_REL_ MFG SG_ 977 BT_Sperrklinke 1000;
BA_REL_ "GenSigTimeoutTime" BU_SG_REL_ MFG SG_ 977 BT_TAG_betaetigt 1000;
BA_REL_ "GenSigTimeoutTime" BU_SG_REL_ TSG_FS SG_ 977 BT_TAG_betaetigt 1000;
BA_REL_ "GenSigTimeoutTime" BU_SG_REL_ VTS SG_ 977 BT_TAG_betaetigt 1000;
BA_REL_ "GenSigTimeoutTime" BU_SG_REL_ BCM1 SG_ 977 BT_TIG_betaetigt 1000;
BA_REL_ "GenSigTimeoutTime" BU_SG_REL_ BCM2 SG_ 977 BT_TIG_betaetigt 1000;
BA_REL_ "GenSigTimeoutTime" BU_SG_REL_ MFG SG_ 977 BT_TIG_betaetigt 1000;
BA_REL_ "GenSigTimeoutTime" BU_SG_REL_ TSG_FS SG_ 977 BT_TIG_betaetigt 1000;
BA_REL_ "GenSigTimeoutTime" BU_SG_REL_ MFG SG_ 977 BT_EC_Spiegel_Helligkeit 1000;
BA_REL_ "GenSigTimeoutTime" BU_SG_REL_ TSG_FS SG_ 977 BT_EC_Spiegel_Helligkeit 1000;
BA_REL_ "GenSigTimeoutTime" BU_SG_REL_ Gateway SG_ 977 BT_Sp_Heizung_Anf 1000;
BA_REL_ "GenSigTimeoutTime" BU_SG_REL_ TSG_FS SG_ 977 BT_Tuer_Status 1000;
BA_REL_ "GenSigTimeoutTime" BU_SG_REL_ Gateway SG_ 977 BT_TSG_hinten_verbaut 1000;
BA_REL_ "GenSigTimeoutTime" BU_SG_REL_ BCM1 SG_ 977 BT_Sp_Blk_def 1000;
BA_REL_ "GenSigTimeoutTime" BU_SG_REL_ MFG SG_ 977 BT_Sp_Blk_def 1000;
BA_REL_ "GenSigTimeoutTime" BU_SG_REL_ BCM2 SG_ 977 BT_FH_S_ManHoch 1000;
BA_REL_ "GenSigTimeoutTime" BU_SG_REL_ MFG SG_ 977 BT_FH_S_ManHoch 1000;
BA_REL_ "GenSigTimeoutTime" BU_SG_REL_ BCM2 SG_ 977 BT_FH_S_AutoHoch 1000;
BA_REL_ "GenSigTimeoutTime" BU_SG_REL_ MFG SG_ 977 BT_FH_S_AutoHoch 1000;
BA_REL_ "GenSigTimeoutTime" BU_SG_REL_ BCM2 SG_ 977 BT_FH_S_ManTief 1000;
BA_REL_ "GenSigTimeoutTime" BU_SG_REL_ MFG SG_ 977 BT_FH_S_ManTief 1000;
BA_REL_ "GenSigTimeoutTime" BU_SG_REL_ BCM2 SG_ 977 BT_FH_S_AutoTief 1000;
BA_REL_ "GenSigTimeoutTime" BU_SG_REL_ MFG SG_ 977 BT_FH_S_AutoTief 1000;
BA_REL_ "GenSigTimeoutTime" BU_SG_REL_ BCM1 SG_ 977 BT_FH_Oeffnung 1000;
BA_REL_ "GenSigTimeoutTime" BU_SG_REL_ BCM2 SG_ 977 BT_FH_Oeffnung 1000;
BA_REL_ "GenSigTimeoutTime" BU_SG_REL_ Gateway SG_ 977 BT_FH_Oeffnung 1000;
BA_REL_ "GenSigTimeoutTime" BU_SG_REL_ MFG SG_ 977 BT_FH_Oeffnung 1000;
BA_REL_ "GenSigTimeoutTime" BU_SG_REL_ SAD SG_ 977 BT_FH_Oeffnung 1000;
BA_REL_ "GenSigTimeoutTime" BU_SG_REL_ SAD2 SG_ 977 BT_FH_Oeffnung 1000;
BA_REL_ "GenSigTimeoutTime" BU_SG_REL_ VSG SG_ 977 BT_FH_Oeffnung 1000;
BA_REL_ "GenSigTimeoutTime" BU_SG_REL_ VTS SG_ 977 BT_FH_Oeffnung 1000;
BA_REL_ "GenSigTimeoutTime" BU_SG_REL_ MFG SG_ 977 BT_FH_Bew_hoch 1000;
BA_REL_ "GenSigTimeoutTime" BU_SG_REL_ TSG_FS SG_ 977 BT_FH_Bew_hoch 1000;
BA_REL_ "GenSigTimeoutTime" BU_SG_REL_ VSG SG_ 977 BT_FH_Bew_hoch 1000;
BA_REL_ "GenSigTimeoutTime" BU_SG_REL_ MFG SG_ 977 BT_FH_Bew_tief 1000;
BA_REL_ "GenSigTimeoutTime" BU_SG_REL_ TSG_FS SG_ 977 BT_FH_Bew_tief 1000;
BA_REL_ "GenSigTimeoutTime" BU_SG_REL_ Gateway SG_ 977 BT_FH_Fang 1000;
BA_REL_ "GenSigTimeoutTime" BU_SG_REL_ MFG SG_ 977 BT_FH_Fang 1000;
BA_REL_ "GenSigTimeoutTime" BU_SG_REL_ MFG SG_ 977 BT_FH_Block 1000;
BA_REL_ "GenSigTimeoutTime" BU_SG_REL_ BCM2 SG_ 977 BT_FH_Thermo 1000;
BA_REL_ "GenSigTimeoutTime" BU_SG_REL_ MFG SG_ 977 BT_FH_Thermo 1000;
BA_REL_ "GenSigTimeoutTime" BU_SG_REL_ BCM2 SG_ 977 BT_UEKB_aktiviert 1000;
BA_REL_ "GenSigTimeoutTime" BU_SG_REL_ MFG SG_ 977 BT_UEKB_aktiviert 1000;
BA_REL_ "GenSigTimeoutTime" BU_SG_REL_ TSG_FS SG_ 977 BT_Kisi_Fehler 1000;
BA_REL_ "GenSigTimeoutTime" BU_SG_REL_ BCM2 SG_ 977 BT_FH_normiert 1000;
BA_REL_ "GenSigTimeoutTime" BU_SG_REL_ Gateway SG_ 977 BT_FH_normiert 1000;
BA_REL_ "GenSigTimeoutTime" BU_SG_REL_ MFG SG_ 977 BT_FH_normiert 1000;
BA_REL_ "GenSigTimeoutTime" BU_SG_REL_ TSG_FS SG_ 977 BT_FH_normiert 1000;
BA_REL_ "GenSigTimeoutTime" BU_SG_REL_ VSG SG_ 977 BT_FH_normiert 1000;
BA_REL_ "GenSigTimeoutTime" BU_SG_REL_ VTS SG_ 977 BT_FH_normiert 1000;
BA_REL_ "GenSigTimeoutTime" BU_SG_REL_ MFG SG_ 977 BT_SP_ausgerastet 1000;
BA_REL_ "GenSigTimeoutTime" BU_SG_REL_ TSG_FS SG_ 977 BT_SP_ausgerastet 1000;
BA_REL_ "GenSigTimeoutTime" BU_SG_REL_ VTS SG_ 977 BT_SP_ausgerastet 1000;
BA_REL_ "GenSigTimeoutTime" BU_SG_REL_ MFG SG_ 977 BT_SP_lr_aktiv 1000;
BA_REL_ "GenSigTimeoutTime" BU_SG_REL_ TSG_FS SG_ 977 BT_SP_lr_aktiv 1000;
BA_REL_ "GenSigTimeoutTime" BU_SG_REL_ MFG SG_ 977 BT_SP_ht_aktiv 1000;
BA_REL_ "GenSigTimeoutTime" BU_SG_REL_ TSG_FS SG_ 977 BT_SP_ht_aktiv 1000;
BA_REL_ "GenSigTimeoutTime" BU_SG_REL_ MFG SG_ 977 BT_Oben_Block_erw 1000;
BA_REL_ "GenSigTimeoutTime" BU_SG_REL_ TSG_FS SG_ 977 BT_Oben_Block_erw 1000;
BA_REL_ "GenSigTimeoutTime" BU_SG_REL_ MFG SG_ 977 BT_Unten_Block_erw 1000;
BA_REL_ "GenSigTimeoutTime" BU_SG_REL_ TSG_FS SG_ 977 BT_Unten_Block_erw 1000;
BA_REL_ "GenSigTimeoutTime" BU_SG_REL_ BCM1 SG_ 977 BT_SP_Heizung_Status 1000;
BA_REL_ "GenSigTimeoutTime" BU_SG_REL_ MFG SG_ 977 BT_SP_Heizung_Status 1000;
BA_REL_ "GenSigTimeoutTime" BU_SG_REL_ BCM1 SG_ 977 ASW_Warnung_aktiv_BFS 1000;
BA_REL_ "GenSigTimeoutTime" BU_SG_REL_ MFG SG_ 977 BT_FH_Pos_oben 1000;
BA_REL_ "GenSigTimeoutTime" BU_SG_REL_ VSG SG_ 977 BT_FH_Pos_oben 1000;
BA_REL_ "GenSigTimeoutTime" BU_SG_REL_ BCM2 SG_ 977 BT_Tuerschloss_defekt 1000;
BA_REL_ "GenSigTimeoutTime" BU_SG_REL_ BCM2 SG_ 977 BT_Lock_Taster_inv 1000;
BA_REL_ "GenSigTimeoutTime" BU_SG_REL_ BCM2 SG_ 977 BT_Schluesselschalter_zu_inv 1000;
BA_REL_ "GenSigTimeoutTime" BU_SG_REL_ BCM1 SG_ 1451 TSG_FlHz_BFS_NTC_A 5000;
BA_REL_ "GenSigTimeoutTime" BU_SG_REL_ BCM1 SG_ 1451 TSG_FlHz_BFS_FnAbbruchHzKreis_A 5000;
BA_REL_ "GenSigTimeoutTime" BU_SG_REL_ BCM1 SG_ 1451 TSG_FlHz_BFS_NTC_B 5000;
BA_REL_ "GenSigTimeoutTime" BU_SG_REL_ BCM1 SG_ 1451 TSG_FlHz_BFS_FnAbbruchHzKreis_B 5000;
BA_REL_ "GenSigTimeoutTime" BU_SG_REL_ BCM1 SG_ 976 FT_Tuer_geoeffnet 1000;
BA_REL_ "GenSigTimeoutTime" BU_SG_REL_ BCM2 SG_ 976 FT_Tuer_geoeffnet 1000;
BA_REL_ "GenSigTimeoutTime" BU_SG_REL_ ELV SG_ 976 FT_Tuer_geoeffnet 1000;
BA_REL_ "GenSigTimeoutTime" BU_SG_REL_ Gateway SG_ 976 FT_Tuer_geoeffnet 1000;
BA_REL_ "GenSigTimeoutTime" BU_SG_REL_ IEZS SG_ 976 FT_Tuer_geoeffnet 1000;
BA_REL_ "GenSigTimeoutTime" BU_SG_REL_ MFG SG_ 976 FT_Tuer_geoeffnet 1000;
BA_REL_ "GenSigTimeoutTime" BU_SG_REL_ SitzMem_FS SG_ 976 FT_Tuer_geoeffnet 1000;
BA_REL_ "GenSigTimeoutTime" BU_SG_REL_ TSG_BFS SG_ 976 FT_Tuer_geoeffnet 1000;
BA_REL_ "GenSigTimeoutTime" BU_SG_REL_ VTS SG_ 976 FT_Tuer_geoeffnet 1000;
BA_REL_ "GenSigTimeoutTime" BU_SG_REL_ BCM2 SG_ 976 FT_verriegelt 1000;
BA_REL_ "GenSigTimeoutTime" BU_SG_REL_ Gateway SG_ 976 FT_verriegelt 1000;
BA_REL_ "GenSigTimeoutTime" BU_SG_REL_ MFG SG_ 976 FT_verriegelt 1000;
BA_REL_ "GenSigTimeoutTime" BU_SG_REL_ SitzMem_FS SG_ 976 FT_verriegelt 1000;
BA_REL_ "GenSigTimeoutTime" BU_SG_REL_ TSG_BFS SG_ 976 FT_verriegelt 1000;
BA_REL_ "GenSigTimeoutTime" BU_SG_REL_ VTS SG_ 976 FT_verriegelt 1000;
BA_REL_ "GenSigTimeoutTime" BU_SG_REL_ BCM2 SG_ 976 FT_gesafet 1000;
BA_REL_ "GenSigTimeoutTime" BU_SG_REL_ Gateway SG_ 976 FT_gesafet 1000;
BA_REL_ "GenSigTimeoutTime" BU_SG_REL_ MFG SG_ 976 FT_gesafet 1000;
BA_REL_ "GenSigTimeoutTime" BU_SG_REL_ TSG_BFS SG_ 976 FT_gesafet 1000;
BA_REL_ "GenSigTimeoutTime" BU_SG_REL_ VTS SG_ 976 FT_gesafet 1000;
BA_REL_ "GenSigTimeoutTime" BU_SG_REL_ BCM2 SG_ 976 FT_Schluesselschalter_auf 1000;
BA_REL_ "GenSigTimeoutTime" BU_SG_REL_ MFG SG_ 976 FT_Schluesselschalter_auf 1000;
BA_REL_ "GenSigTimeoutTime" BU_SG_REL_ TSG_BFS SG_ 976 FT_Schluesselschalter_auf 1000;
BA_REL_ "GenSigTimeoutTime" BU_SG_REL_ BCM2 SG_ 976 FT_Schluesselschalter_zu 1000;
BA_REL_ "GenSigTimeoutTime" BU_SG_REL_ MFG SG_ 976 FT_Schluesselschalter_zu 1000;
BA_REL_ "GenSigTimeoutTime" BU_SG_REL_ TSG_BFS SG_ 976 FT_Schluesselschalter_zu 1000;
BA_REL_ "GenSigTimeoutTime" BU_SG_REL_ BCM2 SG_ 976 FT_Unlock_Taster 1000;
BA_REL_ "GenSigTimeoutTime" BU_SG_REL_ MFG SG_ 976 FT_Unlock_Taster 1000;
BA_REL_ "GenSigTimeoutTime" BU_SG_REL_ TSG_BFS SG_ 976 FT_Unlock_Taster 1000;
BA_REL_ "GenSigTimeoutTime" BU_SG_REL_ BCM2 SG_ 976 FT_Lock_Taster 1000;
BA_REL_ "GenSigTimeoutTime" BU_SG_REL_ MFG SG_ 976 FT_Lock_Taster 1000;
BA_REL_ "GenSigTimeoutTime" BU_SG_REL_ TSG_BFS SG_ 976 FT_Lock_Taster 1000;
BA_REL_ "GenSigTimeoutTime" BU_SG_REL_ BCM2 SG_ 976 FT_Sperrklinke 1000;
BA_REL_ "GenSigTimeoutTime" BU_SG_REL_ MFG SG_ 976 FT_Sperrklinke 1000;
BA_REL_ "GenSigTimeoutTime" BU_SG_REL_ MFG SG_ 976 FT_TAG_betaetigt 1000;
BA_REL_ "GenSigTimeoutTime" BU_SG_REL_ BCM1 SG_ 976 FT_TIG_betaetigt 1000;
BA_REL_ "GenSigTimeoutTime" BU_SG_REL_ BCM2 SG_ 976 FT_TIG_betaetigt 1000;
BA_REL_ "GenSigTimeoutTime" BU_SG_REL_ MFG SG_ 976 FT_TIG_betaetigt 1000;
BA_REL_ "GenSigTimeoutTime" BU_SG_REL_ BCM2 SG_ 976 FT_IRUE_Taste 1000;
BA_REL_ "GenSigTimeoutTime" BU_SG_REL_ MFG SG_ 976 FT_IRUE_Taste 1000;
BA_REL_ "GenSigTimeoutTime" BU_SG_REL_ BCM2 SG_ 976 FT_HD_Taste 1000;
BA_REL_ "GenSigTimeoutTime" BU_SG_REL_ HDSG SG_ 976 FT_HD_Taste 1000;
BA_REL_ "GenSigTimeoutTime" BU_SG_REL_ MFG SG_ 976 FT_HD_Taste 1000;
BA_REL_ "GenSigTimeoutTime" BU_SG_REL_ BCM2 SG_ 976 FT_TD_Taste 1000;
BA_REL_ "GenSigTimeoutTime" BU_SG_REL_ MFG SG_ 976 FT_TD_Taste 1000;
BA_REL_ "GenSigTimeoutTime" BU_SG_REL_ TSG_BFS SG_ 976 SSR_Temp_Freigabe 1000;
BA_REL_ "GenSigTimeoutTime" BU_SG_REL_ Gateway SG_ 976 FT_Sp_Heizung_Anf 1000;
BA_REL_ "GenSigTimeoutTime" BU_SG_REL_ HDSG SG_ 976 FT_HD_Taste_2 1000;
BA_REL_ "GenSigTimeoutTime" BU_SG_REL_ Gateway SG_ 976 FT_TSG_hinten_verbaut 1000;
BA_REL_ "GenSigTimeoutTime" BU_SG_REL_ MFG SG_ 976 FT_TSG_hinten_verbaut 1000;
BA_REL_ "GenSigTimeoutTime" BU_SG_REL_ BCM1 SG_ 976 FT_Sp_Blk_def 1000;
BA_REL_ "GenSigTimeoutTime" BU_SG_REL_ MFG SG_ 976 FT_Sp_Blk_def 1000;
BA_REL_ "GenSigTimeoutTime" BU_SG_REL_ BCM2 SG_ 976 FT_FH_S_ManHoch 1000;
BA_REL_ "GenSigTimeoutTime" BU_SG_REL_ MFG SG_ 976 FT_FH_S_ManHoch 1000;
BA_REL_ "GenSigTimeoutTime" BU_SG_REL_ BCM2 SG_ 976 FT_FH_S_AutoHoch 1000;
BA_REL_ "GenSigTimeoutTime" BU_SG_REL_ MFG SG_ 976 FT_FH_S_AutoHoch 1000;
BA_REL_ "GenSigTimeoutTime" BU_SG_REL_ BCM2 SG_ 976 FT_FH_S_ManTief 1000;
BA_REL_ "GenSigTimeoutTime" BU_SG_REL_ MFG SG_ 976 FT_FH_S_ManTief 1000;
BA_REL_ "GenSigTimeoutTime" BU_SG_REL_ BCM2 SG_ 976 FT_FH_S_AutoTief 1000;
BA_REL_ "GenSigTimeoutTime" BU_SG_REL_ MFG SG_ 976 FT_FH_S_AutoTief 1000;
BA_REL_ "GenSigTimeoutTime" BU_SG_REL_ BCM1 SG_ 976 FT_FH_Oeffnung 1000;
BA_REL_ "GenSigTimeoutTime" BU_SG_REL_ BCM2 SG_ 976 FT_FH_Oeffnung 1000;
BA_REL_ "GenSigTimeoutTime" BU_SG_REL_ Gateway SG_ 976 FT_FH_Oeffnung 1000;
BA_REL_ "GenSigTimeoutTime" BU_SG_REL_ MFG SG_ 976 FT_FH_Oeffnung 1000;
BA_REL_ "GenSigTimeoutTime" BU_SG_REL_ SAD SG_ 976 FT_FH_Oeffnung 1000;
BA_REL_ "GenSigTimeoutTime" BU_SG_REL_ SAD2 SG_ 976 FT_FH_Oeffnung 1000;
BA_REL_ "GenSigTimeoutTime" BU_SG_REL_ VSG SG_ 976 FT_FH_Oeffnung 1000;
BA_REL_ "GenSigTimeoutTime" BU_SG_REL_ VTS SG_ 976 FT_FH_Oeffnung 1000;
BA_REL_ "GenSigTimeoutTime" BU_SG_REL_ MFG SG_ 976 FT_FH_Bew_hoch 1000;
BA_REL_ "GenSigTimeoutTime" BU_SG_REL_ TSG_BFS SG_ 976 FT_FH_Bew_hoch 1000;
BA_REL_ "GenSigTimeoutTime" BU_SG_REL_ VSG SG_ 976 FT_FH_Bew_hoch 1000;
BA_REL_ "GenSigTimeoutTime" BU_SG_REL_ MFG SG_ 976 FT_FH_Bew_tief 1000;
BA_REL_ "GenSigTimeoutTime" BU_SG_REL_ TSG_BFS SG_ 976 FT_FH_Bew_tief 1000;
BA_REL_ "GenSigTimeoutTime" BU_SG_REL_ Gateway SG_ 976 FT_FH_Fang 1000;
BA_REL_ "GenSigTimeoutTime" BU_SG_REL_ MFG SG_ 976 FT_FH_Fang 1000;
BA_REL_ "GenSigTimeoutTime" BU_SG_REL_ MFG SG_ 976 FT_FH_Block 1000;
BA_REL_ "GenSigTimeoutTime" BU_SG_REL_ BCM2 SG_ 976 FT_FH_Thermo 1000;
BA_REL_ "GenSigTimeoutTime" BU_SG_REL_ MFG SG_ 976 FT_FH_Thermo 1000;
BA_REL_ "GenSigTimeoutTime" BU_SG_REL_ BCM2 SG_ 976 FT_UEKB_aktiviert 1000;
BA_REL_ "GenSigTimeoutTime" BU_SG_REL_ MFG SG_ 976 FT_UEKB_aktiviert 1000;
BA_REL_ "GenSigTimeoutTime" BU_SG_REL_ BCM2 SG_ 976 FT_FH_normiert 1000;
BA_REL_ "GenSigTimeoutTime" BU_SG_REL_ Gateway SG_ 976 FT_FH_normiert 1000;
BA_REL_ "GenSigTimeoutTime" BU_SG_REL_ MFG SG_ 976 FT_FH_normiert 1000;
BA_REL_ "GenSigTimeoutTime" BU_SG_REL_ VSG SG_ 976 FT_FH_normiert 1000;
BA_REL_ "GenSigTimeoutTime" BU_SG_REL_ VTS SG_ 976 FT_FH_normiert 1000;
BA_REL_ "GenSigTimeoutTime" BU_SG_REL_ MFG SG_ 976 FT_Schliesstaster 1000;
BA_REL_ "GenSigTimeoutTime" BU_SG_REL_ MFG SG_ 976 FT_Zuziehhilfe_aktiv 1000;
BA_REL_ "GenSigTimeoutTime" BU_SG_REL_ MFG SG_ 976 FT_SP_ausgerastet 1000;
BA_REL_ "GenSigTimeoutTime" BU_SG_REL_ VTS SG_ 976 FT_SP_ausgerastet 1000;
BA_REL_ "GenSigTimeoutTime" BU_SG_REL_ MFG SG_ 976 FT_SP_lr_aktiv 1000;
BA_REL_ "GenSigTimeoutTime" BU_SG_REL_ MFG SG_ 976 FT_SP_ht_aktiv 1000;
BA_REL_ "GenSigTimeoutTime" BU_SG_REL_ AAG SG_ 976 ASW_wakeup 1000;
BA_REL_ "GenSigTimeoutTime" BU_SG_REL_ MFG SG_ 976 FT_Oben_Block_erw 1000;
BA_REL_ "GenSigTimeoutTime" BU_SG_REL_ TSG_BFS SG_ 976 FT_Oben_Block_erw 1000;
BA_REL_ "GenSigTimeoutTime" BU_SG_REL_ MFG SG_ 976 FT_Unten_Block_erw 1000;
BA_REL_ "GenSigTimeoutTime" BU_SG_REL_ TSG_BFS SG_ 976 FT_Unten_Block_erw 1000;
BA_REL_ "GenSigTimeoutTime" BU_SG_REL_ BCM1 SG_ 976 FT_Kisi_li_aktiv 1000;
BA_REL_ "GenSigTimeoutTime" BU_SG_REL_ BCM2 SG_ 976 FT_Kisi_li_aktiv 1000;
BA_REL_ "GenSigTimeoutTime" BU_SG_REL_ MFG SG_ 976 FT_Kisi_li_aktiv 1000;
BA_REL_ "GenSigTimeoutTime" BU_SG_REL_ SAD SG_ 976 FT_Kisi_li_aktiv 1000;
BA_REL_ "GenSigTimeoutTime" BU_SG_REL_ SAD2 SG_ 976 FT_Kisi_li_aktiv 1000;
BA_REL_ "GenSigTimeoutTime" BU_SG_REL_ SitzMem_HBFS SG_ 976 FT_Kisi_li_aktiv 1000;
BA_REL_ "GenSigTimeoutTime" BU_SG_REL_ SitzMem_HFS SG_ 976 FT_Kisi_li_aktiv 1000;
BA_REL_ "GenSigTimeoutTime" BU_SG_REL_ TSG_BFS SG_ 976 FT_Kisi_li_aktiv 1000;
BA_REL_ "GenSigTimeoutTime" BU_SG_REL_ BCM1 SG_ 976 FT_Kisi_re_aktiv 1000;
BA_REL_ "GenSigTimeoutTime" BU_SG_REL_ BCM2 SG_ 976 FT_Kisi_re_aktiv 1000;
BA_REL_ "GenSigTimeoutTime" BU_SG_REL_ MFG SG_ 976 FT_Kisi_re_aktiv 1000;
BA_REL_ "GenSigTimeoutTime" BU_SG_REL_ SAD SG_ 976 FT_Kisi_re_aktiv 1000;
BA_REL_ "GenSigTimeoutTime" BU_SG_REL_ SAD2 SG_ 976 FT_Kisi_re_aktiv 1000;
BA_REL_ "GenSigTimeoutTime" BU_SG_REL_ SitzMem_HBFS SG_ 976 FT_Kisi_re_aktiv 1000;
BA_REL_ "GenSigTimeoutTime" BU_SG_REL_ SitzMem_HFS SG_ 976 FT_Kisi_re_aktiv 1000;
BA_REL_ "GenSigTimeoutTime" BU_SG_REL_ TSG_BFS SG_ 976 FT_Kisi_re_aktiv 1000;
BA_REL_ "GenSigTimeoutTime" BU_SG_REL_ MFG SG_ 976 FT_Kisi_Taster_li 1000;
BA_REL_ "GenSigTimeoutTime" BU_SG_REL_ TSG_BFS SG_ 976 FT_Kisi_Taster_li 1000;
BA_REL_ "GenSigTimeoutTime" BU_SG_REL_ MFG SG_ 976 FT_Kisi_Taster_re 1000;
BA_REL_ "GenSigTimeoutTime" BU_SG_REL_ TSG_BFS SG_ 976 FT_Kisi_Taster_re 1000;
BA_REL_ "GenSigTimeoutTime" BU_SG_REL_ MFG SG_ 976 FT_BFS_Fond_Freigabe 1000;
BA_REL_ "GenSigTimeoutTime" BU_SG_REL_ SitzMem_BFS SG_ 976 FT_BFS_Fond_Freigabe 1000;
BA_REL_ "GenSigTimeoutTime" BU_SG_REL_ SitzMem_FS SG_ 976 FT_BFS_Fond_Freigabe 1000;
BA_REL_ "GenSigTimeoutTime" BU_SG_REL_ TSG_BFS SG_ 976 FT_BFS_Fond_Freigabe 1000;
BA_REL_ "GenSigTimeoutTime" BU_SG_REL_ MFG SG_ 976 FT_Kisi_Fehler 1000;
BA_REL_ "GenSigTimeoutTime" BU_SG_REL_ MFG SG_ 976 FT_Daemmglas 1000;
BA_REL_ "GenSigTimeoutTime" BU_SG_REL_ BCM1 SG_ 976 FT_SP_Heizung_Status 1000;
BA_REL_ "GenSigTimeoutTime" BU_SG_REL_ MFG SG_ 976 FT_SP_Heizung_Status 1000;
BA_REL_ "GenSigTimeoutTime" BU_SG_REL_ TSG_BFS SG_ 976 FT_SP_Heizung_Status 1000;
BA_REL_ "GenSigTimeoutTime" BU_SG_REL_ BCM1 SG_ 976 ASW_Warnung_aktiv_FS 1000;
BA_REL_ "GenSigTimeoutTime" BU_SG_REL_ MFG SG_ 976 FT_FH_Pos_oben 1000;
BA_REL_ "GenSigTimeoutTime" BU_SG_REL_ VSG SG_ 976 FT_FH_Pos_oben 1000;
BA_REL_ "GenSigTimeoutTime" BU_SG_REL_ BCM2 SG_ 976 FT_Tuerschloss_defekt 1000;
BA_REL_ "GenSigTimeoutTime" BU_SG_REL_ AAG SG_ 976 FT_SWA_Taster 1000;
BA_REL_ "GenSigTimeoutTime" BU_SG_REL_ BCM2 SG_ 997 TSG_FT_02_CRC 1000;
BA_REL_ "GenSigTimeoutTime" BU_SG_REL_ BCM2 SG_ 997 TSG_FT_02_BZ 1000;
BA_REL_ "GenSigTimeoutTime" BU_SG_REL_ BCM2 SG_ 997 FT_Tuer_Status 1000;
BA_REL_ "GenSigTimeoutTime" BU_SG_REL_ BCM2 SG_ 997 FT_Tuer_Status_QBit 1000;
BA_REL_ "GenSigTimeoutTime" BU_SG_REL_ BCM2 SG_ 997 FT_Lock_Taster_02 1000;
BA_REL_ "GenSigTimeoutTime" BU_SG_REL_ BCM2 SG_ 997 FT_Schluesselschalter_zu_02 1000;
BA_REL_ "GenSigTimeoutTime" BU_SG_REL_ TSG_BFS SG_ 997 FT_SP_Heizung_ein 1000;
BA_REL_ "GenSigTimeoutTime" BU_SG_REL_ MFG SG_ 997 FT_Kisi_Taster_li_02 1000;
BA_REL_ "GenSigTimeoutTime" BU_SG_REL_ TSG_BFS SG_ 997 FT_Kisi_Taster_li_02 1000;
BA_REL_ "GenSigTimeoutTime" BU_SG_REL_ MFG SG_ 997 FT_Kisi_Taster_re_02 1000;
BA_REL_ "GenSigTimeoutTime" BU_SG_REL_ TSG_BFS SG_ 997 FT_Kisi_Taster_re_02 1000;
BA_REL_ "GenSigTimeoutTime" BU_SG_REL_ BCM1 SG_ 1449 TSG_FlHz_FS_NTC_A 5000;
BA_REL_ "GenSigTimeoutTime" BU_SG_REL_ BCM1 SG_ 1449 TSG_FlHz_FS_FnAbbruchHzKreis_A 5000;
BA_REL_ "GenSigTimeoutTime" BU_SG_REL_ BCM1 SG_ 1449 TSG_FlHz_FS_NTC_B 5000;
BA_REL_ "GenSigTimeoutTime" BU_SG_REL_ BCM1 SG_ 1449 TSG_FlHz_FS_FnAbbruchHzKreis_B 5000;
VAL_ 1616 RA_Radio_Error_Flag 0 "kein_KD_Fehler" 1 "KD_Fehler" ;
VAL_ 1616 RA_Frequency_unit 0 "1_kHz" 1 "100_kHz" ;
VAL_ 1616 RA_AM_Tuning 0 "frequency_locked" 1 "AM_tuning" ;
VAL_ 695 RCTA_Info_rechts 0 "RCTA_hat_rechts_nichts_erkannt" 1 "RCTA_hat_rechts_blind_erkannt" 2 "RCTA_hat_rechts_frei_erkannt" 3 "RCTA_hat_rechts_unkritisch_erkannt" 4 "RCTA_hat_rechts_relevant_aber_unkritisch_erkannt" 5 "RCTA_hat_rechts_kritisch_erkannt" 6 "RCTA_hat_rechts_sehr_kritisch_erkannt" 7 "RCTA_meldet_rechts_Kollision_steht_bevor" ;
VAL_ 695 RCTA_Anforderung_HMS 0 "keine Anforderung" 1 "halten" 2 "parken" 3 "Halten Standby" 4 "anfahren" 5 "loesen_ueber_Rampe" ;
VAL_ 695 RCTA_Bremsruck_Anforderung 0 "nicht_angefordert" 1 "angefordert" ;
VAL_ 695 RCTA_Bremsruck_Freigabe 0 "keine_Freigabe" 1 "Freigabe" ;
VAL_ 695 RCTA_Info_links 0 "RCTA_hat_links_nichts_erkannt" 1 "RCTA_hat_links_blind_erkannt" 2 "RCTA_hat_links_frei_erkannt" 3 "RCTA_hat_links_unkritisch_erkannt" 4 "RCTA_hat_links_relevant_aber_unkritisch_erkannt" 5 "RCTA_hat_links_kritisch_erkannt" 6 "RCTA_hat_links_sehr_kritisch_erkannt" 7 "RCTA_meldet_links_Kollision_steht_bevor" ;
VAL_ 695 RCTA_Status 0 "Aus" 1 "Passiv" 2 "Aktiv" 3 "Fehler" ;
VAL_ 695 RCTA_Warnton 0 "Aus" 1 "Ein" ;
VAL_ 695 RCTA_Notbremsung_Freigabe 0 "keine_Freigabe" 1 "Freigabe" ;
VAL_ 695 RCTA_Notbremsung_Anforderung 0 "Init" 255 "Fehler" ;
VAL_ 1529 RDK_FMVSS138_Lampe 0 "RDK_WaLa_inaktiv" 1 "RDK_WaLa_aktiv" ;
VAL_ 1529 RDK_FMVSS138_MIL 0 "keine_Stoerungsanzeige" 1 "Stoerungsanzeige" ;
VAL_ 1529 RDK_Kalibrierung 0 "BAP_Kalibrierung" 1 "CAN_Kombitaster_Kalibrierung" ;
VAL_ 1529 RDK_Warnungen_02 0 "keine_Anzeige" 1 "Reifen_allgemein_Warnstufe_1" 2 "Reifen_vorne_links_Warnstufe_1" 3 "Reifen_vorne_rechts_Warnstufe_1" 4 "Reifen_hinten_links_Warnstufe_1" 5 "Reifen_hinten_rechts_Warnstufe_1" 6 "Reifen_allgemein_Warnstufe_2" 7 "Reifen_vorne_links_Warnstufe_2" 8 "Reifen_vorne_rechts_Warnstufe_2" 9 "Reifen_hinten_links_Warnstufe_2" 10 "Reifen_hinten_rechts_Warnstufe_2" 11 "Reifen_allgemein_Warnstufe_3" 12 "Reifen_vorne_links_Warnstufe_3" 13 "Reifen_vorne_rechts_Warnstufe_3" 14 "Reifen_hinten_links_Warnstufe_3" 15 "Reifen_hinten_rechts_Warnstufe_3" 16 "Akustikausgabe_Kalibrierung_erfolgreich" 17 "Textausgabe_Kalibrierung_erfolgreich" 18 "Akustik_Textausgabe_Kalibrierung_erfolgreich" 19 "RDK_aktiviert" 20 "RDK_deaktiviert" 21 "RDK_Systemstoerung" 22 "RDK_Systemstoerung_temporaer" 23 "V_Warnschwelle_1" 24 "V_Warnschwelle_2" 25 "Radwechsel_allgemein" 26 "Teilueberwachung" ;
VAL_ 1711 RV_Video_on 0 "Kamerabild wird nicht angezeigt" 1 "Kamerabild wird angezeigt" ;
VAL_ 1711 RV_Dark_Screen 0 "Kamerabild nicht verdunkeln" 1 "Kamerabild verdunkeln" ;
VAL_ 1711 RV_HMI_Mode 0 "Parkluecke  (Modus 1)" 1 "Parallel zur Straße (Modus 2)" 2 "reserviert" 3 "Kalibrierung (nur Diagnose)" ;
VAL_ 1711 RV_GL_side 0 "Guidelines_abgeschaltet" 1 "Guidelines_Anzeige_rechte_Seite" 2 "Guiedelines_Anzeige_linke_Seite" 3 "Guiedelines_Anzeige_beide_Seiten" ;
VAL_ 1711 RV_System_aktiv 0 "System nicht betriebsbereit" 1 "System betriebsbereit" ;
VAL_ 1711 RV_Settings_enabled 0 "Menu 'Einstellungen' nicht aktiviert" 1 "Menu 'Einstellungen' aktiviert" ;
VAL_ 1711 RV_Menu_Item 0 "HMI Mode als ausgewaehlt markiert" 1 "Helligkeit als ausgewaehlt markiert" 2 "Kontrast als ausgewaehlt markiert" 3 "Farbsaettigung als ausgewaehlt markiert" ;
VAL_ 1711 SV_Video_on 0 "SideView_aus_/_nicht_verbaut" 1 "SideView_an" ;
VAL_ 1711 RV_Calib_Fehler 0 "Kalibrierung_i.O." 1 "RearView_nicht_kalibriert" ;
VAL_ 1711 RV_GL_Trailer_connect 0 "Guidelines_werden_angezeigt" 1 "Guidelines_wegen_angekoppeltem_Anhänger_deaktiviert" ;
VAL_ 1711 RV_GL_Trunk_open 0 "Guidelines_werden_angezeigt" 1 "Guidelines_wegen_geöffneter_Heckklappe_deaktiviert" ;
VAL_ 1711 RV_GL_LWS_Fehler 0 "Guidelines_werden_angezeigt" 1 "Guidelines_wegen_nicht_kalibriertem_Lenkwinkelsensor_deaktiviert" ;
VAL_ 1525 RW_Gesamt_Reichweite_Max_Anzeige 2045 "nicht_verbaut" 2046 "Init" 2047 "Fehler" ;
VAL_ 1525 RW_RWDS_Lastprofil 2046 "Init" 2047 "Fehler" ;
VAL_ 1525 RW_Gesamt_Reichweite 2045 "nicht_verbaut" 2046 "Init" 2047 "Fehler" ;
VAL_ 1525 RW_Prim_Reichweitenverbrauch 2047 "Init" ;
VAL_ 1525 RW_Prim_Reichweitenv_Einheit 0 "Liter_pro_100km" 1 "kWh_pro_100km" 2 "Kg_pro_100km" 3 "nicht_verbaut" ;
VAL_ 1525 RW_Primaer_Reichweite 2045 "nicht_verbaut" 2046 "Init" 2047 "Fehler" ;
VAL_ 1527 RW_Reservewarnung_aktiv 0 "inaktiv" 1 "aktiv" ;
VAL_ 1527 RW_Reichweite_Einheit_Anzeige 0 "km" 1 "miles" ;
VAL_ 1527 RW_Gesamt_Reichweite_Anzeige 2045 "nicht_verbaut" 2046 "Init" 2047 "Fehler" ;
VAL_ 1527 RW_Primaer_Reichweite_Anzeige 2045 "nicht_verbaut" 2046 "Init" 2047 "Fehler" ;
VAL_ 1527 RW_Sekundaer_Reichweite_Anzeige 2045 "nicht_verbaut" 2046 "Init" 2047 "Fehler" ;
VAL_ 1527 RW_Sekundaer_Reichweite 2045 "nicht_verbaut" 2046 "Init" 2047 "Fehler" ;
VAL_ 1527 RW_Sek_Reichweitenv_Einheit 0 "Liter_pro_100km" 1 "kWh_pro_100km" 2 "Kg_pro_100km" 3 "nicht_verbaut" ;
VAL_ 1527 RW_Sek_Reichweitenverbrauch 2047 "Init" ;
VAL_ 1440 LS_Helligkeit_IR 254 "Init" 255 "Fehler" ;
VAL_ 1440 LS_Helligkeit_FW 1022 "Init" 1023 "Fehler" ;
VAL_ 1440 LS_defekt 0 "OK" 1 "defekt" ;
VAL_ 1440 LS_Verbau 1 "Lichtsensor verbaut" ;
VAL_ 1440 RS_Regenmenge 14 "Init" 15 "Fehler" ;
VAL_ 1440 RS_Verbau 1 "Regensensor verbaut" ;
VAL_ 1440 RS_Verglasung_schliessen 0 "Verglasung nicht schliessen" 1 "Verglasung schliessen" ;
VAL_ 1440 RS_defekt 0 "OK" 1 "defekt" ;
VAL_ 1440 RS_Wischergeschwindigkeit 0 "kein Wischen" 1 "42 Huebe/min" 2 "45 Huebe/min" 3 "48 Huebe/min" 4 "51 Huebe/min" 5 "54 Huebe/min" 6 "57 Huebe/min" 7 "60 Huebe/min" ;
VAL_ 1440 RLS_Vorfeldhelligkeit_Boost 0 "groesser_24413_Lux" 1 "bis_24413_Lux" 2 "bis_22193_Lux" 3 "bis_20176_Lux" 4 "bis_18342_Lux" 5 "bis_16647_Lux" 6 "bis_15158_Lux" 7 "bis_13780_Lux" 8 "bis_12527_Lux" 9 "bis_11388_Lux" 10 "bis_10353_Lux" 11 "bis_9412_Lux" 12 "bis_8556_Lux" 13 "bis_7778_Lux" 14 "bis_7071_Lux" 15 "bis_6428_Lux" ;
VAL_ 1517 SAD2_Deckel_Lage 0 "Austelllage" 1 "Schiebelage" ;
VAL_ 1517 SAD2_Deckel_normiert 0 "inaktiv" 1 "aktiv" ;
VAL_ 1517 SAD2_Deckel_Thermoschutz 0 "inaktiv" 1 "aktiv" ;
VAL_ 1517 SAD2_Deckel_UEKB_aktiv 0 "inaktiv" 1 "aktiv" ;
VAL_ 1517 SAD2_Rollo_Lage 0 "Austelllage" 1 "Schiebelage" ;
VAL_ 1517 SAD2_Rollo_normiert 0 "inaktiv" 1 "aktiv" ;
VAL_ 1517 SAD2_Rollo_Thermoschutz 0 "inaktiv" 1 "aktiv" ;
VAL_ 1517 SAD2_Rollo_UEKB_aktiv 0 "inaktiv" 1 "aktiv" ;
VAL_ 1504 MD1_Position 127 "nicht_normiert" ;
VAL_ 1504 MD1_Lage 0 "Ausstelllage" 1 "Schiebelage" ;
VAL_ 1504 MD3_Lage 0 "Ausstelllage" 1 "Schiebelage" ;
VAL_ 1504 MRollo_Position 127 "nicht_normiert" ;
VAL_ 1504 MRollo_Lage 0 "Ausstelllage" 1 "Schiebelage" ;
VAL_ 1504 SAD_normiert 0 "inaktiv" 1 "aktiv" ;
VAL_ 1504 SAD_Thermoschutz 0 "inaktiv" 1 "aktiv" ;
VAL_ 1504 SAD_UEKB_aktiv 0 "inaktiv" 1 "aktiv" ;
VAL_ 1504 Rollo_normiert 0 "inaktiv" 1 "aktiv" ;
VAL_ 1504 Rollo_Thermoschutz 0 "inaktiv" 1 "aktiv" ;
VAL_ 1504 Rollo_UEKB_aktiv 0 "inaktiv" 1 "aktiv" ;
VAL_ 1504 SAD_Taster_Deckel_hi 0 "nicht_betaetigt" 1 "man_sl_zu" 2 "auto_sl_zu" 3 "man_sl_auf" 4 "auto_sl_auf" 5 "man_al_auf" 6 "auto_al_auf" 7 "man_al_zu" 8 "auto_al_zu" 14 "fehler_schalter_haengt" 15 "fehler_schalter_unplausibel" ;
VAL_ 1504 SAD_Taster_Deckel_vo 0 "nicht_betaetigt" 1 "man_sl_zu" 2 "auto_sl_zu" 3 "man_sl_auf" 4 "auto_sl_auf" 5 "man_al_auf" 6 "auto_al_auf" 7 "man_al_zu" 8 "auto_al_zu" 14 "fehler_schalter_haengt" 15 "fehler_schalter_unplausibel" ;
VAL_ 1504 SAD_Taster_Rollo_hi 0 "nicht_betaetigt" 1 "man_zu" 2 "auto_zu" 3 "man_auf" 4 "auto_auf" 6 "fehler_schalter_haengt" 7 "fehler_schalter_unplausibel" ;
VAL_ 1504 SAD_Taster_Rollo_vo 0 "nicht_betaetigt" 1 "man_zu" 2 "auto_zu" 3 "man_auf" 4 "auto_auf" 6 "fehler_schalter_haengt" 7 "fehler_schalter_unplausibel" ;
VAL_ 424 SARA_Accel_X_r 0 "nicht_verbaut" 8191 "Fehler" ;
VAL_ 424 SARA_Accel_Y_r 0 "nicht_verbaut" 8191 "Fehler" ;
VAL_ 424 SARA_Omega_Z_r 0 "nicht_verbaut" 8191 "Fehler" ;
VAL_ 424 SARA_CF_Accel_X_r 0 "gueltiger_Wert" 1 "nicht_belegt" 2 "nicht_belegt" 3 "temporaerer_Fehler" 4 "Init" 5 "Sensor_nicht_verbaut_Signal_nicht_berrechnet" 6 "Sensor_nicht_abgeglichen" 7 "Sensor_defekt" ;
VAL_ 424 SARA_CF_Accel_Y_r 0 "gueltiger_Wert" 1 "nicht_belegt" 2 "nicht_belegt" 3 "temporaerer_Fehler" 4 "Init" 5 "Sensor_nicht_verbaut_Signal_nicht_berrechnet" 6 "Sensor_nicht_abgeglichen" 7 "Sensor_defekt" ;
VAL_ 424 SARA_CF_Omega_Z_r 0 "gueltiger_Wert" 1 "nicht_belegt" 2 "nicht_belegt" 3 "temporaerer_Fehler" 4 "Init" 5 "Sensor_nicht_verbaut_Signal_nicht_berrechnet" 6 "Sensor_nicht_abgeglichen" 7 "Sensor_defekt" ;
VAL_ 1522 KBI_Phototransistor 254 "Init" 255 "Fehler" ;
VAL_ 1522 KBI_Dimmpoti 126 "Nicht verfügbar" 127 "Fehler" ;
VAL_ 1363 SR3_Status_Lehne_Links 0 "nicht_entriegelt" 1 "entriegelt" ;
VAL_ 1363 SR3_Status_Lehne_Rechts 0 "nicht_entriegelt" 1 "entriegelt" ;
VAL_ 980 BH_Blinker_li 0 "nicht_betaetigt" 1 "Blinkerhebel_Richtung_links_betaetigt" ;
VAL_ 980 BH_Blinker_re 0 "nicht_betaetigt" 1 "Blinkerhebel_Richtung_rechts_betaetigt" ;
VAL_ 980 BH_Lichthupe 0 "nicht_betaetigt" 1 "Blinkerhebel in Richtung Lichthupe betaetigt" ;
VAL_ 980 BH_Fernlicht 0 "nicht_betaetigt" 1 "Blinkerhebel_in_Richtung_Fernlicht_betaetigt" ;
VAL_ 980 WH_Tipwischen 0 "nicht_betaetigt" 1 "betaetigt" ;
VAL_ 980 WH_Intervall 0 "aus" 1 "Wischerhebel in Stellung Intervall" ;
VAL_ 980 WH_WischerStufe1 0 "aus" 1 "Wischerhebel in Stufe Wischen 1" ;
VAL_ 980 WH_WischerStufe2 0 "aus" 1 "Wischerhebel in Stufe Wischen 2" ;
VAL_ 980 WH_Frontwaschen 0 "aus" 1 "Wischerhebel in Stellung Wisch Wasch vorne" ;
VAL_ 980 WH_Heckintervall 0 "nicht_betaetigt" 1 "Wischerhebel in Stellung Heckintervall" ;
VAL_ 980 WH_Heckwaschen 0 "nicht_betaetigt" 1 "Wischerhebel in Stellung Wisch Wasch hinten" ;
VAL_ 980 WH_Intervallstufen 0 "Init / Default" 1 "Intervallstufe 1" 5 "Intervallstufe 2" 9 "Intervallstufe 3" 13 "Intervallstufe 4" 15 "Fehler" ;
VAL_ 980 FAS_Taster 0 "nicht_betaetigt" 1 "betaetigt" ;
VAL_ 980 FAS_Taster_Fehler 0 "kein_Fehler" 1 "Fehler" ;
VAL_ 980 SMLS_Hupe 0 "nicht_betaetigt" 1 "Hupe_gedrueckt" ;
VAL_ 980 LRH_on_off 0 "LRH_aus__keine Anzeige" 1 "LRH_aus" 2 "LRH_ein" 3 "Fehler" ;
VAL_ 980 LRH_aktiv 0 "inaktiv" 1 "aktiv" ;
VAL_ 980 SMLS_P_verriegelt_plausibel 0 "unplausibel" 1 "plausibel" ;
VAL_ 980 WH_SRA 0 "SRA_Aus" 1 "SRA_Ein" ;
VAL_ 980 WH_Wischer_Fehler 0 "kein_Fehler" 1 "Fehler" ;
VAL_ 980 BH_Blinker_Fehler 0 "kein_Fehler" 1 "Fehler" ;
VAL_ 1467 SoSe_SunInt_2D_Li 254 "Init" 255 "Fehler" ;
VAL_ 1467 SoSe_SunInt_2D_Re 254 "Init" 255 "Fehler" ;
VAL_ 1710 SP_FT_oben 0 "nicht_betaetigt" 1 "betaetigt" ;
VAL_ 1710 SP_FT_unten 0 "nicht_betaetigt" 1 "betaetigt" ;
VAL_ 1710 SP_FT_links 0 "nicht_betaetigt" 1 "betaetigt" ;
VAL_ 1710 SP_FT_rechts 0 "nicht_betaetigt" 1 "betaetigt" ;
VAL_ 1710 SP_BT_oben 0 "nicht_betaetigt" 1 "betaetigt" ;
VAL_ 1710 SP_BT_unten 0 "nicht_betaetigt" 1 "betaetigt" ;
VAL_ 1710 SP_BT_links 0 "nicht_betaetigt" 1 "betaetigt" ;
VAL_ 1710 SP_BT_rechts 0 "nicht_betaetigt" 1 "betaetigt" ;
VAL_ 1710 SP_abklappen 0 "Spiegel_abklappen_nicht_aktiv" 1 "Spiegel_abklappen_aktiv" ;
VAL_ 1710 SP_anklappen 0 "Spiegle_anklappen_nicht_aktiv" 1 "Spiegel_anklappen_aktiv" ;
VAL_ 1710 SP_normieren 0 "Spiegel_nicht_normiert" 1 "Spiegel_normiert" ;
VAL_ 1710 SP_Hzg_Taster 0 "nicht_betaetigt" 1 "betaetigt" ;
VAL_ 1710 SP_S_oben 1 "Spiegelschalter in Stellung oben" ;
VAL_ 1710 SP_S_unten 1 "Spiegelschalter in Stellung unten" ;
VAL_ 1710 SP_S_links 1 "Spiegelschalter in Stellung links" ;
VAL_ 1710 SP_S_rechts 1 "Spiegelschalter in Stellung rechts" ;
VAL_ 1710 SP_Auswahl_li 1 "Spiegelschalter in Stellung Auswahl links" ;
VAL_ 1710 SP_Auswahl_re 1 "Spiegelschalter in Stellung Auswahl rechts" ;
VAL_ 1710 SP_ARA_Status 0 "TSG nicht im ARA-Modus" 1 "TSG im ARA-Modus" ;
VAL_ 1710 SP_S_Klappen 1 "Spiegelschalter in Stellung Klappen" ;
VAL_ 1710 SP_Verstellschalter_Fehler 0 "kein_Fehler" 1 "Fehler" ;
VAL_ 904 SpoilerSG_HSpoiler_IstPos 254 "Init" 255 "Fehler" ;
VAL_ 904 SpoilerSG_Fehler 0 "Init_bzw_kein_Fehler" 1 "Stoerung_Spoiler_gelb" 2 "Fehler_Spoiler_Prio1_rot" 3 "Fehler_Spoiler_Prio2_rot" ;
VAL_ 1313 STH_Funk_ein 0 "kein Funkbefehl zum Einschalten" 1 "Funkbefehl zum Einschalten erhalten" ;
VAL_ 1313 STH_Funk_aus 0 "kein Funkbefehl" 1 "Funkbefehl zum Ausschalten erhalten" ;
VAL_ 1313 STH_Zusatzheizung 0 "Zuheizer aus" 1 "Zuheizer ein" ;
VAL_ 1313 STH_LED 0 "keine Rückmeldung" 1 "Rueckmeldung Standheizung in Betrieb" ;
VAL_ 1313 STH_Geblaese 0 "kein Einschaltbefehl an die Klimaanlage, Gebläse" 1 "Einschaltbefehl an die Klimaanlage, Gebläse" ;
VAL_ 1313 STH_EKP_Anst 0 "EKP nicht ansteuern" 1 "EKP ansteuern" ;
VAL_ 1313 STH_Start_folgt 0 "kein_Start_folgt" 1 "Start_folgt" ;
VAL_ 1313 STH_Ventil_Status 0 "Ventil_offen__grosser_Kreislauf" 1 "Ventil_geschlossen__kleiner_Kreislauf" ;
VAL_ 1313 STH_Fehler_ElWaPu 0 "kein_Fehler" 1 "Fehler" ;
VAL_ 1313 STH_Pumpen_Anf_extern 0 "nicht_angefordert" 1 "angefordert" ;
VAL_ 1313 STH_Fehlerstatus 0 "kein_Fehler" 1 "Unterspannung" 2 "Tankfuellstand_zu_gering" 3 "Fehler_Betrieb_verhindert" 4 "Heizgeraet_verriegelt" 5 "Fehler_Betrieb_nicht_verhindert" 6 "Emissionsüberschreitung" ;
VAL_ 1313 STH_Wassertemp 254 "Init" 255 "Fehler" ;
VAL_ 1313 STH_Texte 0 "keine_Anzeige" 1 "Batteriemanagementeinschraenkung" 2 "Kraftstoffmangel" 3 "interner_Systemfehler" ;
VAL_ 1313 STH_Motorvorwaermung 0 "keine Motorvorwärmung erfolgt" 1 "Aufheizung mit Motorvorwärmung erfolgt" ;
VAL_ 1313 STH_war_aktiv 0 "war inaktiv" 1 "Standheizung war letzte halbe Stunde aktiv" ;
VAL_ 1313 STH_KVS_Ueberlauf 0 "kein Überlauf" 1 "Kraftstoffverbrauchssignal, mindestens ein Überlauf hat stattgefunden" ;
VAL_ 1650 STH_ZZ_Monat 0 "Init" ;
VAL_ 1650 STH_ZZ_Tag 0 "Init" ;
VAL_ 1650 STH_ZZ_Betriebsmodus 0 "Don_t Care" 1 "ECO" 2 "Standard" 3 "Standard plus" 4 "Comfort" ;
VAL_ 1650 STH_ZZ_Status_Timer 0 "Don_t Care" 1 "Timer n.aktiv bzw loeschen" 2 "Timer aktiv/bzw aktivieren" ;
VAL_ 1172 STS_Car_not_under_theft 0 "false" 1 "true" ;
VAL_ 1172 STS_Car_under_theft 0 "false" 1 "true" ;
VAL_ 1172 STS_Anlassersperre 0 "inaktiv" 1 "aktiv" ;
VAL_ 1172 STS_Typencodierung 0 "Basis" 1 "E-Gas" 4 "Sonderschutz" ;
VAL_ 1172 STS_Standlicht 0 "inaktiv" 1 "aktiv" ;
VAL_ 1172 STS_Fahrlicht 0 "inaktiv" 1 "aktiv" ;
VAL_ 1172 STS_Alarm_still 0 "inaktiv" 1 "aktiv" ;
VAL_ 1172 STS_Texte 0 "kein_Text" 1 "Text_01" 2 "Text_02" 3 "Text_03" 4 "Text_04" 5 "Text_05" 6 "Text_06" 7 "Text_07" 8 "Text_08" 9 "Text_09" 10 "Text_10" 11 "Text_11" 12 "Text_12" 13 "Text_13" 14 "Init" 15 "Fehler" ;
VAL_ 1172 STS_Laderelais 0 "Relais_offen" 1 "Relais_geschlossen" ;
VAL_ 1172 STS_Summer 0 "inaktiv" 1 "aktiv" ;
VAL_ 1172 STS_Notstart 0 "kein_Notstart" 1 "Notstart" ;
VAL_ 1172 STS_Signalhorn 0 "inaktiv" 1 "aktiv" ;
VAL_ 1172 STS_Leerlaufschaltung 0 "inaktiv" 1 "aktiv" ;
VAL_ 783 SWA_Anzeigen 0 "keine_Anzeige" 1 "Text_1_SWA_zurzeit_nicht_verfuegbar" 2 "Text_2_SWA_Systemstoerung" 3 "Text_3_SWA_zurzeit_nicht_verfuegbar_Keine_Sensorsicht" 4 "Text_4_SWA_zurzeit_nicht_verfuegbar_Anhaengerbetrieb" ;
VAL_ 783 SWA_Blindheit_erkannt 0 "nicht erkannt" 1 "erkannt" ;
VAL_ 783 SWA_rel_Nichtverf 0 "verfuegbar" 1 "nicht verfuegbar" ;
VAL_ 783 SWA_rel_Fehler 0 "kein Fehler" 1 "Fehler" ;
VAL_ 783 SWA_Sta_aktiv 0 "Aus" 1 "Ein" ;
VAL_ 783 SWA_Sta_passiv 0 "Aus" 1 "Ein" ;
VAL_ 783 SWA_FT_RueckLED 0 "inaktiv" 1 "aktiv" ;
VAL_ 783 ASW_Status 0 "Passiv" 1 "Aktiv" 2 "Fehler" 3 "AUS" ;
VAL_ 783 SWA_Standziele_li 0 "Abstand i.O." 1 "Abstand zu gering" ;
VAL_ 783 SWA_Kolonne_li 0 "zwei_oder_weniger_Fahrzeuge_auf_der_Spur" 1 "mehr_als_zwei_Fahrzeuge_auf_der_Spur" ;
VAL_ 783 SWA_Infostufe_SWA_li 0 "keine_Aktion" 1 "Aktion" ;
VAL_ 783 SWA_Warnung_SWA_li 0 "keine Warnung" 1 "Warnung aktiv" ;
VAL_ 783 ASW_Warnung_FS 0 "inaktiv" 1 "aktiv" ;
VAL_ 783 ASW_Warnung_BFS 0 "inaktiv" 1 "aktiv" ;
VAL_ 783 ASW_Kombitexte 0 "keine Anzeige.    //    Prio 5" 1 "Text_1_ASW_zur_Zeit_nicht_verfuegbar_und_Akustik    //    Prio 2" 2 "Text_2_ASW_Systemfehler_und_Akustik    //    Prio 1" 3 "Text_3_ASW_Sensor_blockiert_und_Akustik    //    Prio 3" 4 "Text_4_ASW_im_Anhaengerbetrieb_nicht_verfuegbar_und_Akustik    //    Prio 4" 5 "reserviert" 6 "reserviert" 7 "Text_7_Vorhalt_ASW_aus" ;
VAL_ 783 SWA_Kolonne_mi 0 "zwei_oder_weniger_Fahrzeuge_auf_der_Spur" 1 "mehr_als_zwei_Fahrzeuge_auf_der_Spur" ;
VAL_ 783 SWA_Standziele_re 0 "Abstand i.O." 1 "Abstand zu gering" ;
VAL_ 783 SWA_Kolonne_re 0 "zwei_oder_weniger_Fahrzeuge_auf_der_Spur" 1 "mehr_als_zwei_Fahrzeuge_auf_der_Spur" ;
VAL_ 783 SWA_Infostufe_SWA_re 0 "keine_Aktion" 1 "Aktion" ;
VAL_ 783 SWA_Warnung_SWA_re 0 "keine Warnung" 1 "Warnung aktiv" ;
VAL_ 783 HRE_Anzeigetexte 0 "keine Anzeige" 1 "HRE zur Zeit nicht verfügbar" 2 "HRE Systemfehler" 3 "HRE nicht verfügbar. Sensor blockiert" 4 "HRE im Anhängerbetrieb nicht verfügbar" 5 "RTA-Warnung" 6 "BSD-Warnung" 7 "Fahrerübernahme Notbremsung" 8 "RTA nicht verfügbar" ;
VAL_ 783 Heckradar_Kombitexte 0 "keine Anzeige.    //    Prio 5" 1 "Text_1_SWA_und_ASW_zur_Zeit_nicht_verfuegbar_und_Akustik    //    Prio 2" 2 "Text_2_SWA_und_ASW_Systemfehler_und_Akustik    //    Prio 1" 3 "Text_3_SWA_und_ASW_Sensor_blockiert_und_Akustik    //    Prio 3" 4 "Text_4_SWA_und_ASW_im_Anhaengerbetrieb_nicht_verfuegbar_und_Akustik    //    Prio 4" 5 "Text_1_SWA_und_RCTA_zur_Zeit_nicht_verfuegbar_und_Akustik // Prio 2" 6 "Text_2_SWA_und_RCTA_Systemfehler_und_Akustik // Prio 1" 7 "		Text_3_SWA_und_RCTA_Sensor_blockiert_und_Akustik // Prio 3" 8 "Text_4_SWA_und_RCTA_im_Anhaengerbetrieb_nicht_verfuegbar_und_Akustik // Prio 4" 9 "Text_1_ASW_und_RCTA_zur_Zeit_nicht_verfuegbar_und_Akustik // Prio 2" 10 "Text_2_ASW_und_RCTA_Systemfehler_und_Akustik // Prio 1" 11 "Text_3_ASW_und_RCTA_Sensor_blockiert_und_Akustik // Prio 3" 12 "Text_4_ASW_und_RCTA_im_Anhaengerbetrieb_nicht_verfuegbar_und_Akustik // Prio 4" 13 "Text_1_SWA_und_ASW_und_RCTA_zur_Zeit_nicht_verfuegbar_und_Akustik // Prio 2" 14 "Text_2_SWA_und_ASW_und_RCTA_Systemfehler_und_Akustik // Prio 1" 15 "Text_3_SWA_und_ASW_und_RCTA_Sensor_blockiert_und_Akustik // Prio 3" 16 "Text_4_SWA_und_ASW_und_RCTA_im_Anhaengerbetrieb_nicht_verfuegbar_und_Akustik // Prio 4" 17 "reserviert" 18 "reserviert" 19 "reserviert" 20 "reserviert" 21 "reserviert" 22 "reserviert" 23 "reserviert" 24 "reserviert" 25 "reserviert" 26 "reserviert" 27 "reserviert" 28 "reserviert" 29 "reserviert" ;
VAL_ 783 RCTA_Kombitexte 0 "keine Anzeige.    //    Prio 7" 1 "Text_1_RCTA_zur_Zeit_nicht_verfuegbar_und_Akustik    //    Prio 4" 2 "Text_2_RCTA_Systemfehler_und_Akustik    //    Prio 3" 3 "Text_3_RCTA_Sensor_blockiert_und_Akustik    //    Prio 5" 4 "Text_4_RCTA_im_Anhaengerbetrieb_nicht_verfuegbar_und_Akustik    //    Prio 6" 5 "Text_5_RTA_Warnung (VW)    //    Prio 1" 6 "Text_6_Fahreruebernahme_Notbremsung (VW)    //    Prio 2" 7 "reserviert" ;
VAL_ 673 SWA_LED_Hell_BFS 126 "Init" 127 "Fehler" ;
VAL_ 673 SWA_LED_Hell_FS 126 "Init" 127 "Fehler" ;
VAL_ 673 SWA_LED_Modus_BFS 0 "LED_aus" 1 "Infostufe" 2 "Warnstufe" 3 "Aufpruefen_Kl15" 4 "Aufpruefen_BAP" ;
VAL_ 673 SWA_LED_Modus_FS 0 "LED_aus" 1 "Infostufe" 2 "Warnstufe" 3 "Aufpruefen_Kl15" 4 "Aufpruefen_BAP" ;
VAL_ 788 SWA_Obj_03_GeschwRelX 511 "Init" ;
VAL_ 788 SWA_Obj_03_Gemessen 0 "Objekt_praediziert" 1 "Objekt_gemessen" ;
VAL_ 788 SWA_Obj_03_ID 0 "kein_Objekt_enthalten" 31 "Init" ;
VAL_ 788 SWA_Obj_03_PositionX 511 "Init" ;
VAL_ 788 SWA_Obj_03_PositionY 255 "Init" ;
VAL_ 788 SWA_Obj_04_GeschwRelX 511 "Init" ;
VAL_ 788 SWA_Obj_04_Gemessen 0 "Objekt_praediziert" 1 "Objekt_gemessen" ;
VAL_ 788 SWA_Obj_04_ID 0 "kein_Objekt_enthalten" 31 "Init" ;
VAL_ 788 SWA_Obj_04_PositionX 511 "Init" ;
VAL_ 788 SWA_Obj_04_PositionY 255 "Init" ;
VAL_ 1413 SI_Sammel_SG_Fehler 61 "Reserviert" 62 "Overflow" 63 "ungueltig" ;
VAL_ 1413 SI_Diagnose_Aktiv 0 "inaktiv" 1 "aktiv" ;
VAL_ 1413 SI_QRS_Mode 0 "QRS_Messmodus_nicht_aktiv" 1 "QRS_Messmodus_aktiv" ;
VAL_ 1413 SI_T_Mode 0 "Transportmodus_nicht_aktiv" 1 "Transportmodus_aktiv" ;
VAL_ 1413 SI_NWDF 0 "Ueberwachung_nicht_freigegeben" 1 "Ueberwachung_freigegeben" ;
VAL_ 1413 SI_NWDF_gueltig 0 "NWDF_wird_nicht_unterstuetzt" 1 "NWDF_wird_unterstuetzt" ;
VAL_ 1413 SI_Sammelfehler 0 "kein_Sammelfehler" 1 "Sammelfehler" ;
VAL_ 1413 GW_KD_Fehler 0 "kein_KD_Fehler" 1 "KD_Fehler" ;
VAL_ 1413 SI_T_Schutz 0 "Transportschutz_nicht_aktiv" 1 "Transportschutz_aktiv" ;
VAL_ 1413 SI_BUS_01 0 "keine_Busruhe" 1 "Busruhe" ;
VAL_ 1413 SI_BUS_02 0 "keine_Busruhe" 1 "Busruhe" ;
VAL_ 1413 SI_BUS_03 0 "keine_Busruhe" 1 "Busruhe" ;
VAL_ 1413 SI_BUS_04 0 "keine_Busruhe" 1 "Busruhe" ;
VAL_ 1413 SI_BUS_05 0 "keine_Busruhe" 1 "Busruhe" ;
VAL_ 1413 SI_BUS_06 0 "keine_Busruhe" 1 "Busruhe" ;
VAL_ 1413 SI_BUS_07 0 "keine_Busruhe" 1 "Busruhe" ;
VAL_ 1413 SI_BUS_08 0 "keine_Busruhe" 1 "Busruhe" ;
VAL_ 1413 SI_BUS_09 0 "keine_Busruhe" 1 "Busruhe" ;
VAL_ 1413 SI_BUS_10 0 "keine_Busruhe" 1 "Busruhe" ;
VAL_ 1413 SI_BUS_11 0 "keine_Busruhe" 1 "Busruhe" ;
VAL_ 1413 SI_BUS_12 0 "keine_Busruhe" 1 "Busruhe" ;
VAL_ 1413 SI_BUS_13 0 "keine_Busruhe" 1 "Busruhe" ;
VAL_ 1413 SI_BUS_14 0 "keine_Busruhe" 1 "Busruhe" ;
VAL_ 1413 SI_BUS_15 0 "keine_Busruhe" 1 "Busruhe" ;
VAL_ 1413 SI_Bus_Identifikation 16 "CAN_Diagnose" 17 "CAN_Antrieb" 18 "CAN_Komfort" 19 "CAN_Infotainment" 20 "CAN_Fahrwerk" 21 "CAN_Extended" 22 "CAN_Migration" 23 "CAN_Lade" 48 "FlexRay" ;
VAL_ 1413 SI_CAB 1 "CAB_01__Tueren" 2 "CAB_02__Anhaenger" 4 "CAB_03__Nightvision" 8 "CAB_04__Sitzverstellung" 16 "CAB_05__Klappen" 32 "CAB_06__Infotainment" 64 "CAB_07__Sub_Infotainment" 128 "CAB_08__Anzeige" 256 "CAB_09__Laden" ;
VAL_ 1604 TG_Geber_1 0 "Init_bzw_nicht_verbaut" 4095 "Fehler" ;
VAL_ 1604 TG_Geber_2 0 "Init_bzw_nicht_verbaut" 4095 "Fehler" ;
VAL_ 1604 TG_Geber_3 0 "Init_bzw_nicht_verbaut" 4095 "Fehler" ;
VAL_ 1604 TG_Geber_4 0 "Init_bzw_nicht_verbaut" 4095 "Fehler" ;
VAL_ 1604 TG_Guete_Geber_1 12 "Unter_oder_Ueberspannung" 13 "nicht_verbaut" 14 "Init" 15 "Fehler" ;
VAL_ 1604 TG_Guete_Geber_2 12 "Unter_oder_Ueberspannung" 13 "nicht_verbaut" 14 "Init" 15 "Fehler" ;
VAL_ 1604 TG_Guete_Geber_3 12 "Unter_oder_Ueberspannung" 13 "nicht_verbaut" 14 "Init" 15 "Fehler" ;
VAL_ 1604 TG_Guete_Geber_4 12 "Unter_oder_Ueberspannung" 13 "nicht_verbaut" 14 "Init" 15 "Fehler" ;
VAL_ 977 BT_Tuer_geoeffnet 0 "geschlossen" 1 "offen" ;
VAL_ 977 BT_verriegelt 1 "verriegelt" ;
VAL_ 977 BT_gesafet 1 "gesafet" ;
VAL_ 977 BT_Schluesselschalter_auf 1 "Schluesselschalter auf betaetigt" ;
VAL_ 977 BT_Schluesselschalter_zu 1 "Schluesselschalter zu betaetigt" ;
VAL_ 977 BT_Unlock_Taster 1 "Unlock Taster betaetigt" ;
VAL_ 977 BT_Lock_Taster 1 "Lock Taster betaetigt" ;
VAL_ 977 BT_Sperrklinke 0 "Schloss_in_Vorraste_und_Hauptraste" 1 "Tuer_auf_oder_Tuer_Position_zwischen_Vor_und_Hauptraste" ;
VAL_ 977 BT_TAG_betaetigt 1 "Tuerinnengriff_betaetigt" ;
VAL_ 977 BT_TIG_betaetigt 1 "Tuerinnengriff_betaetigt" ;
VAL_ 977 BT_Tuer_Status 0 "Init" 1 "Tuer geschlossen" 2 "Tuer offen" 3 "Fehler" ;
VAL_ 977 BT_TSG_hinten_verbaut 0 "nicht verbaut" 1 "verbaut" ;
VAL_ 977 BT_Sp_Blk_def 0 "iO" 1 "Spiegel Blinker defekt" ;
VAL_ 977 BT_FH_S_ManHoch 1 "FH Schalter man hoch gedrueckt" ;
VAL_ 977 BT_FH_S_AutoHoch 1 "FH Schalter auto hoch gedrueckt" ;
VAL_ 977 BT_FH_S_ManTief 1 "FH Schalter man tief gedrueckt" ;
VAL_ 977 BT_FH_S_AutoTief 1 "FH Schalter auto tief gedrueckt" ;
VAL_ 977 BT_FH_Bew_hoch 1 "FH ist in Bewegung hoch" ;
VAL_ 977 BT_FH_Bew_tief 1 "FH ist in Bewegung tief" ;
VAL_ 977 BT_FH_Fang 0 "ausserhalb_Fangbereich" 1 "innerhalb_Fangbereich" ;
VAL_ 977 BT_FH_Block 1 "Fensterheber_Block" ;
VAL_ 977 BT_FH_Thermo 1 "Thermoschutz_aktiv" ;
VAL_ 977 BT_UEKB_aktiviert 1 "aktiv" ;
VAL_ 977 BT_Kisi_Fehler 0 "kein_Fehler" 1 "Fehler" ;
VAL_ 977 BT_FH_normiert 1 "Fenster_normiert" ;
VAL_ 977 BT_Schliesstaster 1 "betaetigt" ;
VAL_ 977 BT_Zuziehhilfe_aktiv 1 "Zuziehhilfe_aktiv" ;
VAL_ 977 BT_SP_ausgerastet 1 "Spiegel ausgerastet" ;
VAL_ 977 BT_SP_lr_aktiv 1 "Spiegel x-Achse aktiv" ;
VAL_ 977 BT_SP_ht_aktiv 1 "Spiegel y-Achse aktiv" ;
VAL_ 977 BT_SP_Heizung_aktiv 1 "BF Spiegelheizung ein" ;
VAL_ 977 BT_Oben_Block_erw 0 "Fensterheber nicht in Blockerwartung oben" 1 "Fensterheber in Blockerwartung oben" ;
VAL_ 977 BT_Unten_Block_erw 0 "Fensterheber nicht in Blockerwartung unten" 1 "Fensterheber in Blockerwartung unten" ;
VAL_ 977 BT_SP_Heizung_Status 1 "Status Spiegelheizung ein" ;
VAL_ 977 ASW_Warnung_aktiv_BFS 0 "nicht_angefordert" 1 "angefordert" ;
VAL_ 977 BT_FH_Pos_oben 1 "Scheibe oben (nach Absenken auf Position) " ;
VAL_ 977 BT_Tuerschloss_defekt 0 "Tuerschloss funktionsfähig" 1 "Tuerschloss defekt" ;
VAL_ 977 BT_Tuerschloss_verrieg_nicht 0 "Tür kann verriegelt werden" 1 "Tür kann nicht verriegelt werden" ;
VAL_ 977 BT_Lock_Taster_inv 0 "Lock Taster betätigt" 1 "Lock Taster nicht betätigt" ;
VAL_ 977 BT_Schluesselschalter_zu_inv 0 "Schlüsselschalter betätigt" 1 "Schlüsselschalter nicht betätigt" ;
VAL_ 1451 TSG_FlHz_BFS_NTC_A 125 "Fehler_NTC_OpenLoad__KS_Plus" 126 "Fehler_NTC_Overload__KS_Minus" 127 "Init" ;
VAL_ 1451 TSG_FlHz_BFS_FnAbbruchHzKreis_A 0 "OK" 1 "FunktionsAbbruch" ;
VAL_ 1451 TSG_FlHz_BFS_NTC_B 125 "Fehler_NTC_OpenLoad__KS_Plus" 126 "Fehler_NTC_Overload__KS_Minus" 127 "Init" ;
VAL_ 1451 TSG_FlHz_BFS_FnAbbruchHzKreis_B 0 "OK" 1 "FunktionsAbbruch" ;
VAL_ 976 FT_Tuer_geoeffnet 1 "Tuer offen" ;
VAL_ 976 FT_verriegelt 1 "verriegelt" ;
VAL_ 976 FT_gesafet 1 "gesafet" ;
VAL_ 976 FT_Schluesselschalter_auf 1 "Schluesselschalter auf betaetigt" ;
VAL_ 976 FT_Schluesselschalter_zu 1 "Schluesselschalter zu betaetigt" ;
VAL_ 976 FT_Unlock_Taster 1 "Unlock Taster betaetigt" ;
VAL_ 976 FT_Lock_Taster 1 "Lock Taster betaetigt" ;
VAL_ 976 FT_Sperrklinke 0 "Schloss_in_Vorraste_und_Hauptraste" 1 "Tuer_auf_oder_Tuer_Position_zwischen_Vor_und_Hauptraste" ;
VAL_ 976 FT_TAG_betaetigt 0 "nicht_betaetigt" 1 "betaetigt" ;
VAL_ 976 FT_TIG_betaetigt 0 "nicht_betaetigt" 1 "betaetigt" ;
VAL_ 976 FT_IRUE_Taste 1 "IRUE Taste betaetigt" ;
VAL_ 976 FT_HD_Taste 1 "Heckdeckel oeffnen" ;
VAL_ 976 FT_TD_Taste_Fehler 0 "iO" 1 "defekt" ;
VAL_ 976 FT_TD_Taste 1 "Tankdeckelentriegelungs Taster gedrückt" ;
VAL_ 976 SSR_Temp_Freigabe 0 "SSR_Deaktiviert" 1 "SSR_Freigegeben" ;
VAL_ 976 FT_HD_Taste_2 0 "Taste_nicht_gedrueckt" 1 "Taste_gedrueckt" ;
VAL_ 976 FT_TSG_hinten_verbaut 0 "nicht verbaut" 1 "verbaut" ;
VAL_ 976 FT_Sp_Blk_def 0 "iO" 1 "defekt" ;
VAL_ 976 FT_FH_S_ManHoch 1 "FH Schalter man hoch betaetigt" ;
VAL_ 976 FT_FH_S_AutoHoch 1 "FH Schalter auto hoch betaetigt" ;
VAL_ 976 FT_FH_S_ManTief 1 "FH Schalter man tief betaetigt" ;
VAL_ 976 FT_FH_S_AutoTief 1 "FH Schalter auto tief betaetigt" ;
VAL_ 976 FT_FH_Bew_hoch 1 "FH in Bewegung hoch" ;
VAL_ 976 FT_FH_Bew_tief 1 "FH in Bewegung tief" ;
VAL_ 976 FT_FH_Fang 0 "ausserhalb_Fangbereich" 1 "innerhalb_Fangbereich" ;
VAL_ 976 FT_FH_Block 1 "Fenster_Block" ;
VAL_ 976 FT_FH_Thermo 1 "Thermoschutz_aktiv" ;
VAL_ 976 FT_UEKB_aktiviert 1 "UEKB_aktiv" ;
VAL_ 976 ASW_HMI_defekt 0 "iO" 1 "defekt" ;
VAL_ 976 FT_FH_normiert 1 "Fenster_normiert" ;
VAL_ 976 FT_Schliesstaster 1 "Schliesstaster_betaetigt" ;
VAL_ 976 FT_Zuziehhilfe_aktiv 1 "Zuziehilfe_aktiv" ;
VAL_ 976 FT_SP_ausgerastet 1 "Spiegel ausgerastet" ;
VAL_ 976 FT_SP_lr_aktiv 1 "Spiegel x-Achse aktiv" ;
VAL_ 976 FT_SP_ht_aktiv 1 "Spiegel y-Achse aktiv" ;
VAL_ 976 ASW_wakeup 0 "Sleep" 1 "Wakeup" ;
VAL_ 976 FT_Oben_Block_erw 0 "Fensterheber nicht in Blockerwartung oben" 1 "Fensterheber in Blockerwartung oben" ;
VAL_ 976 FT_Unten_Block_erw 0 "Fensterheber nicht in Blockerwartung unten" 1 "Fensterheber in Blockerwartung unten" ;
VAL_ 976 FT_Kisi_li_aktiv 0 "inaktiv" 1 "aktiv" ;
VAL_ 976 FT_Kisi_re_aktiv 0 "inaktiv" 1 "aktiv" ;
VAL_ 976 FT_Kisi_Taster_li 0 "nicht_betaetigt" 1 "betaetigt" ;
VAL_ 976 FT_Kisi_Taster_re 0 "nicht_betaetigt" 1 "betaetigt" ;
VAL_ 976 FT_BFS_Fond_Freigabe 0 "Init" 1 "Freigabe_fuer_Fondbedienung_BFS" ;
VAL_ 976 FT_Kisi_Fehler 0 "kein_Fehler" 1 "Fehler" ;
VAL_ 976 FT_Daemmglas 0 "Normalglas verbaut " 1 "Daemmglas verbaut" ;
VAL_ 976 FT_SP_Heizung_Status 1 "Status Spiegelheizung ein" ;
VAL_ 976 ASW_Warnung_aktiv_FS 0 "nicht_angefordert" 1 "angefordert" ;
VAL_ 976 FT_FH_Pos_oben 1 "Scheibe oben (nach Absenken auf Position) " ;
VAL_ 976 FT_Tuerschloss_defekt 0 "Tuerschloss_funktionsfaehig" 1 "Tuerschloss_defekt" ;
VAL_ 976 FT_SWA_Taster 0 "Taster_nicht_betaetigt" 1 "Taster_betaetigt" ;
VAL_ 976 SWA_HMI_Diagnose 0 "kein_Fehler_erkannt" 1 "Fehler_Taster_erkannt" 2 "Fehler_LED_erkannt" 3 "Fehler_LED_und_Taster_erkannt" ;
VAL_ 997 FT_Tuer_Status 0 "Init" 1 "Tuer_geschlossen" 2 "Tuer_offen" 3 "Fehler" ;
VAL_ 997 FT_Tuer_Status_QBit 0 "Status_Tuerkontakt_sicher" 1 "Status_Tuerkontakt_unsicher" ;
VAL_ 997 FT_Lock_Taster_02 0 "nicht_betaetigt" 1 "betaetigt" ;
VAL_ 997 FT_Schluesselschalter_zu_02 0 "nicht_betaetigt" 1 "betaetigt" ;
VAL_ 997 FT_BFS_Tuer_Status 0 "Init" 1 "Tuer_geschlossen" 2 "Tuer_offen" 3 "Fehler" ;
VAL_ 997 FT_HBFS_Tuer_Status 0 "Init" 1 "Tuer geschlossen" 2 "Tuer offen" 3 "Fehler" ;
VAL_ 997 FT_HFS_Tuer_Status 0 "Init" 1 "Tuer geschlossen" 2 "Tuer offen" 3 "Fehler" ;
VAL_ 997 FT_Tuerschloss_verrieg_nicht 0 "Türschloss kann verriegelt werden" 1 "Türschloss kann nicht verriegelt werden" ;
VAL_ 997 FT_SP_Heizung_ein 0 "Aus" 1 "Ein" ;
VAL_ 997 FT_Kisi_Taster_li_02 0 "nicht_betaetigt" 1 "betaetigt" ;
VAL_ 997 FT_Kisi_Taster_re_02 0 "nicht_betaetigt" 1 "betaetigt" ;
VAL_ 997 FT_TD_Taste_Status 0 "kein_Fehler" 1 "Kurzschluss_nach_Minus" 2 "Kurzschluss_nach_Plus" 3 "Leitungsunterbrechung" ;
VAL_ 1449 TSG_FlHz_FS_NTC_A 125 "Fehler_NTC_OpenLoad__KS_Plus" 126 "Fehler_NTC_Overload__KS_Minus" 127 "Init" ;
VAL_ 1449 TSG_FlHz_FS_FnAbbruchHzKreis_A 0 "OK" 1 "FunktionsAbbruch" ;
VAL_ 1449 TSG_FlHz_FS_NTC_B 125 "Fehler_NTC_OpenLoad__KS_Plus" 126 "Fehler_NTC_Overload__KS_Minus" 127 "Init" ;
VAL_ 1449 TSG_FlHz_FS_FnAbbruchHzKreis_B 0 "OK" 1 "FunktionsAbbruch" ;
